VERSION "HNNBNNNYNNNNNNNNNNNNNNNNNNNNNNNNNNNNNNNNNN/4/%%%/4/'%**4NNN///"

NS_ :

BS_:

BU_: Airbag Allrad_Haldex BAP_Tester DCC_Gen3 EBKV_MQBW ESC_MQBW Gateway_Max Lenkhilfe_REPS

BO_ 2463978666 Motor_57: 32 Gateway_Max
 SG_ Motor_57_CRC : 0|8@1+ (1,0) [0|255] ""  Vector__XXX
 SG_ Motor_57_BZ : 8|4@1+ (1,0) [0|15] ""  Vector__XXX
 SG_ MO_EM1_Min_Spannung_Lim : 12|10@1+ (1,0) [0|1021] "Unit_Volt"  Vector__XXX
 SG_ MO_EM1_Max_Spannung_Lim : 22|10@1+ (1,0) [0|1021] "Unit_Volt"  Vector__XXX
 SG_ MO_EM1_Min_Leistung_Gesamt : 32|13@1+ (200,-819000) [-819000|818800] "Unit_Watt"  Vector__XXX
 SG_ MO_EM1_Max_Leistung_Gesamt : 45|13@1+ (200,-819000) [-819000|818800] "Unit_Watt"  Vector__XXX
 SG_ MO_EM2_Min_Leistung_Gesamt : 58|13@1+ (200,-819000) [-819000|818800] "Unit_Watt"  Vector__XXX
 SG_ MO_EM2_Max_Leistung_Gesamt : 71|13@1+ (200,-819000) [-819000|818800] "Unit_Watt"  Vector__XXX
 SG_ MO_EM2_Min_Spannung_Lim : 84|10@1+ (1,0) [0|1021] "Unit_Volt"  Vector__XXX
 SG_ MO_EM2_Max_Spannung_Lim : 94|10@1+ (1,0) [0|1021] "Unit_Volt"  Vector__XXX
 SG_ MO_EM1_Generator_Leistung : 104|8@1+ (100,0) [0|25300] "Unit_Watt"  Vector__XXX
 SG_ MO_EM2_Generator_Leistung : 112|8@1+ (100,0) [0|25300] "Unit_Watt"  Vector__XXX
 SG_ MO_Verbrauch_EM_Ges : 120|15@1+ (10,0) [0|327670] "Unit_WattSecond"  Vector__XXX
 SG_ MO_Verbrauch_EM_Ges_Ueberlauf : 135|1@1+ (1.0,0.0) [0.0|1] ""  Vector__XXX
 SG_ MO_Rekuperation_Ges_EM : 136|15@1+ (10,0) [0|327670] "Unit_WattSecond"  Vector__XXX
 SG_ MO_Rekuperation_EM_Ges_Ueberlauf : 151|1@1+ (1.0,0.0) [0.0|1] ""  Vector__XXX
 SG_ MO_Drehzahl_EM : 152|13@1+ (8,-32768) [-32768|32744] "Unit_RevPerMinute"  Airbag
 SG_ MO_Uebersetzung_EM : 165|10@1+ (0.03125,0) [0.03125|31.90625] ""  Vector__XXX
 SG_ MO_Drehzahl_EM_sek : 175|13@1+ (8,-32768) [-32768|32744] "Unit_RevPerMinute"  Airbag
 SG_ MO_Uebersetzung_EM_sek : 188|10@1+ (0.03125,0) [0.03125|31.90625] ""  Vector__XXX
 SG_ MO_TNW_Min_Spannung_Lim : 198|10@1+ (1,0) [0|1021] "Unit_Volt"  Vector__XXX
 SG_ MO_TNW_Max_Spannung_Lim : 208|10@1+ (1,0) [0|1021] "Unit_Volt"  Vector__XXX

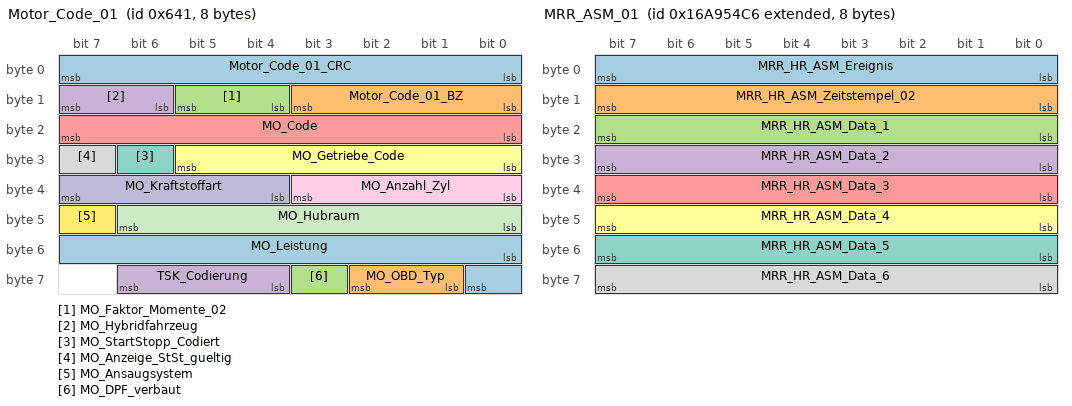
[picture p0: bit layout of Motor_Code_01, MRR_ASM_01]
BO_ 1601 Motor_Code_01: 8 Gateway_Max
 SG_ Motor_Code_01_CRC : 0|8@1+ (1,0) [0|255] ""  ESC_MQBW
 SG_ Motor_Code_01_BZ : 8|4@1+ (1,0) [0|15] ""  ESC_MQBW
 SG_ MO_Faktor_Momente_02 : 12|2@1+ (1,0) [1|3] "Unit_NewtoMeter"  Allrad_Haldex,DCC_Gen3,ESC_MQBW,Lenkhilfe_REPS
 SG_ MO_Hybridfahrzeug : 14|2@1+ (1.0,0.0) [0.0|3] ""  Vector__XXX
 SG_ MO_Code : 16|8@1+ (1,0) [0|255] ""  Vector__XXX
 SG_ MO_Getriebe_Code : 24|6@1+ (1.0,0.0) [0.0|63] ""  ESC_MQBW
 SG_ MO_StartStopp_Codiert : 30|1@1+ (1.0,0.0) [0.0|1] ""  ESC_MQBW
 SG_ MO_Anzeige_StSt_gueltig : 31|1@1+ (1.0,0.0) [0.0|1] ""  Vector__XXX
 SG_ MO_Anzahl_Zyl : 32|4@1+ (1.0,0.0) [0.0|15] ""  ESC_MQBW
 SG_ MO_Kraftstoffart : 36|4@1+ (1.0,0.0) [0.0|15] ""  Allrad_Haldex,ESC_MQBW
 SG_ MO_Hubraum : 40|7@1+ (0.1,0) [0.0|12.7] "Unit_Liter"  Vector__XXX
 SG_ MO_Ansaugsystem : 47|1@1+ (1.0,0.0) [0.0|1] ""  Vector__XXX
 SG_ MO_Leistung : 48|9@1+ (1,0) [0|511] "Unit_KiloWatt"  Allrad_Haldex
 SG_ MO_OBD_Typ : 57|2@1+ (1.0,0.0) [0.0|3] ""  EBKV_MQBW,ESC_MQBW
 SG_ MO_DPF_verbaut : 59|1@1+ (1.0,0.0) [0.0|1] ""  Vector__XXX
 SG_ TSK_Codierung : 60|3@1+ (1.0,0.0) [0.0|7] ""  Airbag

BO_ 2527679686 MRR_ASM_01: 8 Gateway_Max
 SG_ MRR_HR_ASM_Ereignis : 0|8@1+ (1,0) [1|254] ""  Airbag
 SG_ MRR_HR_ASM_Zeitstempel_02 : 8|8@1+ (0.04,0) [0.00|10.16] "Unit_Secon"  Airbag
 SG_ MRR_HR_ASM_Data_1 : 16|8@1+ (1,0) [0|255] ""  Airbag
 SG_ MRR_HR_ASM_Data_2 : 24|8@1+ (1,0) [0|255] ""  Airbag
 SG_ MRR_HR_ASM_Data_3 : 32|8@1+ (1,0) [0|255] ""  Airbag
 SG_ MRR_HR_ASM_Data_4 : 40|8@1+ (1,0) [0|255] ""  Airbag
 SG_ MRR_HR_ASM_Data_5 : 48|8@1+ (1,0) [0|255] ""  Airbag
 SG_ MRR_HR_ASM_Data_6 : 56|8@1+ (1,0) [0|255] ""  Airbag

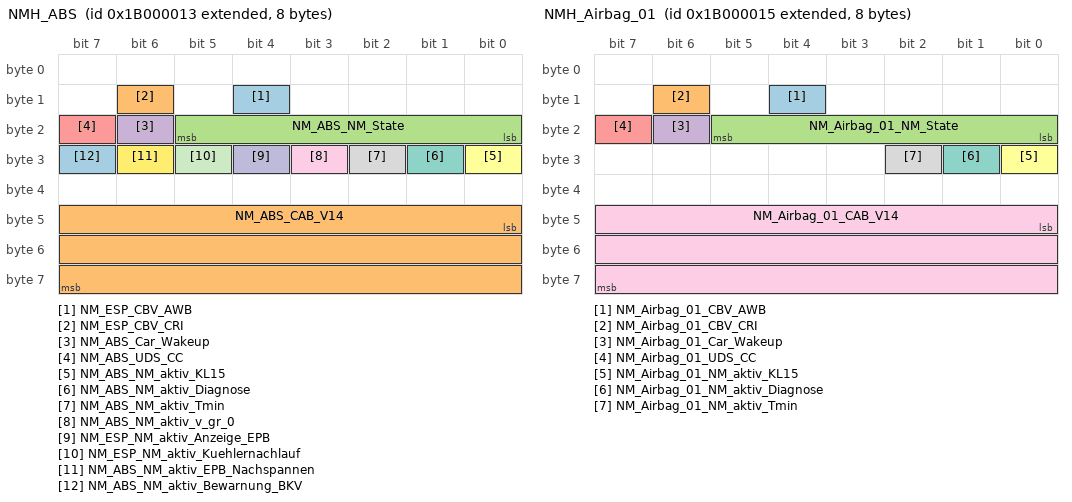
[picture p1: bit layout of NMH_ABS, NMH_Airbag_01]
BO_ 2600468499 NMH_ABS: 8 ESC_MQBW
 SG_ NM_ESP_CBV_AWB : 12|1@1+ (1.0,0.0) [0.0|1] ""  Gateway_Max
 SG_ NM_ESP_CBV_CRI : 14|1@1+ (1.0,0.0) [0.0|1] ""  Gateway_Max
 SG_ NM_ABS_NM_State : 16|6@1+ (1.0,0.0) [0.0|63] ""  Airbag,DCC_Gen3,EBKV_MQBW,Lenkhilfe_REPS
 SG_ NM_ABS_Car_Wakeup : 22|1@1+ (1.0,0.0) [0.0|1] ""  Gateway_Max
 SG_ NM_ABS_UDS_CC : 23|1@1+ (1.0,0.0) [0.0|1] ""  Vector__XXX
 SG_ NM_ABS_NM_aktiv_KL15 : 24|1@1+ (1.0,0.0) [0.0|1] ""  Vector__XXX
 SG_ NM_ABS_NM_aktiv_Diagnose : 25|1@1+ (1.0,0.0) [0.0|1] ""  Vector__XXX
 SG_ NM_ABS_NM_aktiv_Tmin : 26|1@1+ (1.0,0.0) [0.0|1] ""  Vector__XXX
 SG_ NM_ABS_NM_aktiv_v_gr_0 : 27|1@1+ (1.0,0.0) [0.0|1] ""  Vector__XXX
 SG_ NM_ESP_NM_aktiv_Anzeige_EPB : 28|1@1+ (1.0,0.0) [0.0|1] ""  Vector__XXX
 SG_ NM_ESP_NM_aktiv_Kuehlernachlauf : 29|1@1+ (1.0,0.0) [0.0|1] ""  Vector__XXX
 SG_ NM_ABS_NM_aktiv_EPB_Nachspannen : 30|1@1+ (1.0,0.0) [0.0|1] ""  Vector__XXX
 SG_ NM_ABS_NM_aktiv_Bewarnung_BKV : 31|1@1+ (1.0,0.0) [0.0|1] ""  Vector__XXX
 SG_ NM_ABS_CAB_V14 : 40|24@1+ (1.0,0.0) [0.0|16777215] ""  Gateway_Max

BO_ 2600468501 NMH_Airbag_01: 8 Airbag
 SG_ NM_Airbag_01_CBV_AWB : 12|1@1+ (1.0,0.0) [0.0|1] ""  Gateway_Max
 SG_ NM_Airbag_01_CBV_CRI : 14|1@1+ (1.0,0.0) [0.0|1] ""  Gateway_Max
 SG_ NM_Airbag_01_NM_State : 16|6@1+ (1.0,0.0) [0.0|63] ""  DCC_Gen3,EBKV_MQBW,ESC_MQBW,Lenkhilfe_REPS
 SG_ NM_Airbag_01_Car_Wakeup : 22|1@1+ (1.0,0.0) [0.0|1] ""  Gateway_Max
 SG_ NM_Airbag_01_UDS_CC : 23|1@1+ (1.0,0.0) [0.0|1] ""  Vector__XXX
 SG_ NM_Airbag_01_NM_aktiv_KL15 : 24|1@1+ (1.0,0.0) [0.0|1] ""  Vector__XXX
 SG_ NM_Airbag_01_NM_aktiv_Diagnose : 25|1@1+ (1.0,0.0) [0.0|1] ""  Vector__XXX
 SG_ NM_Airbag_01_NM_aktiv_Tmin : 26|1@1+ (1.0,0.0) [0.0|1] ""  Vector__XXX
 SG_ NM_Airbag_01_CAB_V14 : 40|24@1+ (1.0,0.0) [0.0|16777215] ""  Gateway_Max

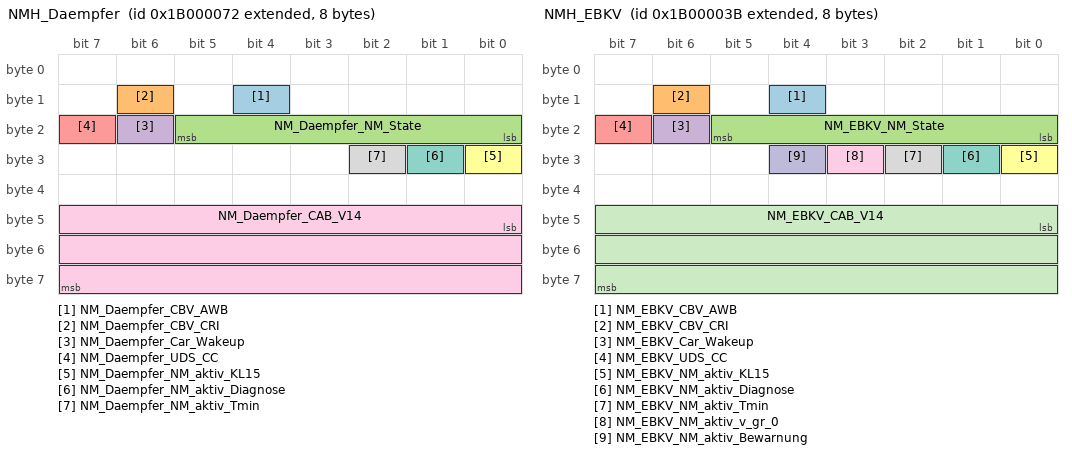
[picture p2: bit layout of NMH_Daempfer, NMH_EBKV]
BO_ 2600468594 NMH_Daempfer: 8 DCC_Gen3
 SG_ NM_Daempfer_CBV_AWB : 12|1@1+ (1.0,0.0) [0.0|1] ""  Gateway_Max
 SG_ NM_Daempfer_CBV_CRI : 14|1@1+ (1.0,0.0) [0.0|1] ""  Gateway_Max
 SG_ NM_Daempfer_NM_State : 16|6@1+ (1.0,0.0) [0.0|63] ""  Airbag,EBKV_MQBW,ESC_MQBW,Lenkhilfe_REPS
 SG_ NM_Daempfer_Car_Wakeup : 22|1@1+ (1.0,0.0) [0.0|1] ""  Gateway_Max
 SG_ NM_Daempfer_UDS_CC : 23|1@1+ (1.0,0.0) [0.0|1] ""  Vector__XXX
 SG_ NM_Daempfer_NM_aktiv_KL15 : 24|1@1+ (1.0,0.0) [0.0|1] ""  Vector__XXX
 SG_ NM_Daempfer_NM_aktiv_Diagnose : 25|1@1+ (1.0,0.0) [0.0|1] ""  Vector__XXX
 SG_ NM_Daempfer_NM_aktiv_Tmin : 26|1@1+ (1.0,0.0) [0.0|1] ""  Vector__XXX
 SG_ NM_Daempfer_CAB_V14 : 40|24@1+ (1.0,0.0) [0.0|16777215] ""  Gateway_Max

BO_ 2600468539 NMH_EBKV: 8 EBKV_MQBW
 SG_ NM_EBKV_CBV_AWB : 12|1@1+ (1.0,0.0) [0.0|1] ""  Gateway_Max
 SG_ NM_EBKV_CBV_CRI : 14|1@1+ (1.0,0.0) [0.0|1] ""  Gateway_Max
 SG_ NM_EBKV_NM_State : 16|6@1+ (1.0,0.0) [0.0|63] ""  Airbag,DCC_Gen3,ESC_MQBW,Lenkhilfe_REPS
 SG_ NM_EBKV_Car_Wakeup : 22|1@1+ (1.0,0.0) [0.0|1] ""  Gateway_Max
 SG_ NM_EBKV_UDS_CC : 23|1@1+ (1.0,0.0) [0.0|1] ""  Vector__XXX
 SG_ NM_EBKV_NM_aktiv_KL15 : 24|1@1+ (1.0,0.0) [0.0|1] ""  Vector__XXX
 SG_ NM_EBKV_NM_aktiv_Diagnose : 25|1@1+ (1.0,0.0) [0.0|1] ""  Vector__XXX
 SG_ NM_EBKV_NM_aktiv_Tmin : 26|1@1+ (1.0,0.0) [0.0|1] ""  Vector__XXX
 SG_ NM_EBKV_NM_aktiv_v_gr_0 : 27|1@1+ (1.0,0.0) [0.0|1] ""  Vector__XXX
 SG_ NM_EBKV_NM_aktiv_Bewarnung : 28|1@1+ (1.0,0.0) [0.0|1] ""  Vector__XXX
 SG_ NM_EBKV_CAB_V14 : 40|24@1+ (1.0,0.0) [0.0|16777215] ""  Gateway_Max

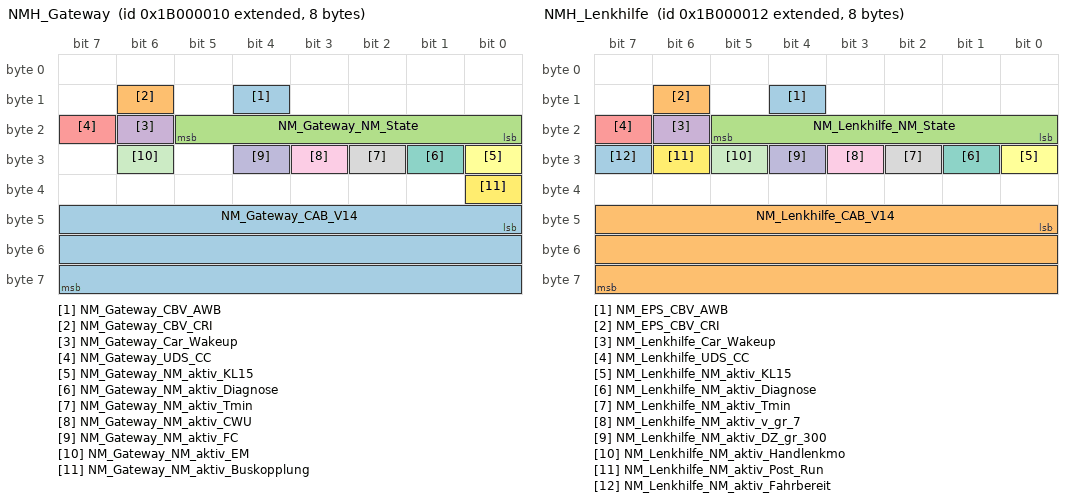
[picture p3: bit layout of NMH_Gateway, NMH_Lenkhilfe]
BO_ 2600468496 NMH_Gateway: 8 Gateway_Max
 SG_ NM_Gateway_CBV_AWB : 12|1@1+ (1.0,0.0) [0.0|1] ""  Vector__XXX
 SG_ NM_Gateway_CBV_CRI : 14|1@1+ (1.0,0.0) [0.0|1] ""  Vector__XXX
 SG_ NM_Gateway_NM_State : 16|6@1+ (1.0,0.0) [0.0|63] ""  Airbag,DCC_Gen3,EBKV_MQBW,ESC_MQBW,Lenkhilfe_REPS
 SG_ NM_Gateway_Car_Wakeup : 22|1@1+ (1.0,0.0) [0.0|1] ""  Vector__XXX
 SG_ NM_Gateway_UDS_CC : 23|1@1+ (1.0,0.0) [0.0|1] ""  Vector__XXX
 SG_ NM_Gateway_NM_aktiv_KL15 : 24|1@1+ (1.0,0.0) [0.0|1] ""  Vector__XXX
 SG_ NM_Gateway_NM_aktiv_Diagnose : 25|1@1+ (1.0,0.0) [0.0|1] ""  Vector__XXX
 SG_ NM_Gateway_NM_aktiv_Tmin : 26|1@1+ (1.0,0.0) [0.0|1] ""  Vector__XXX
 SG_ NM_Gateway_NM_aktiv_CWU : 27|1@1+ (1.0,0.0) [0.0|1] ""  Vector__XXX
 SG_ NM_Gateway_NM_aktiv_FC : 28|1@1+ (1.0,0.0) [0.0|1] ""  Vector__XXX
 SG_ NM_Gateway_NM_aktiv_EM : 30|1@1+ (1.0,0.0) [0.0|1] ""  Vector__XXX
 SG_ NM_Gateway_NM_aktiv_Buskopplung : 32|1@1+ (1.0,0.0) [0.0|1] ""  Vector__XXX
 SG_ NM_Gateway_CAB_V14 : 40|24@1+ (1.0,0.0) [0.0|16777215] ""  Vector__XXX

BO_ 2600468498 NMH_Lenkhilfe: 8 Lenkhilfe_REPS
 SG_ NM_EPS_CBV_AWB : 12|1@1+ (1.0,0.0) [0.0|1] ""  Gateway_Max
 SG_ NM_EPS_CBV_CRI : 14|1@1+ (1.0,0.0) [0.0|1] ""  Gateway_Max
 SG_ NM_Lenkhilfe_NM_State : 16|6@1+ (1.0,0.0) [0.0|63] ""  Airbag,DCC_Gen3,EBKV_MQBW,ESC_MQBW
 SG_ NM_Lenkhilfe_Car_Wakeup : 22|1@1+ (1.0,0.0) [0.0|1] ""  Gateway_Max
 SG_ NM_Lenkhilfe_UDS_CC : 23|1@1+ (1.0,0.0) [0.0|1] ""  Vector__XXX
 SG_ NM_Lenkhilfe_NM_aktiv_KL15 : 24|1@1+ (1.0,0.0) [0.0|1] ""  Vector__XXX
 SG_ NM_Lenkhilfe_NM_aktiv_Diagnose : 25|1@1+ (1.0,0.0) [0.0|1] ""  Vector__XXX
 SG_ NM_Lenkhilfe_NM_aktiv_Tmin : 26|1@1+ (1.0,0.0) [0.0|1] ""  Vector__XXX
 SG_ NM_Lenkhilfe_NM_aktiv_v_gr_7 : 27|1@1+ (1.0,0.0) [0.0|1] ""  Vector__XXX
 SG_ NM_Lenkhilfe_NM_aktiv_DZ_gr_300 : 28|1@1+ (1.0,0.0) [0.0|1] ""  Vector__XXX
 SG_ NM_Lenkhilfe_NM_aktiv_Handlenkmo : 29|1@1+ (1.0,0.0) [0.0|1] ""  Vector__XXX
 SG_ NM_Lenkhilfe_NM_aktiv_Post_Run : 30|1@1+ (1.0,0.0) [0.0|1] ""  Vector__XXX
 SG_ NM_Lenkhilfe_NM_aktiv_Fahrbereit : 31|1@1+ (1.0,0.0) [0.0|1] ""  Vector__XXX
 SG_ NM_Lenkhilfe_CAB_V14 : 40|24@1+ (1.0,0.0) [0.0|16777215] ""  Gateway_Max

BO_ 2621440531 OBDC_ABS_Req_FD: 64 Gateway_Max
 SG_ OBDC_ABS_Req_FD_Data : 0|512@1+ (1.0,0.0) [0.0|13407807929942597099574024998205846127479365820592393377723561443721764030073546976801874298166903427690031858186486050853753882811946569946433649006084095] ""  ESC_MQBW

BO_ 2621571603 OBDC_ABS_Resp_FD: 64 ESC_MQBW
 SG_ OBDC_ABS_Resp_FD_Data : 0|512@1+ (1.0,0.0) [0.0|13407807929942597099574024998205846127479365820592393377723561443721764030073546976801874298166903427690031858186486050853753882811946569946433649006084095] ""  Gateway_Max

BO_ 2621440533 OBDC_Airbag_01_Req_FD: 64 Gateway_Max
 SG_ OBDC_Airbag_01_Req_FD_Data : 0|512@1+ (1.0,0.0) [0.0|13407807929942597099574024998205846127479365820592393377723561443721764030073546976801874298166903427690031858186486050853753882811946569946433649006084095] ""  Airbag

BO_ 2621571605 OBDC_Airbag_01_Resp_FD: 64 Airbag
 SG_ OBDC_Airbag_01_Resp_FD_Data : 0|512@1+ (1.0,0.0) [0.0|13407807929942597099574024998205846127479365820592393377723561443721764030073546976801874298166903427690031858186486050853753882811946569946433649006084095] ""  Gateway_Max

BO_ 2621440527 OBDC_Allrad_Req_FD: 64 Gateway_Max
 SG_ OBDC_Allrad_Req_FD_Data : 0|512@1+ (1.0,0.0) [0.0|13407807929942597099574024998205846127479365820592393377723561443721764030073546976801874298166903427690031858186486050853753882811946569946433649006084095] ""  Allrad_Haldex

BO_ 2621571599 OBDC_Allrad_Resp_FD: 64 Allrad_Haldex
 SG_ OBDC_Allrad_Resp_FD_Data : 0|512@1+ (1.0,0.0) [0.0|13407807929942597099574024998205846127479365820592393377723561443721764030073546976801874298166903427690031858186486050853753882811946569946433649006084095] ""  Gateway_Max

BO_ 2621440626 OBDC_Daempfer_Req_FD: 64 Gateway_Max
 SG_ OBDC_Daempfer_Req_FD_Data : 0|512@1+ (1.0,0.0) [0.0|13407807929942597099574024998205846127479365820592393377723561443721764030073546976801874298166903427690031858186486050853753882811946569946433649006084095] ""  DCC_Gen3

BO_ 2621571698 OBDC_Daempfer_Resp_FD: 64 DCC_Gen3
 SG_ OBDC_Daempfer_Resp_FD_Data : 0|512@1+ (1.0,0.0) [0.0|13407807929942597099574024998205846127479365820592393377723561443721764030073546976801874298166903427690031858186486050853753882811946569946433649006084095] ""  Gateway_Max

BO_ 2621440571 OBDC_EBKV_Req_FD: 64 Gateway_Max
 SG_ OBDC_EBKV_Req_FD_Data : 0|512@1+ (1.0,0.0) [0.0|13407807929942597099574024998205846127479365820592393377723561443721764030073546976801874298166903427690031858186486050853753882811946569946433649006084095] ""  EBKV_MQBW

BO_ 2621571643 OBDC_EBKV_Resp_FD: 64 EBKV_MQBW
 SG_ OBDC_EBKV_Resp_FD_Data : 0|512@1+ (1.0,0.0) [0.0|13407807929942597099574024998205846127479365820592393377723561443721764030073546976801874298166903427690031858186486050853753882811946569946433649006084095] ""  Gateway_Max

BO_ 2621506048 OBDC_Funktionaler_Req_All_FD: 64 Gateway_Max
 SG_ OBDC_Funktion_Req_All_FD_Data : 0|512@1+ (1.0,0.0) [0.0|13407807929942597099574024998205846127479365820592393377723561443721764030073546976801874298166903427690031858186486050853753882811946569946433649006084095] ""  Airbag,Allrad_Haldex,DCC_Gen3,EBKV_MQBW,ESC_MQBW,Lenkhilfe_REPS

BO_ 2621440530 OBDC_Lenkhilfe_Req_FD: 64 Gateway_Max
 SG_ OBDC_Lenkhilfe_Req_FD_Data : 0|512@1+ (1.0,0.0) [0.0|13407807929942597099574024998205846127479365820592393377723561443721764030073546976801874298166903427690031858186486050853753882811946569946433649006084095] ""  Lenkhilfe_REPS

BO_ 2621571602 OBDC_Lenkhilfe_Resp_FD: 64 Lenkhilfe_REPS
 SG_ OBDC_Lenkhilfe_Resp_FD_Data : 0|512@1+ (1.0,0.0) [0.0|13407807929942597099574024998205846127479365820592393377723561443721764030073546976801874298166903427690031858186486050853753882811946569946433649006084095] ""  Gateway_Max

BO_ 2621440542 OBDC_Quersperre_Req_FD: 64 Gateway_Max
 SG_ OBDC_Quersperre_Req_FD_Data : 0|512@1+ (1.0,0.0) [0.0|13407807929942597099574024998205846127479365820592393377723561443721764030073546976801874298166903427690031858186486050853753882811946569946433649006084095] ""  Vector__XXX

BO_ 2621571614 OBDC_Quersperre_Resp_FD: 64 Vector__XXX
 SG_ OBDC_Quersperre_Resp_FD_Data : 0|512@1+ (1.0,0.0) [0.0|13407807929942597099574024998205846127479365820592393377723561443721764030073546976801874298166903427690031858186486050853753882811946569946433649006084095] ""  Gateway_Max

BO_ 2621469190 OBDC_SSN_eCS_Req_FD: 64 Gateway_Max
 SG_ OBDC_SSN_eCS_Req_FD_Data : 0|512@1+ (1.0,0.0) [0.0|13407807929942597099574024998205846127479365820592393377723561443721764030073546976801874298166903427690031858186486050853753882811946569946433649006084095] ""  Vector__XXX

BO_ 2621600262 OBDC_SSN_eCS_Resp_FD: 64 Vector__XXX
 SG_ OBDC_SSN_eCS_Resp_FD_Data : 0|512@1+ (1.0,0.0) [0.0|13407807929942597099574024998205846127479365820592393377723561443721764030073546976801874298166903427690031858186486050853753882811946569946433649006084095] ""  Gateway_Max

BO_ 2549903646 OBDC_SSN_RGS_HL_Req: 8 Gateway_Max
 SG_ OBDC_SSN_RGS_HL_Req_Data : 0|64@1+ (1.0,0.0) [0.0|18446744073709551615] ""  Vector__XXX

BO_ 2550034718 OBDC_SSN_RGS_HL_Resp: 8 Vector__XXX
 SG_ OBDC_SSN_RGS_HL_Resp_Data : 0|64@1+ (1.0,0.0) [0.0|18446744073709551615] ""  Gateway_Max

BO_ 2549903647 OBDC_SSN_RGS_HR_Req: 8 Gateway_Max
 SG_ OBDC_SSN_RGS_HR_Req_Data : 0|64@1+ (1.0,0.0) [0.0|18446744073709551615] ""  Vector__XXX

BO_ 2550034719 OBDC_SSN_RGS_HR_Resp: 8 Vector__XXX
 SG_ OBDC_SSN_RGS_HR_Resp_Data : 0|64@1+ (1.0,0.0) [0.0|18446744073709551615] ""  Gateway_Max

BO_ 2549903402 OBDC_SSN_RGS_VL_Req: 8 Gateway_Max
 SG_ OBDC_SSN_RGS_VL_Req_Data : 0|64@1+ (1.0,0.0) [0.0|18446744073709551615] ""  Vector__XXX

BO_ 2550034474 OBDC_SSN_RGS_VL_Resp: 8 Vector__XXX
 SG_ OBDC_SSN_RGS_VL_Resp_Data : 0|64@1+ (1.0,0.0) [0.0|18446744073709551615] ""  Gateway_Max

BO_ 2549903403 OBDC_SSN_RGS_VR_Req: 8 Gateway_Max
 SG_ OBDC_SSN_RGS_VR_Req_Data : 0|64@1+ (1.0,0.0) [0.0|18446744073709551615] ""  Vector__XXX

BO_ 2550034475 OBDC_SSN_RGS_VR_Resp: 8 Vector__XXX
 SG_ OBDC_SSN_RGS_VR_Resp_Data : 0|64@1+ (1.0,0.0) [0.0|18446744073709551615] ""  Gateway_Max

BO_ 2621440716 OBDC_TSplit_L_Req_FD: 64 Gateway_Max
 SG_ OBDC_TSplit_L_Req_FD_Data : 0|512@1+ (1.0,0.0) [0.0|13407807929942597099574024998205846127479365820592393377723561443721764030073546976801874298166903427690031858186486050853753882811946569946433649006084095] ""  Vector__XXX

BO_ 2621571788 OBDC_TSplit_L_Resp_FD: 64 Vector__XXX
 SG_ OBDC_TSplit_L_Resp_FD_Data : 0|512@1+ (1.0,0.0) [0.0|13407807929942597099574024998205846127479365820592393377723561443721764030073546976801874298166903427690031858186486050853753882811946569946433649006084095] ""  Gateway_Max

BO_ 2621440717 OBDC_TSplit_R_Req_FD: 64 Gateway_Max
 SG_ OBDC_TSplit_R_Req_FD_Data : 0|512@1+ (1.0,0.0) [0.0|13407807929942597099574024998205846127479365820592393377723561443721764030073546976801874298166903427690031858186486050853753882811946569946433649006084095] ""  Vector__XXX

BO_ 2621571789 OBDC_TSplit_R_Resp_FD: 64 Vector__XXX
 SG_ OBDC_TSplit_R_Resp_FD_Data : 0|512@1+ (1.0,0.0) [0.0|13407807929942597099574024998205846127479365820592393377723561443721764030073546976801874298166903427690031858186486050853753882811946569946433649006084095] ""  Gateway_Max

BO_ 2564424945 OBDx_ABS_Req: 8 Gateway_Max
 SG_ OBDx_ABS_Req_Data : 0|64@1+ (1.0,0.0) [0.0|18446744073709551615] ""  ESC_MQBW

BO_ 2564485380 OBDx_ABS_Resp: 8 ESC_MQBW
 SG_ OBDx_ABS_Resp_Data : 0|64@1+ (1.0,0.0) [0.0|18446744073709551615] ""  Gateway_Max

BO_ 2564502513 OBDx_allOBD_Req: 8 Gateway_Max
 SG_ OBDx_allOBD_Req_Data : 0|64@1+ (1.0,0.0) [0.0|18446744073709551615] ""  EBKV_MQBW,ESC_MQBW

BO_ 2564424689 OBDx_EBKV_Req: 8 Gateway_Max
 SG_ OBDx_EBKV_Req_Data : 0|64@1+ (1.0,0.0) [0.0|18446744073709551615] ""  EBKV_MQBW

BO_ 2564485379 OBDx_EBKV_Resp: 8 EBKV_MQBW
 SG_ OBDx_EBKV_Resp_Data : 0|64@1+ (1.0,0.0) [0.0|18446744073709551615] ""  Gateway_Max

BO_ 2589283656 ORU_01: 8 Gateway_Max
 SG_ ORU_Warnung : 58|2@1+ (1.0,0.0) [0.0|3] ""  Vector__XXX
 SG_ ORU_Status : 61|3@1+ (1.0,0.0) [0.0|7] ""  Airbag,Lenkhilfe_REPS

BO_ 525 PaCo_01: 16 Gateway_Max
 SG_ PaCo_01_Sendestatus : 12|1@1+ (1.0,0.0) [0.0|1] ""  Vector__XXX
 SG_ PaCo_APS_TargetState : 13|3@1+ (1.0,0.0) [0.0|7] ""  Vector__XXX
 SG_ PaCo_APSOPS_DetectionFront : 16|1@1+ (1.0,0.0) [0.0|1] ""  Vector__XXX
 SG_ PaCo_APSOPS_DetectionRear : 17|1@1+ (1.0,0.0) [0.0|1] ""  Vector__XXX
 SG_ PaCo_APSOPS_LED : 18|2@1+ (1.0,0.0) [0.0|3] ""  Vector__XXX
 SG_ PaCo_OPS_TargetState : 20|3@1+ (1.0,0.0) [0.0|7] ""  Vector__XXX
 SG_ PaCo_OPS_DrivingTube : 23|1@1+ (1.0,0.0) [0.0|1] ""  Vector__XXX
 SG_ PaCo_PLAIPA_InterventionStart : 24|1@1+ (1.0,0.0) [0.0|1] ""  Vector__XXX
 SG_ PaCo_PLAIPA_PLE : 25|1@1+ (1.0,0.0) [0.0|1] ""  Vector__XXX
 SG_ PaCo_PLAIPA_LED : 26|2@1+ (1.0,0.0) [0.0|3] ""  Vector__XXX
 SG_ PaCo_PLAIPA_TargetState : 28|4@1+ (1.0,0.0) [0.0|15] ""  Airbag
 SG_ PaCo_PLAIPA_SwitchParkSlot : 32|1@1+ (1.0,0.0) [0.0|1] ""  Vector__XXX
 SG_ PaCo_RBFMA_InterventionStrategy : 33|3@1+ (1.0,0.0) [0.0|7] ""  Vector__XXX
 SG_ PaCo_VPS_TargetView : 36|4@1+ (1.0,0.0) [0.0|15] ""  Vector__XXX
 SG_ PaCo_VPS_TargetMode : 40|4@1+ (1.0,0.0) [0.0|15] ""  Vector__XXX
 SG_ PaCo_VPS_LED : 44|2@1+ (1.0,0.0) [0.0|3] ""  Vector__XXX
 SG_ PaCo_VPS_TargetState : 46|2@1+ (1.0,0.0) [0.0|3] ""  Vector__XXX
 SG_ PaCo_VPS_TargetBirdview : 48|3@1+ (1.0,0.0) [0.0|7] ""  Vector__XXX
 SG_ PaCo_VPS_DarkenVideo : 51|1@1+ (1.0,0.0) [0.0|1] ""  Vector__XXX
 SG_ PaCo_VPS_PLE : 52|1@1+ (1.0,0.0) [0.0|1] ""  Vector__XXX
 SG_ PaCo_ARA_TargetState : 53|1@1+ (1.0,0.0) [0.0|1] ""  Vector__XXX
 SG_ PaCo_RCTA_InterventionStrategy : 54|2@1+ (1.0,0.0) [0.0|3] ""  Vector__XXX
 SG_ PaCo_MainState : 56|3@1+ (1.0,0.0) [0.0|7] ""  Vector__XXX
 SG_ PaCo_RCTA_Warning : 59|3@1+ (1.0,0.0) [0.0|7] ""  Vector__XXX
 SG_ PaCo_APS_AudioLowering : 62|1@1+ (1.0,0.0) [0.0|1] ""  Vector__XXX
 SG_ PaCo_VPS_TargetRVCscreen : 63|3@1+ (1.0,0.0) [0.0|7] ""  Vector__XXX
 SG_ PaCo_AAA_Intervention : 66|2@1+ (1.0,0.0) [0.0|3] ""  Vector__XXX
 SG_ PaCo_AAA_TargetState : 68|2@1+ (1.0,0.0) [0.0|3] ""  Vector__XXX
 SG_ PaCo_TPA_TargetState : 70|4@1+ (1.0,0.0) [0.0|15] ""  Vector__XXX
 SG_ PaCo_DiETa_LED : 74|2@1+ (1.0,0.0) [0.0|3] ""  Vector__XXX
 SG_ PaCo_VPS_TargetCarOverlay : 94|2@1+ (1.0,0.0) [0.0|3] ""  Vector__XXX
 SG_ PaCo_VPS_TargetBowl : 96|5@1+ (1.0,0.0) [0.0|31] ""  Vector__XXX
 SG_ PaCo_VPS_TargetGraphicOverlay : 101|4@1+ (1.0,0.0) [0.0|15] ""  Vector__XXX
 SG_ PaCo_RAB_TargetState : 115|3@1+ (1.0,0.0) [0.0|7] ""  Vector__XXX
 SG_ PaCo_AEBPR_InterventionStrategy : 118|1@1+ (1.0,0.0) [0.0|1] ""  Vector__XXX
 SG_ PaCo_AEBPR_ImplementationRBFMA : 120|1@1+ (1.0,0.0) [0.0|1] ""  Vector__XXX
 SG_ PaCo_RBFMA_ImplementationAEBPR : 121|1@1+ (1.0,0.0) [0.0|1] ""  Vector__XXX
 SG_ PaCo_ARA_InterventionStart : 124|1@1+ (1.0,0.0) [0.0|1] ""  Vector__XXX

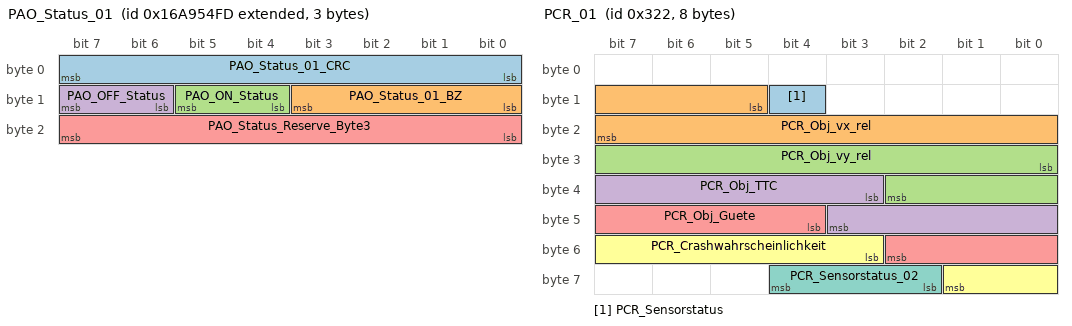
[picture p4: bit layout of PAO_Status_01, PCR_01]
BO_ 2527679741 PAO_Status_01: 3 Gateway_Max
 SG_ PAO_Status_01_CRC : 0|8@1+ (1,0) [0|255] ""  Airbag
 SG_ PAO_Status_01_BZ : 8|4@1+ (1,0) [0|15] ""  Airbag
 SG_ PAO_ON_Status : 12|2@1+ (1.0,0.0) [0.0|3] ""  Airbag
 SG_ PAO_OFF_Status : 14|2@1+ (1.0,0.0) [0.0|3] ""  Airbag
 SG_ PAO_Status_Reserve_Byte3 : 16|8@1+ (1.0,0.0) [0.0|255] ""  Vector__XXX

BO_ 518 Parken_01: 24 Gateway_Max
 SG_ Parken_01_CRC : 0|8@1+ (1,0) [0|255] ""  ESC_MQBW
 SG_ Parken_01_BZ : 8|4@1+ (1,0) [0|15] ""  ESC_MQBW
 SG_ Parken_BKD_Anf : 12|4@1+ (0.1,0) [0.0|1.3] "Unit_Secon"  Vector__XXX
 SG_ Parken_Verz_Anf : 16|7@1+ (0.1,-12.6) [-12.6|-0.1] "Unit_MeterPerSeconSquar"  ESC_MQBW
 SG_ Parken_Prefill_Anf : 23|1@1+ (1.0,0.0) [0.0|1] ""  Vector__XXX
 SG_ Parken_Warnruck_Anf : 24|2@1+ (1.0,0.0) [0.0|3] ""  ESC_MQBW
 SG_ Parken_Verz_Anf_ASIL : 26|2@1+ (1.0,0.0) [0.0|3] ""  ESC_MQBW
 SG_ Parken_Warnruckeln_Anf : 28|2@1+ (1.0,0.0) [0.0|3] ""  Vector__XXX
 SG_ Parken_beibehalten : 30|2@1+ (1.0,0.0) [0.0|3] ""  Vector__XXX
 SG_ Parken_Anforderung_HMS : 32|3@1+ (1.0,0.0) [0.0|7] ""  ESC_MQBW
 SG_ Parken_Fahrbereitschaft_Anf : 35|1@1+ (1.0,0.0) [0.0|1] ""  Vector__XXX
 SG_ Parken_Motorlauf_Anf : 36|2@1+ (1.0,0.0) [0.0|3] ""  Vector__XXX
 SG_ IPA_TPA_ausgerichtetes_Parken : 38|2@1+ (1.0,0.0) [0.0|3] ""  Vector__XXX
 SG_ Parken_Notstopp_Anf : 40|2@1+ (1.0,0.0) [0.0|3] ""  ESC_MQBW
 SG_ Parken_Anhalteweg_Anf : 42|10@1+ (0.01,0) [0.00|10.21] "Unit_Meter"  Vector__XXX
 SG_ Parken_aktives_System : 52|4@1+ (1.0,0.0) [0.0|15] ""  Vector__XXX
 SG_ Parken_max_Beschleunigung : 56|7@1+ (0.1,-6) [-5.9|6.1] "Unit_MeterPerSeconSquar"  Vector__XXX
 SG_ Parken_QFK_KruemmSoll : 64|15@1+ (0.0000067,0) [0E-7|0.2195389] "Unit_MeterInver"  Vector__XXX
 SG_ Parken_QFK_KruemmSoll_VZ : 79|1@1+ (1.0,0.0) [0.0|1] ""  Vector__XXX
 SG_ Parken_QFK_Spuerb : 80|8@1+ (0.4,0) [0.0|100.0] "Unit_PerCent"  Vector__XXX
 SG_ Parken_QFK_AnfStat : 88|4@1+ (1.0,0.0) [0.0|15] ""  Vector__XXX
 SG_ Parken_QFK_Signal1 : 92|10@1+ (1,0) [0|1023] ""  Vector__XXX
 SG_ Parken_QFK_Art1 : 102|3@1+ (1,0) [0|7] ""  Vector__XXX
 SG_ Parken_QFK_Art2 : 105|3@1+ (1,0) [0|7] ""  Vector__XXX
 SG_ Parken_QFK_Signal2 : 108|10@1+ (1,0) [0|1023] ""  Vector__XXX
 SG_ Parken_Sollbeschleunigung : 118|9@1+ (0.01,-4.11) [-4.10|1.00] "Unit_MeterPerSeconSquar"  Vector__XXX
 SG_ Parken_Status_IPA_TSK : 128|4@1+ (1.0,0.0) [0.0|15] ""  Vector__XXX
 SG_ Parken_erhoehtes_Moment : 132|4@1+ (1.0,0.0) [0.0|15] ""  Vector__XXX
 SG_ Parken_max_Geschwindigkeit : 136|8@1+ (0.1,0) [0.1|25.0] "Unit_KiloMeterPerHour"  Vector__XXX
 SG_ Parken_Soll_Anhalteweg_Anf : 144|10@1+ (0.01,0) [0.00|10.21] "Unit_Meter"  Vector__XXX
 SG_ Parken_Fahrstufenwunsch : 154|3@1+ (1.0,0.0) [0.0|7] ""  Vector__XXX
 SG_ Parken_Schleichfahrt_Anf : 157|1@1+ (1.0,0.0) [0.0|1] ""  Vector__XXX
 SG_ Parken_Bordstein_Winkel : 158|7@1+ (1,-1) [0|90] "Unit_DegreOfArc"  Vector__XXX
 SG_ IPA_TPA_Remote : 176|2@1+ (1.0,0.0) [0.0|3] ""  Vector__XXX
 SG_ IPA_TPA_Remote_Anf : 178|2@1+ (1.0,0.0) [0.0|3] ""  Vector__XXX
 SG_ IPA_TPA_Fehler : 180|4@1+ (1.0,0.0) [0.0|15] ""  Vector__XXX
 SG_ IPA_TPA_Abbruch : 184|4@1+ (1.0,0.0) [0.0|15] ""  Vector__XXX
 SG_ IPA_TPA_Status : 188|4@1+ (1.0,0.0) [0.0|15] ""  Vector__XXX

BO_ 2331595837 PCH_Object_01: 20 Gateway_Max
 SG_ PCH_Object_Class : 18|4@1+ (1.0,0.0) [0.0|15] ""  Airbag
 SG_ PCH_Object_vAbsX : 22|12@1+ (0.0625,-128) [-128.0000|127.8750] "Unit_MeterPerSecon"  Airbag
 SG_ PCH_Object_vAbsY : 34|12@1+ (0.0625,-128) [-128.0000|127.8750] "Unit_MeterPerSecon"  Airbag
 SG_ PCH_Kritikalitaetsklasse : 46|3@1+ (1.0,0.0) [0.0|7] ""  Airbag
 SG_ PCH_MessZeitpunkt : 49|13@1+ (0.001,0) [0.000|8.190] "Unit_Secon"  Airbag
 SG_ PCH_Status : 62|3@1+ (1.0,0.0) [0.0|7] ""  Airbag
 SG_ PCH_TTC : 65|13@1+ (0.001,0) [0.000|8.000] "Unit_Secon"  Airbag
 SG_ PCH_Object_aAbsX : 78|12@1+ (0.0625,-128) [-128.0000|127.8750] "Unit_MeterPerSeconSquar"  Airbag
 SG_ PCH_Object_aAbsY : 90|12@1+ (0.0625,-128) [-128.0000|127.8750] "Unit_MeterPerSeconSquar"  Airbag
 SG_ PCH_Object_Width : 102|8@1+ (0.03125,0) [0.00000|7.93750] "Unit_Meter"  Airbag
 SG_ PCH_Object_PosX : 110|14@1+ (0.03125,-200) [-200.00000|311.93750] "Unit_Meter"  Airbag
 SG_ PCH_Object_PosY : 124|13@1+ (0.03125,-128) [-128.00000|127.93750] "Unit_Meter"  Airbag

BO_ 802 PCR_01: 8 Gateway_Max
 SG_ PCR_Sensorstatus : 12|1@1+ (1.0,0.0) [0.0|1] ""  Vector__XXX
 SG_ PCR_Obj_vx_rel : 13|11@1+ (0.1,-102.3) [-102.3|102.3] "Unit_MeterPerSecon"  Airbag
 SG_ PCR_Obj_vy_rel : 24|11@1+ (0.1,-102.3) [-102.3|102.3] "Unit_MeterPerSecon"  Airbag
 SG_ PCR_Obj_TTC : 35|9@1+ (0.01,0) [0.00|5.10] "Unit_Secon"  Airbag
 SG_ PCR_Obj_Guete : 44|7@1+ (1,0) [0|100] "Unit_PerCent"  Airbag
 SG_ PCR_Crashwahrscheinlichkeit : 51|7@1+ (1,0) [0|100] "Unit_PerCent"  Airbag
 SG_ PCR_Sensorstatus_02 : 58|3@1+ (1.0,0.0) [0.0|7] ""  Airbag

BO_ 796 PCS_Li_01: 32 Gateway_Max
 SG_ PCS_Li_MessZeitpunkt : 12|13@1+ (0.001,0) [0.000|8.190] "Unit_Secon"  Airbag
 SG_ PCS_Li_CW : 28|7@1+ (1,0) [0|100] "Unit_PerCent"  Airbag
 SG_ PCS_Li_CW_Konfidenz : 35|7@1+ (1,0) [0|100] "Unit_PerCent"  Vector__XXX
 SG_ PCS_Li_CS : 42|7@1+ (1,0) [0|100] "Unit_PerCent"  Airbag
 SG_ PCS_Li_CS_Konfidenz : 49|7@1+ (1,0) [0|100] "Unit_PerCent"  Vector__XXX
 SG_ PCS_Li_TTC : 56|10@1+ (0.001,0) [0.000|1.000] "Unit_Secon"  Airbag
 SG_ PCS_Li_TTC_StdAbw : 66|7@1+ (0.001,0) [0.000|0.100] "Unit_Secon"  Vector__XXX
 SG_ PCS_Li_BlockID : 73|4@1+ (1,0) [0|15] "Unit_None"  Airbag
 SG_ PCS_Li_Status : 77|4@1+ (1.0,0.0) [0.0|15] ""  Airbag

BO_ 797 PCS_Re_01: 32 Gateway_Max
 SG_ PCS_Re_MessZeitpunkt : 12|13@1+ (0.001,0) [0.000|8.190] "Unit_Secon"  Airbag
 SG_ PCS_Re_CW : 28|7@1+ (1,0) [0|100] "Unit_PerCent"  Airbag
 SG_ PCS_Re_CW_Konfidenz : 35|7@1+ (1,0) [0|100] "Unit_PerCent"  Vector__XXX
 SG_ PCS_Re_CS : 42|7@1+ (1,0) [0|100] "Unit_PerCent"  Airbag
 SG_ PCS_Re_CS_Konfidenz : 49|7@1+ (1,0) [0|100] "Unit_PerCent"  Vector__XXX
 SG_ PCS_Re_TTC : 56|10@1+ (0.001,0) [0.000|1.000] "Unit_Secon"  Airbag
 SG_ PCS_Re_TTC_StdAbw : 66|7@1+ (0.001,0) [0.000|0.100] "Unit_Secon"  Vector__XXX
 SG_ PCS_Re_BlockID : 73|4@1+ (1,0) [0|15] "Unit_None"  Airbag
 SG_ PCS_Re_Status : 77|4@1+ (1.0,0.0) [0.0|15] ""  Airbag

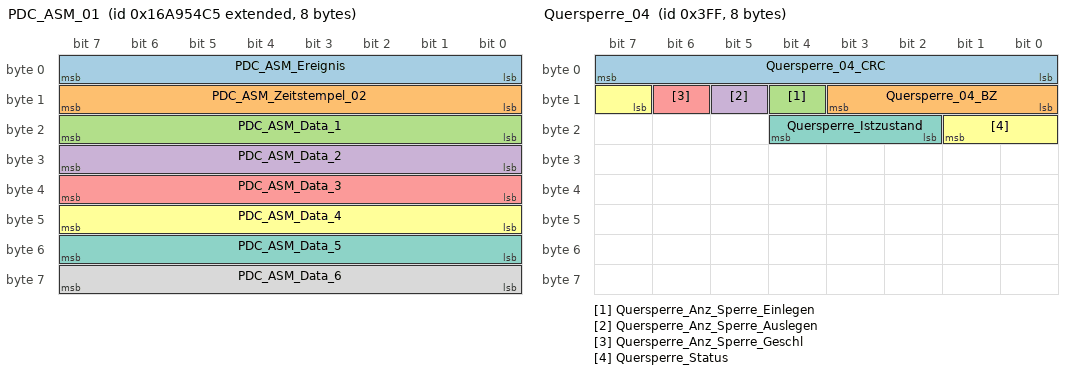
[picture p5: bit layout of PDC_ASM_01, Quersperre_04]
BO_ 2527679685 PDC_ASM_01: 8 Gateway_Max
 SG_ PDC_ASM_Ereignis : 0|8@1+ (1,0) [1|254] ""  Airbag
 SG_ PDC_ASM_Zeitstempel_02 : 8|8@1+ (0.04,0) [0.00|10.16] "Unit_Secon"  Airbag
 SG_ PDC_ASM_Data_1 : 16|8@1+ (1,0) [0|255] ""  Airbag
 SG_ PDC_ASM_Data_2 : 24|8@1+ (1,0) [0|255] ""  Airbag
 SG_ PDC_ASM_Data_3 : 32|8@1+ (1,0) [0|255] ""  Airbag
 SG_ PDC_ASM_Data_4 : 40|8@1+ (1,0) [0|255] ""  Airbag
 SG_ PDC_ASM_Data_5 : 48|8@1+ (1,0) [0|255] ""  Airbag
 SG_ PDC_ASM_Data_6 : 56|8@1+ (1,0) [0|255] ""  Airbag

BO_ 770 PLA_05: 24 Gateway_Max
 SG_ PLA_QFK_AnfStat : 12|4@1+ (1.0,0.0) [0.0|15] ""  Lenkhilfe_REPS
 SG_ PLA_QFK_Spuerb : 16|8@1+ (0.4,0) [0.0|100.0] "Unit_PerCent"  Lenkhilfe_REPS
 SG_ PLA_QFK_KruemmSoll : 24|15@1+ (0.0000067,0) [0E-7|0.2195389] "Unit_MeterInver"  Lenkhilfe_REPS
 SG_ PLA_QFK_KruemmSoll_VZ : 39|1@1+ (1.0,0.0) [0.0|1] ""  Lenkhilfe_REPS
 SG_ PLA_QFK_Signal1 : 40|10@1+ (1,0) [0|1023] ""  Lenkhilfe_REPS
 SG_ PLA_QFK_Art1 : 50|3@1+ (1,0) [0|7] ""  Lenkhilfe_REPS
 SG_ PLA_QFK_Art2 : 53|3@1+ (1,0) [0|7] ""  Lenkhilfe_REPS
 SG_ PLA_QFK_Signal2 : 56|10@1+ (1,0) [0|1023] ""  Lenkhilfe_REPS
 SG_ PLA_05_Sendestatus : 66|1@1+ (1.0,0.0) [0.0|1] ""  Lenkhilfe_REPS
 SG_ PLA_QFK_KrSoll_VZ : 67|1@1+ (1.0,0.0) [0.0|1] ""  Lenkhilfe_REPS
 SG_ PLA_QFK_KrSoll : 72|16@1+ (0.0000067,0) [0E-7|0.4390845] "Unit_MeterInver"  Lenkhilfe_REPS
 SG_ SOK_PLA_05_Signatur : 144|48@1+ (1,0) [0|281474976710655] "Unit_None"  Vector__XXX

BO_ 319 PreCrash_02: 8 Airbag
 SG_ PreCrash_Charisma_FahrPr : 12|4@1+ (1.0,0.0) [0.0|15] ""  Gateway_Max
 SG_ PreCrash_Charisma_Status : 16|2@1+ (1.0,0.0) [0.0|3] ""  Gateway_Max
 SG_ PreCrash_Schiebedach_schliessen : 18|1@1+ (1.0,0.0) [0.0|1] ""  Gateway_Max
 SG_ PreCrash_Fenster_schliessen : 19|1@1+ (1.0,0.0) [0.0|1] ""  Gateway_Max
 SG_ PreCrash_Blinken : 20|3@1+ (1.0,0.0) [0.0|7] ""  Gateway_Max
 SG_ SC_PreSense_FCWP : 23|1@1+ (1.0,0.0) [0.0|1] ""  Gateway_Max
 SG_ PreCrash_Tueren_Verriegeln : 24|1@1+ (1.0,0.0) [0.0|1] ""  Gateway_Max
 SG_ PreCrash_FS_Laengsverstellung : 25|1@1+ (1.0,0.0) [0.0|1] ""  Gateway_Max
 SG_ PreCrash_Anforderung_AFR : 26|3@1+ (1.0,0.0) [0.0|7] ""  Gateway_Max
 SG_ SC_PreCrash_LED : 29|2@1+ (1.0,0.0) [0.0|3] ""  Gateway_Max
 SG_ PreCrash_FS_Pneumatik_ansteuern : 31|1@1+ (1.0,0.0) [0.0|1] ""  Gateway_Max
 SG_ PreCrash_BFS_Pneumatik_ansteuern : 32|1@1+ (1.0,0.0) [0.0|1] ""  Gateway_Max
 SG_ PreCrash_Fo_Pneumatik_ansteuern : 33|1@1+ (1.0,0.0) [0.0|1] ""  Gateway_Max
 SG_ PreCrash_FS_Sitzlehne_verfahren : 34|3@1+ (1.0,0.0) [0.0|7] ""  Gateway_Max
 SG_ PreCrash_BFS_Sitzlehne_verfahren : 37|3@1+ (1.0,0.0) [0.0|7] ""  Gateway_Max
 SG_ PreCrash_Fo_Sitzlehne_verfahren : 40|3@1+ (1.0,0.0) [0.0|7] ""  Gateway_Max
 SG_ PreCrash_FS_KSV_verfahren : 43|4@1+ (1.0,0.0) [0.0|15] ""  Gateway_Max
 SG_ PreCrash_BFS_KSV_verfahren : 47|4@1+ (1.0,0.0) [0.0|15] ""  Gateway_Max
 SG_ PreCrash_Fo_KSV_verfahren : 51|4@1+ (1.0,0.0) [0.0|15] ""  Gateway_Max
 SG_ PreCrash_BFS_Laengsverstellung : 55|1@1+ (1.0,0.0) [0.0|1] ""  Gateway_Max
 SG_ SC_PreCrash_Warnung : 56|4@1+ (1.0,0.0) [0.0|15] ""  Gateway_Max
 SG_ SC_PreCrash_Texte : 60|4@1+ (1.0,0.0) [0.0|15] ""  Gateway_Max

BO_ 317 QFK_01_Auth: 32 Lenkhilfe_REPS
 SG_ QFK_01_CRC : 0|8@1+ (1,0) [0|255] ""  ESC_MQBW,Gateway_Max
 SG_ QFK_01_BZ : 8|4@1+ (1,0) [0|15] ""  ESC_MQBW,Gateway_Max
 SG_ QFK_01_Sendestatus : 12|1@1+ (1.0,0.0) [0.0|1] ""  ESC_MQBW,Gateway_Max
 SG_ QFK_stEingriffBr : 13|1@1+ (1.0,0.0) [0.0|1] ""  ESC_MQBW,Gateway_Max
 SG_ QFK_DynBegr_aktiv : 14|1@1+ (1.0,0.0) [0.0|1] ""  ESC_MQBW,Gateway_Max
 SG_ QFK_Anf_Giermomoffset_VZ : 15|1@1+ (1.0,0.0) [0.0|1] ""  ESC_MQBW,Gateway_Max
 SG_ QFK_Status : 16|4@1+ (1.0,0.0) [0.0|15] ""  ESC_MQBW,Gateway_Max
 SG_ QFK_stHCA : 20|4@1+ (1.0,0.0) [0.0|15] ""  Gateway_Max
 SG_ QFK_stPLA : 24|4@1+ (1.0,0.0) [0.0|15] ""  Gateway_Max
 SG_ QFK_stAWV : 28|4@1+ (1.0,0.0) [0.0|15] ""  Airbag,Gateway_Max
 SG_ QFK_stDSR : 32|4@1+ (1.0,0.0) [0.0|15] ""  ESC_MQBW,Gateway_Max
 SG_ QFK_ZPosIst_VZ : 36|1@1+ (1.0,0.0) [0.0|1] ""  Gateway_Max
 SG_ QFK_KrIst_VZ : 37|1@1+ (1.0,0.0) [0.0|1] ""  Gateway_Max
 SG_ QFK_IstKraft_VZ : 38|1@1+ (1.0,0.0) [0.0|1] ""  ESC_MQBW,Gateway_Max
 SG_ QFK_KruemmIst : 40|15@1+ (0.0000067,0) [0E-7|0.2195389] "Unit_MeterInver"  ESC_MQBW,Gateway_Max
 SG_ QFK_KruemmIst_VZ : 55|1@1+ (1.0,0.0) [0.0|1] ""  ESC_MQBW,Gateway_Max
 SG_ QFK_IstKraftNiveau : 56|7@1+ (1,0) [0|100] "Unit_PerCent"  ESC_MQBW,Gateway_Max
 SG_ QFK_IstKraftNiveau_VZ : 63|1@1+ (1.0,0.0) [0.0|1] ""  ESC_MQBW,Gateway_Max
 SG_ QFK_Anf_Giermomoffset : 64|12@1+ (0.65,0) [0.00|2661.75] "Unit_NewtoMeter"  ESC_MQBW,Gateway_Max
 SG_ QFK_ZPosIst : 76|16@1+ (0.00153,0) [0.00000|100.26702] "Unit_MilliMeter"  Gateway_Max
 SG_ QFK_stRHP : 92|4@1+ (1.0,0.0) [0.0|15] ""  Gateway_Max
 SG_ QFK_KrIst : 96|16@1+ (0.0000067,0) [0E-7|0.4390711] "Unit_MeterInver"  Gateway_Max
 SG_ QFK_IstKraft : 112|10@1+ (30,0) [0|30630] "Unit_Newto"  ESC_MQBW,Gateway_Max
 SG_ SOK_QFK_01_Signatur : 224|32@1+ (1,0) [0|4294967295] ""  Gateway_Max

BO_ 1023 Quersperre_04: 8 Gateway_Max
 SG_ Quersperre_04_CRC : 0|8@1+ (1,0) [0|255] ""  Vector__XXX
 SG_ Quersperre_04_BZ : 8|4@1+ (1,0) [0|15] ""  Vector__XXX
 SG_ Quersperre_Anz_Sperre_Einlegen : 12|1@1+ (1.0,0.0) [0.0|1] ""  Vector__XXX
 SG_ Quersperre_Anz_Sperre_Auslegen : 13|1@1+ (1.0,0.0) [0.0|1] ""  Vector__XXX
 SG_ Quersperre_Anz_Sperre_Geschl : 14|1@1+ (1.0,0.0) [0.0|1] ""  Vector__XXX
 SG_ Quersperre_Status : 15|3@1+ (1.0,0.0) [0.0|7] ""  Vector__XXX
 SG_ Quersperre_Istzustand : 18|3@1+ (1.0,0.0) [0.0|7] ""  Vector__XXX

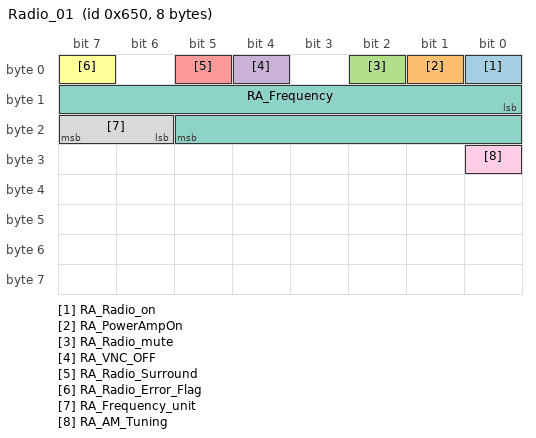
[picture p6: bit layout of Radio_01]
BO_ 1616 Radio_01: 8 Gateway_Max
 SG_ RA_Radio_on : 0|1@1+ (1,0) [0|1] ""  Vector__XXX
 SG_ RA_PowerAmpOn : 1|1@1+ (1,0) [0|1] ""  Vector__XXX
 SG_ RA_Radio_mute : 2|1@1+ (1,0) [0|1] ""  Vector__XXX
 SG_ RA_VNC_OFF : 4|1@1+ (1,0) [0|1] ""  Vector__XXX
 SG_ RA_Radio_Surround : 5|1@1+ (1,0) [0|1] ""  Vector__XXX
 SG_ RA_Radio_Error_Flag : 7|1@1+ (1.0,0.0) [0.0|1] ""  Vector__XXX
 SG_ RA_Frequency : 8|14@1+ (1,0) [0|16383] "Unit_None"  Vector__XXX
 SG_ RA_Frequency_unit : 22|2@1+ (1.0,0.0) [0.0|3] ""  Vector__XXX
 SG_ RA_AM_Tuning : 24|1@1+ (1.0,0.0) [0.0|1] ""  Vector__XXX

BO_ 695 RCTA_01: 8 Gateway_Max
 SG_ RCTA_01_CRC : 0|8@1+ (1,0) [0|255] ""  Vector__XXX
 SG_ RCTA_01_BZ : 8|4@1+ (1,0) [0|15] ""  Vector__XXX
 SG_ RCTA_PaCo_MainState : 12|3@1+ (1.0,0.0) [0.0|7] ""  Vector__XXX
 SG_ RCTA_Status_FoD : 22|2@1+ (1.0,0.0) [0.0|3] ""  Vector__XXX
 SG_ RCTA_PaCo_BrakeIntervention : 24|2@1+ (1.0,0.0) [0.0|3] ""  Vector__XXX
 SG_ RCTA_PaCo_UnavailableReason : 26|3@1+ (1.0,0.0) [0.0|7] ""  Vector__XXX
 SG_ RCTA_Anf_Warnruck : 29|2@1+ (1.0,0.0) [0.0|3] ""  Vector__XXX
 SG_ RCTA_Modus : 31|3@1+ (1.0,0.0) [0.0|7] ""  Vector__XXX
 SG_ RCTA_Kritikalitaetslevel_rechts : 34|3@1+ (1.0,0.0) [0.0|7] ""  Vector__XXX
 SG_ RCTA_Kritikalitaetslevel_links : 37|3@1+ (1.0,0.0) [0.0|7] ""  Vector__XXX
 SG_ RCTA_Info_rechts : 40|3@1+ (1.0,0.0) [0.0|7] ""  Vector__XXX
 SG_ RCTA_Anforderung_HMS : 43|3@1+ (1.0,0.0) [0.0|7] ""  ESC_MQBW
 SG_ RCTA_Bremsruck_Anforderung : 46|1@1+ (1.0,0.0) [0.0|1] ""  Vector__XXX
 SG_ RCTA_Bremsruck_Freigabe : 47|1@1+ (1.0,0.0) [0.0|1] ""  Vector__XXX
 SG_ RCTA_Info_links : 48|3@1+ (1.0,0.0) [0.0|7] ""  Vector__XXX
 SG_ RCTA_PaCo_BrakingPossible : 51|1@1+ (1.0,0.0) [0.0|1] ""  Vector__XXX
 SG_ RCTA_Status : 52|2@1+ (1.0,0.0) [0.0|3] ""  Vector__XXX
 SG_ RCTA_Warnton : 54|1@1+ (1.0,0.0) [0.0|1] ""  Vector__XXX
 SG_ RCTA_Notbremsung_Freigabe : 55|1@1+ (1.0,0.0) [0.0|1] ""  ESC_MQBW
 SG_ RCTA_Notbremsung_Anforderung : 56|8@1+ (0.078,-19.812) [-19.734|0.000] "Unit_MeterPerSeconSquar"  ESC_MQBW

CM_ BO_ 1601 "ab MQB mit CRC-8";
CM_ BO_ 2621506048 "VDC funktionaler Request auf CANFD";
CM_ BO_ 695 "Rear Cross Traffic Assist";

CM_ SG_ 2463978666 MO_Drehzahl_EM "Effektivdrehzahl, die am E-Maschinenausgang ermittelt wird, die für die Primärachse zur Verfügung steht";
CM_ SG_ 2463978666 MO_Drehzahl_EM_sek "Effektivdrehzahl, die am E-Maschinenausgang ermittelt wird, die für die Sekundärachse zur Verfügung steht";
CM_ SG_ 2463978666 MO_EM1_Generator_Leistung "elektrische Wunschleistung zur Berechnung eines momentan erforderlichen Moments im Generatorbetrieb";
CM_ SG_ 2463978666 MO_EM1_Max_Leistung_Gesamt "im Gesamtsystem verfügbare elektrische Leistung für den motorischen Betrieb; elektrische Leistung zur Berechnung eines momentan möglichen";
CM_ SG_ 2463978666 MO_EM1_Max_Spannung_Lim "maximal zulässige HV-Spannung (DC), die von der LE im generatorischen Betrieb nicht überschritten werden darf; Abregelspannung zur Begrenzung des minimalen Moments im generatorischen Betrieb";
CM_ SG_ 2463978666 MO_EM1_Min_Leistung_Gesamt "vom Gesamtsystem aufnehmbare elektrische Leistung für den generatorischen Betrieb (betragsmäßig maximal aber i.d.R. negativ, daher ‚Min‘); elektrische Leistung zur Berechnung eines momentan möglichen minimalen Moments (maximal genaratorisch)";
CM_ SG_ 2463978666 MO_EM1_Min_Spannung_Lim "minimal zulässige HV-Spannung (DC), die von der LE im motorischen Betrieb nicht unterschritten werden darf; Abregelspannung zur Begrenzung des maximalen Moments im motorischen Betrieb";
CM_ SG_ 2463978666 MO_EM2_Generator_Leistung "elektrische Wunschleistung zur Berechnung eines momentan erforderlichen Moments im Generatorbetrieb";
CM_ SG_ 2463978666 MO_EM2_Max_Leistung_Gesamt "im Gesamtsystem verfügbare elektrische Leistung für den motorischen Betrieb; elektrische Leistung zur Berechnung eines momentan möglichen";
CM_ SG_ 2463978666 MO_EM2_Max_Spannung_Lim "maximal zulässige HV-Spannung (DC), die von der LE im generatorischen Betrieb nicht überschritten werden darf; Abregelspannung zur Begrenzung des minimalen Moments im generatorischen Betrieb";
CM_ SG_ 2463978666 MO_EM2_Min_Leistung_Gesamt "vom Gesamtsystem aufnehmbare elektrische Leistung für den generatorischen Betrieb (betragsmäßig maximal aber i.d.R. negativ, daher ‚Min‘); elektrische Leistung zur Berechnung eines momentan möglichen minimalen Moments (maximal genaratorisch)";
CM_ SG_ 2463978666 MO_EM2_Min_Spannung_Lim "minimal zulässige HV-Spannung (DC), die von der LE im motorischen Betrieb nicht unterschritten werden darf; Abregelspannung zur Begrenzung des maximalen Moments im motorischen Betrieb";
CM_ SG_ 2463978666 MO_Rekuperation_EM_Ges_Ueberlauf "Rekuperationleistungssignal mindest 1x übergelaufen";
CM_ SG_ 2463978666 MO_Rekuperation_Ges_EM "Rekuperation-Energie des Antriebs";
CM_ SG_ 2463978666 MO_TNW_Max_Spannung_Lim "maximal zulässige HV-Spannung (DC), die vom TNW (Traktionsnetzwandler) im generatorischen Betrieb nicht überschritten werden darf";
CM_ SG_ 2463978666 MO_TNW_Min_Spannung_Lim "minimal zulässige HV-Spannung (DC), die von dem TNW (Traktionsnetzwandler) im motorischen Betrieb nicht unterschritten werden darf";
CM_ SG_ 2463978666 MO_Uebersetzung_EM "Übersetzung von MO_Drehzahl_EM zur Primärachse, wenn eine Verbindung sicher hergestellt ist";
CM_ SG_ 2463978666 MO_Uebersetzung_EM_sek "Übersetzung von MO_Drehzahl_EM_sek zur Sekundärachse, wenn eine Verbindung sicher hergestellt ist";
CM_ SG_ 2463978666 MO_Verbrauch_EM_Ges "Antriebs-Energie des Antriebs";
CM_ SG_ 2463978666 MO_Verbrauch_EM_Ges_Ueberlauf "Verbrauchssignal mindest 1x übergelaufen";
CM_ SG_ 2463978666 Motor_57_BZ "4bit Botschaftszähler, wird mit jeder Sendebotschaft inkrementiert";
CM_ SG_ 2463978666 Motor_57_CRC "Für MLB:
Berechnung siehe Lastenheft 'Kommunikationsabsicherung für FlexRay und CAN'
Ab MQB und MLBevo:
Berechnung siehe Lastenheft 'End-to-End Kommunikationsabsicherung'

Endwerte siehe Begleitdokument 'S-PDU Kennungsfolgen'";

CM_ SG_ 1601 MO_Ansaugsystem "Art des Ansaugsystems des Verbrennungsmotors";
CM_ SG_ 1601 MO_Anzahl_Zyl "Zylinderzahl des Verbrennungsmotors";
CM_ SG_ 1601 MO_Anzeige_StSt_gueltig "Zeigt die Gültigkeit der neuen StSt-Anzeigesignale an, MO_Anzeige_StSt_Text und  MO_Anzeige_Symbol. Mo_Text_Motorstart 1..5 sind zu ignorieren.";
CM_ SG_ 1601 MO_Code "Motorcodierinformation Version 16 (Details siehe Anhang)";
CM_ SG_ 1601 MO_DPF_verbaut "Verbauinformation Diesel-Partikel-Filter
";
CM_ SG_ 1601 MO_Faktor_Momente_02 "Dieses Signal schaltet den Wertebereich aller Momente vom Motor, Getriebe, TSK, Bremse ... um! Die Momente besitzen somit einen variablen Wertebereich, weil sich durch den Faktor die Momente sowohl in Auflösung als auch Maximalwerten ändert.

0x0 nicht ";
CM_ SG_ 1601 MO_Getriebe_Code "Getriebecodierung des Motors";
CM_ SG_ 1601 MO_Hubraum "Hubraum des Verbrennungsmotors";
CM_ SG_ 1601 MO_Hybridfahrzeug "Anhand dieses Signals plausibilisiert die Lenkhilfe das Bit Fahrbereitschaft.

Im Projekt Cayenne PHEV (und ggf. auch VW526 PHEV) ist aus Gründen der Abwärtskompatibilität der Wert '2' zu senden.";
CM_ SG_ 1601 MO_Kraftstoffart "Primärkraftstoff zum Antrieb des Fahrzeugs";
CM_ SG_ 1601 MO_Leistung "Nennleistung des Verbrennungsmotors

Im reinen E-Fahrzeug (BEV): Ausgabe der elektrischen Systemleistung";
CM_ SG_ 1601 MO_OBD_Typ "Abgastyp OBD
Hinweis: In Fahrzeugen mit dem Zielmarkt China und einer Zertifizierung ab China 6 muss auf dem Signal 'MO_OBD_Typ' der Wert 'US_OBD' gesendet werden.";
CM_ SG_ 1601 MO_StartStopp_Codiert "Funktion StartStopp im aktuellen Klemmenzyklus verbaut";
CM_ SG_ 1601 Motor_Code_01_CRC "Für MLB:
'Berechnung siehe Lastenheft 'Kommunikationsabsicherung für FlexRay und CAN''

Ab MQB und MLBevo:
'Berechnung siehe Lastenheft 'End-to-End Kommunikationsabsicherung''

Endwerte siehe Begleitdokument 'S-PDU Kennungsfolgen'";
CM_ SG_ 1601 TSK_Codierung "Information über den plausibilisierten Codierungszustand des Triebstrangskoordinators auf ACC oder GRA.";

CM_ SG_ 2527679686 MRR_HR_ASM_Data_1 "Dieses Signal wird von MRR_HR befüllt und an den Assistenzsystemmonitor ASM (Host SG: Safety Computer) gesendet.";
CM_ SG_ 2527679686 MRR_HR_ASM_Data_2 "Dieses Signal wird von MRR_HR befüllt und an den Assistenzsystemmonitor ASM (Host SG: Safety Computer) gesendet.";
CM_ SG_ 2527679686 MRR_HR_ASM_Data_3 "Dieses Signal wird von MRR_HR befüllt und an den Assistenzsystemmonitor ASM (Host SG: Safety Computer) gesendet.";
CM_ SG_ 2527679686 MRR_HR_ASM_Data_4 "Dieses Signal wird von MRR_HR befüllt und an den Assistenzsystemmonitor ASM (Host SG: Safety Computer) gesendet.";
CM_ SG_ 2527679686 MRR_HR_ASM_Data_5 "Dieses Signal wird von MRR_HR befüllt und an den Assistenzsystemmonitor ASM (Host SG: Safety Computer) gesendet.";
CM_ SG_ 2527679686 MRR_HR_ASM_Data_6 "Dieses Signal wird von MRR_HR befüllt und an den Assistenzsystemmonitor ASM (Host SG: Safety Computer) gesendet.";
CM_ SG_ 2527679686 MRR_HR_ASM_Ereignis "Dieses Signal definiert, welche Funktion und welche Art von Aktivität das Senden der Botschaft an den Assistenzsystemmonitor ASM veranlasst hat.";
CM_ SG_ 2527679686 MRR_HR_ASM_Zeitstempel_02 "Dieses Signal ermöglicht die zeitliche Zuordnung der von mehreren Funktionen auf dem MRR an den Assistenzsystemmonitor ASM gesendeten Statusbot-schaften.";

CM_ SG_ 2600468499 NM_ABS_CAB_V14 "CAB = Clusteraktivbits (V14)

Cluster CAB_01_Antrieb
- Aktive Bremsenkühlung mit Kühlerlüfter angefordert (nur nach Bergabfahrt) für 10min

Cluster CAB_06_Anzeige:
- Schalter der Elektrischen Parkbremse gedrückt: Parkbremse anziehen, Handbremslampe ";
CM_ SG_ 2600468499 NM_ABS_Car_Wakeup "Car Wakeup (Gateway wertet aus)

MQB: 
-EPB-Lampe wird bei 'Kl. 15 aus' für die Dauer von 30 Sekunden eingeschaltet (Bit bleibt solange gesetzt)

MQB2020:
-Geschwindigkeitssignal V>0 erkannt (nur nachlaufend)

E3_1_1:
-Geschwindigkeitssignal V>0 ";
CM_ SG_ 2600468499 NM_ABS_NM_aktiv_Bewarnung_BKV "Bus gefordert zur Anzeige Warnung Bremskraftverstärker bei Kl.-15";
CM_ SG_ 2600468499 NM_ABS_NM_aktiv_Diagnose "Diagnose befindet sich nach VW80124 in einer NonDefaultDiagnostic-Session, z.B. ExtendedDiagnostic-Session";
CM_ SG_ 2600468499 NM_ABS_NM_aktiv_EPB_Nachspannen "Bus gefordert, weil zum Erhalt der Spannkraft die Hinterradbremse nachgespannt werden muss";
CM_ SG_ 2600468499 NM_ABS_NM_aktiv_KL15 "Steuergerät hat KL15-EIN erkannt";
CM_ SG_ 2600468499 NM_ABS_NM_aktiv_Tmin "Mindestaktivzeit ist noch nicht abgelaufen (bei jedem Weckereignis wird die Mindestaktivzeit neu gestartet)";
CM_ SG_ 2600468499 NM_ABS_NM_aktiv_v_gr_0 "Bus gefordert, weil die Bremse nicht den Stillstand aller Räder erkannt hat";
CM_ SG_ 2600468499 NM_ABS_NM_State "1 = Zustand Repeat Message (<-- Bus-Sleep Mode)
2 = Zustand Repeat Message (<-- Prepare Bus-Sleep Mode)
4 = Zustand Normal Operation (<-- Repeat Message)
8 = Zustand Normal Operation (<-- Ready Sleep)";
CM_ SG_ 2600468499 NM_ABS_UDS_CC "Funktionseinschränkung aufgrund aktivem UDS-Communication Control, siehe VW80124";
CM_ SG_ 2600468499 NM_ESP_CBV_AWB "Das Signal ist zu setzen, wenn das SG aktiv den Bus geweckt hat";
CM_ SG_ 2600468499 NM_ESP_CBV_CRI "Das Signal ist dauerhaft gesetzt, wenn das NM-Layout dem neuen NM-Layout für Teilnetzbetrieb entspricht";
CM_ SG_ 2600468499 NM_ESP_NM_aktiv_Anzeige_EPB "Bus gefordert, weil EPB-Lampe im Kombi angezeigt werden muss";
CM_ SG_ 2600468499 NM_ESP_NM_aktiv_Kuehlernachlauf "Aktiv aufgrund Kuehlernachlauf";

CM_ SG_ 2600468501 NM_Airbag_01_CAB_V14 "CAB = Clusteraktivbits (V14)

Cluster - CAB_05_Komfort
- Anwesenheitserkennung (Trigger durch Sitzbelegungserkennung und/oder Gurtschlosserkennung Fahrer)";
CM_ SG_ 2600468501 NM_Airbag_01_Car_Wakeup "Car Wakeup (Gateway wertet aus)
MQB: Klemme 15 ist unplausibel (Kl.-15 HW ist ein, Kl.-15 SW aus) und muss dem Fahrer angezeigt werden (dauerhaft)";
CM_ SG_ 2600468501 NM_Airbag_01_CBV_AWB "Das Signal ist zu setzen, wenn das SG aktiv den Bus geweckt hat
0 = Passiver_WakeUp = SG hat das Netzwerk nicht aktiv geweckt
1 = Akitiver_WakeUp = SG hat das Netzwerk aktiv geweckt";
CM_ SG_ 2600468501 NM_Airbag_01_CBV_CRI "Das Signal ist dauerhaft gesetzt, wenn das NM-Layout Cluster- Anforderungen enthält";
CM_ SG_ 2600468501 NM_Airbag_01_NM_aktiv_Diagnose "Diagnose befindet sich nach VW80124 in einer NonDefaultDiagnostic-Session, z.B. ExtendedDiagnostic-Session";
CM_ SG_ 2600468501 NM_Airbag_01_NM_aktiv_KL15 "Steuergerät hat KL15-EIN erkannt";
CM_ SG_ 2600468501 NM_Airbag_01_NM_aktiv_Tmin "Mindestaktivzeit ist noch nicht abgelaufen (bei jedem Weckereignis wird die Mindestaktivzeit neu gestartet)";
CM_ SG_ 2600468501 NM_Airbag_01_NM_State "1 = Zustand Repeat Message (<-- Bus-Sleep Mode)
2 = Zustand Repeat Message (<-- Prepare Bus-Sleep Mode)
4 = Zustand Normal Operation (<-- Repeat Message)
8 = Zustand Normal Operation (<-- Ready Sleep)";
CM_ SG_ 2600468501 NM_Airbag_01_UDS_CC "Funktionseinschränkung aufgrund aktivem UDS-Communication Control, siehe VW80124";

CM_ SG_ 2600468594 NM_Daempfer_CAB_V14 "CAB = Clusteraktivbits (V14)";
CM_ SG_ 2600468594 NM_Daempfer_Car_Wakeup "Car Wakeup (Gateway wertet aus)";
CM_ SG_ 2600468594 NM_Daempfer_CBV_AWB "Das Signal ist zu setzen, wenn das SG aktiv den Bus geweckt hat";
CM_ SG_ 2600468594 NM_Daempfer_CBV_CRI "Das Signal ist dauerhaft gesetzt, wenn das NM-Layout dem neuen NM-Layout für Teilnetzbetrieb entspricht";
CM_ SG_ 2600468594 NM_Daempfer_NM_aktiv_Diagnose "Diagnose befindet sich nach VW80124 in einer NonDefaultDiagnostic-Session, z.B. ExtendedDiagnostic-Session";
CM_ SG_ 2600468594 NM_Daempfer_NM_aktiv_KL15 "Steuergerät hat KL15-EIN erkannt";
CM_ SG_ 2600468594 NM_Daempfer_NM_aktiv_Tmin "Mindestaktivzeit ist noch nicht abgelaufen (bei jedem Weckereignis wird die Mindestaktivzeit neu gestartet)";
CM_ SG_ 2600468594 NM_Daempfer_NM_State "1 = Zustand Repeat Message (<-- Bus-Sleep Mode)
2 = Zustand Repeat Message (<-- Prepare Bus-Sleep Mode)
4 = Zustand Normal Operation (<-- Repeat Message)
8 = Zustand Normal Operation (<-- Ready Sleep)";
CM_ SG_ 2600468594 NM_Daempfer_UDS_CC "Funktionseinschränkung aufgrund aktivem UDS-Communication Control; siehe VW80124";

CM_ SG_ 2600468539 NM_EBKV_CAB_V14 "CAB = Clusteraktivbits (V14)

Cluster CAB_06_Anzeige
- ESC und Anzeigecluster für Fahrerwarung wachhalten bzw. wecken (4sec)";
CM_ SG_ 2600468539 NM_EBKV_Car_Wakeup "Car Wakeup (Gateway wertet aus)
MQB: Nach Zündung aus Bewarnung des Fahrers über Verringerung der Bremskraftverstärkung ('Feststellbremse betätigen'; 'Einschränkung Bremswirkung'). Signal wird für <30 Sekunden gesetzt.";
CM_ SG_ 2600468539 NM_EBKV_CBV_AWB "Das Signal ist zu setzen, wenn das SG aktiv den Bus geweckt hat";
CM_ SG_ 2600468539 NM_EBKV_CBV_CRI "Das Signal ist dauerhaft gesetzt, wenn das NM-Layout dem neuen NM-Layout für Teilnetzbetrieb entspricht";
CM_ SG_ 2600468539 NM_EBKV_NM_aktiv_Bewarnung "Bus gefordert bei aktiver Bewarnung";
CM_ SG_ 2600468539 NM_EBKV_NM_aktiv_Diagnose "Diagnose befindet sich nach VW80124 in einer NonDefaultDiagnostic-Session, z.B. ExtendedDiagnostic-Session";
CM_ SG_ 2600468539 NM_EBKV_NM_aktiv_KL15 "Steuergerät hat KL15-EIN erkannt";
CM_ SG_ 2600468539 NM_EBKV_NM_aktiv_Tmin "Mindestaktivzeit ist noch nicht abgelaufen (bei jedem Weckereignis wird die Mindestaktivzeit neu gestartet)";
CM_ SG_ 2600468539 NM_EBKV_NM_aktiv_v_gr_0 "Bus gefordert bei Geschwindigkeit > 0 km/h";
CM_ SG_ 2600468539 NM_EBKV_NM_State "1 = Zustand Repeat Message (<-- Bus-Sleep Mode)
2 = Zustand Repeat Message (<-- Prepare Bus-Sleep Mode)
4 = Zustand Normal Operation (<-- Repeat Message)
8 = Zustand Normal Operation (<-- Ready Sleep)
16 = Zustand Repeat Message (<-- Ready Sleep)
32 ";
CM_ SG_ 2600468539 NM_EBKV_UDS_CC "Funktionseinschränkung aufgrund aktivem UDS-Communication Control; siehe VW80124";

CM_ SG_ 2600468496 NM_Gateway_CAB_V14 "CAB = Clusteraktivbits (V14)

Cluster CAB_01_Antrieb
-Innenraumklimatisierung starten
-Ladevorbedingung, Beginn des Ladens, Ende
-Lademodusänderung, Timer-Laden vs. Sofort Laden

Cluster CAB_02_Hybrid_Laden
-Laden an oder ausschalten
-Ladevorbedi";
CM_ SG_ 2600468496 NM_Gateway_Car_Wakeup "Car Wakeup (Subbusmaster wertet aus)

MQB: 
-Diagnose- oder Komponentenschutzmaster-Funktion weckt den schlafenden Subbus (z.B. MOST)

E3_Volumen:
- Diagnose aktiv -aktive Diagnosekommunikation am OBD-Stecker

MQBw_Baseline:
- Diagnose aktiv -akt";
CM_ SG_ 2600468496 NM_Gateway_CBV_AWB "Das Signal ist zu setzen, wenn das SG aktiv den Bus geweckt hat
0 = Passiver_WakeUp = SG hat das Netzwerk nicht aktiv geweckt
1 = Akitiver_WakeUp = SG hat das Netzwerk aktiv geweckt";
CM_ SG_ 2600468496 NM_Gateway_CBV_CRI "Das Signal ist dauerhaft gesetzt, wenn das NM-Layout Cluster- Anforderungen enthält";
CM_ SG_ 2600468496 NM_Gateway_NM_aktiv_Buskopplung "Nachlauf aufgrund Kopplung zweier Busse. z.B. K-CAN und K2-CAN";
CM_ SG_ 2600468496 NM_Gateway_NM_aktiv_CWU "Nachlauf aufgrund CWU Anforderung";
CM_ SG_ 2600468496 NM_Gateway_NM_aktiv_Diagnose "Diagnose befindet sich nach VW80124 in einer NonDefaultDiagnostic-Session, z.B. ExtendedDiagnostic-Session";
CM_ SG_ 2600468496 NM_Gateway_NM_aktiv_EM "Nachlauf aufgrund Energiemanagement";
CM_ SG_ 2600468496 NM_Gateway_NM_aktiv_FC "Nachlauf aufgrund Funktionscluster Anforderung";
CM_ SG_ 2600468496 NM_Gateway_NM_aktiv_KL15 "Steuergerät hat KL15-EIN erkannt";
CM_ SG_ 2600468496 NM_Gateway_NM_aktiv_Tmin "Mindestaktivzeit ist noch nicht abgelaufen (bei jedem Weckereignis wird die Mindestaktivzeit neu gestartet)";
CM_ SG_ 2600468496 NM_Gateway_NM_State "1 = Zustand Repeat Message (<-- Bus-Sleep Mode)
2 = Zustand Repeat Message (<-- Prepare Bus-Sleep Mode)
4 = Zustand Normal Operation (<-- Repeat Message)
8 = Zustand Normal Operation (<-- Ready Sleep)";
CM_ SG_ 2600468496 NM_Gateway_UDS_CC "Funktionseinschränkung aufgrund aktivem UDS-Communication Control, siehe VW80124";

CM_ SG_ 2600468498 NM_EPS_CBV_AWB "Das Signal ist zu setzen, wenn das SG aktiv den Bus geweckt hat";
CM_ SG_ 2600468498 NM_EPS_CBV_CRI "Das Signal ist dauerhaft gesetzt, wenn das NM-Layout dem neuen NM-Layout für Teilnetzbetrieb entspricht";
CM_ SG_ 2600468498 NM_Lenkhilfe_CAB_V14 "CAB = Clusteraktivbits (V14)";
CM_ SG_ 2600468498 NM_Lenkhilfe_Car_Wakeup "Car Wakeup (Gateway wertet aus)
";
CM_ SG_ 2600468498 NM_Lenkhilfe_NM_aktiv_Diagnose "Diagnose befindet sich nach VW80124 in einer NonDefaultDiagnostic-Session, z.B. ExtendedDiagnostic-Session";
CM_ SG_ 2600468498 NM_Lenkhilfe_NM_aktiv_DZ_gr_300 "Bus gefordert bei Drehzahl > 300 1/min";
CM_ SG_ 2600468498 NM_Lenkhilfe_NM_aktiv_Fahrbereit "Bus gefordert bei erkannter Fahrbereitschaft (Hybrid/Elektro)";
CM_ SG_ 2600468498 NM_Lenkhilfe_NM_aktiv_Handlenkmo "Bus gefordert bei anliegendem Handlenkmoment";
CM_ SG_ 2600468498 NM_Lenkhilfe_NM_aktiv_KL15 "Steuergerät hat KL15-EIN erkannt";
CM_ SG_ 2600468498 NM_Lenkhilfe_NM_aktiv_Post_Run "Bus gefordert bei Post Run";
CM_ SG_ 2600468498 NM_Lenkhilfe_NM_aktiv_Tmin "Mindestaktivzeit ist noch nicht abgelaufen (bei jedem Weckereignis wird die Mindestaktivzeit neu gestartet)";
CM_ SG_ 2600468498 NM_Lenkhilfe_NM_aktiv_v_gr_7 "Bus gefordert bei Geschwindigkeit > 7 km/h";
CM_ SG_ 2600468498 NM_Lenkhilfe_NM_State "1 = Zustand Repeat Message (<-- Bus-Sleep Mode)
2 = Zustand Repeat Message (<-- Prepare Bus-Sleep Mode)
4 = Zustand Normal Operation (<-- Repeat Message)
8 = Zustand Normal Operation (<-- Ready Sleep)";
CM_ SG_ 2600468498 NM_Lenkhilfe_UDS_CC "Funktionseinschränkung aufgrund aktivem UDS-Communication Control, siehe VW80124";

CM_ SG_ 2621440531 OBDC_ABS_Req_FD_Data "OnBoard Tester Diagnose Request ABS";

CM_ SG_ 2621571603 OBDC_ABS_Resp_FD_Data "OnBoard Tester Diagnose Response ABS";

CM_ SG_ 2621440533 OBDC_Airbag_01_Req_FD_Data "OnBoard Tester Diagnose Request Airbag_01";

CM_ SG_ 2621571605 OBDC_Airbag_01_Resp_FD_Data "OnBoard Tester Diagnose Response Airbag_01";

CM_ SG_ 2621440527 OBDC_Allrad_Req_FD_Data "OnBoard Tester Diagnose Request Allrad.";

CM_ SG_ 2621571599 OBDC_Allrad_Resp_FD_Data "OnBoard Tester Diagnose Response Allrad.";

CM_ SG_ 2621440626 OBDC_Daempfer_Req_FD_Data "TP-Kanal für den Onboard Datensammler";

CM_ SG_ 2621571698 OBDC_Daempfer_Resp_FD_Data "TP-Kanal für den Onboard Datensammler";

CM_ SG_ 2621440571 OBDC_EBKV_Req_FD_Data "OnBoard Tester Diagnose Request EBKV.";

CM_ SG_ 2621571643 OBDC_EBKV_Resp_FD_Data "OnBoard Tester Diagnose Response EBKV.";

CM_ SG_ 2621506048 OBDC_Funktion_Req_All_FD_Data "OnBoard Tester funktionaler Diagnose Request ALL";

CM_ SG_ 2621440530 OBDC_Lenkhilfe_Req_FD_Data "OnBoard Tester Diagnose Request FD Lenkhilfe.";

CM_ SG_ 2621571602 OBDC_Lenkhilfe_Resp_FD_Data "OnBoard Tester Diagnose Response FD Lenkhilfe.";

CM_ SG_ 2621440542 OBDC_Quersperre_Req_FD_Data "OnBoard Tester Diagnose Request FD Quersperre.";

CM_ SG_ 2621571614 OBDC_Quersperre_Resp_FD_Data "OnBoard Tester Diagnose Response FD Quersperre.";

CM_ SG_ 2621469190 OBDC_SSN_eCS_Req_FD_Data "Request FID- zu NA- Kommunikation zw. OnboardDiagnoseClient und DK2F Sub-System";

CM_ SG_ 2621600262 OBDC_SSN_eCS_Resp_FD_Data "Response FID- zu NA- Kommunikation zw. OnboardDiagnoseClient und DK2F Sub-System";

CM_ SG_ 2549903646 OBDC_SSN_RGS_HL_Req_Data "OnBoard Tester Diagnose Request RGS_HL";

CM_ SG_ 2550034718 OBDC_SSN_RGS_HL_Resp_Data "OnBoard Tester Diagnose Response RGS_HL";

CM_ SG_ 2549903647 OBDC_SSN_RGS_HR_Req_Data "OnBoard Tester Diagnose Request RGS_HR";

CM_ SG_ 2550034719 OBDC_SSN_RGS_HR_Resp_Data "OnBoard Tester Diagnose Response RGS_HR";

CM_ SG_ 2549903402 OBDC_SSN_RGS_VL_Req_Data "OnBoard Tester Diagnose Request RGS_VL";

CM_ SG_ 2550034474 OBDC_SSN_RGS_VL_Resp_Data "OnBoard Tester Diagnose Response RGS_VL";

CM_ SG_ 2549903403 OBDC_SSN_RGS_VR_Req_Data "OnBoard Tester Diagnose Request RGS_VR";

CM_ SG_ 2550034475 OBDC_SSN_RGS_VR_Resp_Data "OnBoard Tester Diagnose Response RGS_VR";

CM_ SG_ 2564424945 OBDx_ABS_Req_Data "29bit OBD Diagnose";

CM_ SG_ 2564485380 OBDx_ABS_Resp_Data "29bit OBD Diagnose";

CM_ SG_ 2564502513 OBDx_allOBD_Req_Data "Generic Scan Tool funktionaler Diagnose Request ALL OBD";

CM_ SG_ 2564424689 OBDx_EBKV_Req_Data "29bit OBD Diagnose";

CM_ SG_ 2564485379 OBDx_EBKV_Resp_Data "29bit OBD Diagnose";

CM_ SG_ 2589283656 ORU_Status "Verteilung des internen ORU Zustandes";
CM_ SG_ 2589283656 ORU_Warnung "Wenn durch Störungen der Funktion Online Remote Update nicht sichergestellt ist, dass vor Kunde keine Funktionseinschränkungen auftreten, muss der Benutzer des Fahrzeugs entsprechend gewarnt werden.";

CM_ SG_ 525 PaCo_01_Sendestatus "Gibt den Sendestatus der Botschaft PaCo_01 an (notwendig für IL-Unterstützung)";
CM_ SG_ 525 PaCo_AAA_Intervention "Fahrfreigabe des Kunden.";
CM_ SG_ 525 PaCo_AAA_TargetState "Sollzustand der Kundenfunktion AAA.";
CM_ SG_ 525 PaCo_AEBPR_ImplementationRBFMA "Über dieses Signal wird die Information, ob RBF im Fahrzeug verbaut ist, an die Funktion AEB-PR gesendet.";
CM_ SG_ 525 PaCo_AEBPR_InterventionStrategy "Signal controls AEB-PR function activation";
CM_ SG_ 525 PaCo_APS_AudioLowering "Steuerung der Anforderung der Audioabsenkung

0 Inactive: Die Kundenfunktion APS fordert keine Audioabsenkung bei der Tonausgabe an
1 Active: Die Kundenfunktion APS fordert eine Audioabsenkung bei der Tonausgabe an";
CM_ SG_ 525 PaCo_APS_TargetState "Sollzustand der APS-Funktion.

0 APS_Inactive: APS darf den Fahrer nicht vor Hindernissen warnen.
1 APS_Active: APS muss den Fahrer gemäß seiner Warnstrategie vor Hindernissen warnen.
2 APS_Active_ReducedRange: APS muss den Fahrer mit Hilfe von Warntö";
CM_ SG_ 525 PaCo_APSOPS_DetectionFront "control of obstacle detection in the front
0 Detection_Inactive: APSOPS shall not display obtacles in the front
1 Detection_Active: APSOPS shall display obstacles in the front";
CM_ SG_ 525 PaCo_APSOPS_DetectionRear "control of obstacle detectionin the rear
0 Detection_Inactive: APSOPS shall not display obtacles in the rear
1 Detection_Active: APSOPS shall display obstacles in the rear";
CM_ SG_ 525 PaCo_APSOPS_LED "Steuerung des Zustandes der Funktionsbeleuchtung im PDC-Hardkey.

0 LED_Inactive: Die Funktionsbeleuchtung im PDC-Hardkey muss leuchten
1 LED_Active: Die Funktionsbeleuchtung im PDC-Hardkey darf nicht leuchten
2 LED_Flashing: Die Funktionsbeleuchtung ";
CM_ SG_ 525 PaCo_ARA_InterventionStart "Initiierung der aktiven Regelung der Funktion ARA

Inactive: ARA darf die Regelung nicht übernehmen
Active: ARA muss die Regelung gemäß der ARA-Funktionsstrategie übernehmen";
CM_ SG_ 525 PaCo_ARA_TargetState "Sollzustand der Kundenfunktion ARA

0 Inactive: ARA übernimmt nicht die Querführung des Fahrzeugs und ermöglicht dem Fahrer nicht die Einstellung des Sollknickwinkels
1 Active: ARA übernimmt die Querführung des Fahrzeugs und ermöglicht dem Fahrer die E";
CM_ SG_ 525 PaCo_DiETa_LED "Ansteuerung der Funktionsbeleuchtung im Direkteinstiegstaster ('DiETa') durch den Parking Coordinator ('PaCo').

0 LED_Inactive: Die Funktionsbeleuchtung im DiETa_Parken muss leuchten
1 LED_Active: Die Funktionsbeleuchtung im DiETa_Parken darf nicht le";
CM_ SG_ 525 PaCo_MainState "Hauptzustand des ParkingCoordinator

0 Init: PaCo befindet sich in der Initialisierung
1 InOperation_NoError: PaCo befindet sich im Betrieb ohne Fehler
7 Fehler: PaCo befindet sich im Fehlerzustand";
CM_ SG_ 525 PaCo_OPS_DrivingTube "Steuerung der Übertragung von Fahrschlauchinformationen.

0 Inactive: OPS darf derzeit keine Fahrschlauchinformationen an die Headunit übertragen
1 Active: OPS muss derzeit Fahrschlauchinformationen an die Headunit übertragen";
CM_ SG_ 525 PaCo_OPS_TargetState "Target state of function OPS
0 = function is inactive
1 = function is active
2 = function is active but muted";
CM_ SG_ 525 PaCo_PLAIPA_InterventionStart "Initiierung des aktiven Parkvorgangs

0 Inactive: PLA/IPA darf die Führung des Fahrzeugs für den aktiven Parkvorgang nicht übernehmen
1 Active: PLA/IPA muss die Führung des Fahrzeugs für den aktiven Parkvorgang gemäß der PLA/IPA-Funktionsstrategie über";
CM_ SG_ 525 PaCo_PLAIPA_LED "Steuerung des Zustandes der Funktionsbeleuchtung im PLA/IPA-Hardkey.

0 LED_Inactive: Die Funktionsbeleuchtung im PLA/IPA-Hardkey muss leuchten
1 LED_Active: Die Funktionsbeleuchtung im PLA/IPA-Hardkey darf nicht leuchten
2 LED_Flashing: Die Funktions";
CM_ SG_ 525 PaCo_PLAIPA_PLE "Steuerung des Zustandes der Parklückeneinblendung (PLE)

0 Inactive: PLA/IPA überträgt keine Koordinaten für PLE an die Kamera
1 Active: PLA/IPA überträgt Koordinaten für PLE an die Kamera";
CM_ SG_ 525 PaCo_PLAIPA_SwitchParkSlot "Steuerung zur Übermittlung der Aufforderung an PLA/IPA dem Fahrer die nächste Parklücke anzubieten

0 NotToggle_ToNextParkingSlot: PLA/IPA darf dem Fahrer nicht die nächste Parklücke anbieten
1 Toggle_ToNextParkingSlot: PLA/IPA muss dem Fahrer die näch";
CM_ SG_ 525 PaCo_PLAIPA_TargetState "Sollzustand der Kundenfunktion PLA/IPA

0 Inactive: PLA/IPA ist inakiv vor Kunde
1 Active_Visible: PLA/IPA ist gemäß der PLA/IPA-Funktionsstrategie aktiv vor Kunde
2 DeactBy_NoReason: PLA/IPA muss sich deaktivieren und anschließend inaktiv vor Kunde s";
CM_ SG_ 525 PaCo_RAB_TargetState "Sollzustand der Kundenfunktion RA";
CM_ SG_ 525 PaCo_RBFMA_ImplementationAEBPR "Dieses Signal übermittelt der Rangierbremsfunktion, ob AEB-PR im Fahrzeug verbaut ist.";
CM_ SG_ 525 PaCo_RBFMA_InterventionStrategy "Steuerung der Eingriffstrategie von RBF/MA.

0 No_Intervention: RBF/MA muss inaktiv vor Kunde sein und darf keine Eingriffe durchführen
1 Only_Braking: RBF/MA muss den Fahrer durch Bremseingriff gemäß der RBF/MA-Warnstrategie unterstützen und darf den ";
CM_ SG_ 525 PaCo_RCTA_InterventionStrategy "Steuerung der Eingriffstrategie der RCTA-Funktion

0 No_Intervention: RCTA muss inaktiv vor Kunde sein und darf keine Eingriffe durchführen
1 Braking: RCTA muss dem Fahrer eine Unterstützung durch Bremseingriff gemäß der RCTA-Warnstrategie anbieten";
CM_ SG_ 525 PaCo_RCTA_Warning "control of RCTA warning output
0=RCTA_Inactive
1=RCTA_Active
2=RCTA_Active_Muted
3=RCTA_Off";
CM_ SG_ 525 PaCo_TPA_TargetState "Sollzustand der Kundenfunktion TPA


0 Inactive: TPA ist inakiv vor Kunde
1 Active_Visible: TPA ist gemäß der TPA-Funktionsstrategie aktiv vor Kunde
2 DeactBy_NoReason: PLA/IPA muss sich deaktivieren und anschließend inaktiv vor Kunde sein
8 DeactBy";
CM_ SG_ 525 PaCo_VPS_DarkenVideo "Steuerung der Schwarzschaltung von VPS

0 Inactive: VPS schaltet das Videobild nicht schwarz
1 Active: VPS schaltet das Videobild schwarz";
CM_ SG_ 525 PaCo_VPS_LED "Steuerung des Zustandes der Funktionsbeleuchtung im VPS-Hardkey.

0 LED_Inactive: Die Funktionsbeleuchtung im VPS-Hardkey muss leuchten
1 LED_Active: Die Funktionsbeleuchtung im VPS-Hardkey darf nicht leuchten
2 LED_Flashing: Die Funktionsbeleuchtung ";
CM_ SG_ 525 PaCo_VPS_PLE "Steuerung des Zustandes der Parklückeneinblendung (PLE)

0 Inactive: VPS blendet keine Parklücken für PLE im Videobild ein
1 Active: VPS blendet Parklücken für PLE im Videobild ein";
CM_ SG_ 525 PaCo_VPS_TargetBirdview "Target-Birdview of the  VPS-Function";
CM_ SG_ 525 PaCo_VPS_TargetBowl "Control of the 3D view direction";
CM_ SG_ 525 PaCo_VPS_TargetCarOverlay "Control of the overlay on the vehicle pictogram 0=noCarOverlay 1=normalCarOverlay 2=transparentCarOverlay";
CM_ SG_ 525 PaCo_VPS_TargetGraphicOverlay "Control of the graphical overlay on the video image";
CM_ SG_ 525 PaCo_VPS_TargetMode "Target-Mode of the VPS-Function";
CM_ SG_ 525 PaCo_VPS_TargetRVCscreen "Signal zum Umschalten der Rearview Ansicht

Werte:
0x0=NoScreen
0x1=Fullscreen
0x2=Side-by-Side / Splitscreen";
CM_ SG_ 525 PaCo_VPS_TargetState "Target-State of the VPS-Function";
CM_ SG_ 525 PaCo_VPS_TargetView "Target-View of the  VPS-Function";

CM_ SG_ 2527679741 PAO_OFF_Status "Istwert für LED 'OFF' in Anzeige Passenger Airbag On/Off";
CM_ SG_ 2527679741 PAO_ON_Status "Istwert für LED 'ON' in Anzeige Passenger Airbag On/Off";
CM_ SG_ 2527679741 PAO_Status_01_BZ "4bit Botschaftszähler, wird mit jeder Sendebotschaft inkrementiert";
CM_ SG_ 2527679741 PAO_Status_01_CRC "Für MLB:
Berechnung siehe Lastenheft 'Kommunikationsabsicherung für FlexRay und CAN'
Ab MQB und MLBevo:
Berechnung siehe Lastenheft 'End-to-End Kommunikationsabsicherung'

Endwerte siehe Begleitdokument 'S-PDU Kennungsfolgen'";
CM_ SG_ 2527679741 PAO_Status_Reserve_Byte3 "Zweck: Befüllen der reservierten Bitpositionen mit 0 (wg. LIN-Teilnehmer)";

CM_ SG_ 518 IPA_TPA_Abbruch "Signalisierung eines durch IPA erkannten Abbruchs mit Angabe des Grundes";
CM_ SG_ 518 IPA_TPA_ausgerichtetes_Parken "signalisiert TPA, ob ausgerichtetes Einparken aktiv ist";
CM_ SG_ 518 IPA_TPA_Fehler "Signalisierung eines durch IPA erkannten Fehlers mit Angabe der Fehlerart";
CM_ SG_ 518 IPA_TPA_Remote "Status hinsichtlich Umschaltung auf fernbedienten Parkvorgang";
CM_ SG_ 518 IPA_TPA_Remote_Anf "Anforderung für bzw. bei fernbedienten Parkvorgang";
CM_ SG_ 518 IPA_TPA_Status "Status der Funktion IPA gegenüber der Funktion TPA";
CM_ SG_ 518 Parken_01_BZ "4bit Botschaftszähler, wird mit jeder Sendebotschaft inkrementiert";
CM_ SG_ 518 Parken_01_CRC "Für MLB:
Berechnung siehe Lastenheft 'Kommunikationsabsicherung für FlexRay und CAN'
Ab MQB und MLBevo:
Berechnung siehe Lastenheft 'End-to-End Kommunikationsabsicherung'

Endwerte siehe Begleitdokument 'S-PDU Kennungsfolgen'";
CM_ SG_ 518 Parken_aktives_System "Das Signal zeigt an, welches der Parksysteme auf dem zFAS gerade aktiv ist.";
CM_ SG_ 518 Parken_Anforderung_HMS "Anforderung der Dienste des HMS durch die Parkplattform";
CM_ SG_ 518 Parken_Anhalteweg_Anf "Zeigt eine Anhalteweg Anforderung an";
CM_ SG_ 518 Parken_beibehalten "Fordert das Parken beim HMS an";
CM_ SG_ 518 Parken_BKD_Anf "Anforderung der Systemtotzeitoptimierung ans VZM";
CM_ SG_ 518 Parken_Bordstein_Winkel "Winkel zwischen Bordstein und Fahrzeug.";
CM_ SG_ 518 Parken_erhoehtes_Moment "Anforderung einer spezifizierten Motormomenten-Rampe seitens IPA/PiloPa für das Überfahren einer Schwelle oder eines Bordsteins.";
CM_ SG_ 518 Parken_Fahrbereitschaft_Anf "Anforderung seitens iPA/pilotiertes Parken, die Fahrbereitschaft aufrecht zu erhalten und das Verlassenskonzept im MSG beim „automatischen Parkvorgang“ zu deaktivieren.";
CM_ SG_ 518 Parken_Fahrstufenwunsch "Fahrstufenwunsch von IPAe/RPAe an das Getriebe";
CM_ SG_ 518 Parken_max_Beschleunigung "Maximale zulässige Beschleunigung der Parkfunktion";
CM_ SG_ 518 Parken_max_Geschwindigkeit "Maximale zulässige Geschwindigkeit der Parkfunktion";
CM_ SG_ 518 Parken_Motorlauf_Anf "Anforderung Motorlauf seitens PiloPa";
CM_ SG_ 518 Parken_Notstopp_Anf "Anforderung Notstopp der Parkplattform";
CM_ SG_ 518 Parken_Prefill_Anf "Anforderung Prefill am VZM";
CM_ SG_ 518 Parken_QFK_AnfStat "Statusinformationen des Anforderers";
CM_ SG_ 518 Parken_QFK_Art1 "Auswahlsignal für Parken_QFK_Signal1";
CM_ SG_ 518 Parken_QFK_Art2 "Auswahlsignal für Parken_QFK_Signal2";
CM_ SG_ 518 Parken_QFK_KruemmSoll "Krümmungsanforderung";
CM_ SG_ 518 Parken_QFK_KruemmSoll_VZ "Vorzeichen für die Krümmungsanforderung";
CM_ SG_ 518 Parken_QFK_Signal1 "Inhalt PLA_QFK_Signal1 wird durch das Signal PLA_QFK_Art1 gesteuert.
Nähere Informationen im LAH Querführungskoordinator.";
CM_ SG_ 518 Parken_QFK_Signal2 "Inhalt Parken_QFK_Signal2 wird durch das Signal Parken_QFK_Art2 gesteuert.
Nähere Informationen im LAH Querführungskoordinator.";
CM_ SG_ 518 Parken_QFK_Spuerb "Spürbarkeitsanforderung. Legt fest, mit welchem Handmoment die angeforderte Krümmung überlenkt werden muss.";
CM_ SG_ 518 Parken_Schleichfahrt_Anf "Anforderungen des Schleichfahrtmodus.";
CM_ SG_ 518 Parken_Soll_Anhalteweg_Anf "Anforderung des Soll Anhalteweges der PPF beim VZM";
CM_ SG_ 518 Parken_Sollbeschleunigung "Anforderung einer Parkenfunktion an den TSK, das Fahrzeug zu beschleunigen.";
CM_ SG_ 518 Parken_Status_IPA_TSK "Statusinformation vom IPA für Handshakemechanismus mit TSK";
CM_ SG_ 518 Parken_Verz_Anf "Zeigt die die angeforderte Verzögerung an";
CM_ SG_ 518 Parken_Verz_Anf_ASIL "Angabe des ASIL Levels der aktuell aktiven Funtkion auf der Parkplattform";
CM_ SG_ 518 Parken_Warnruck_Anf "Signal zur Anforderung Warnruck beim VZM";
CM_ SG_ 518 Parken_Warnruckeln_Anf "Anforderung Warnruckeln beim VZM";

CM_ SG_ 2331595837 PCH_Kritikalitaetsklasse "Kritikalitätsklasse des kritschen Objektes.";
CM_ SG_ 2331595837 PCH_MessZeitpunkt "Wann wurden die Objekte gemessen? (analog Masterzeit)";
CM_ SG_ 2331595837 PCH_Object_aAbsX "The signal indicates the absolute acceleration in X direction";
CM_ SG_ 2331595837 PCH_Object_aAbsY "The signal indicates the absolute acceleration in Y direction";
CM_ SG_ 2331595837 PCH_Object_Class "The signal indicates the object class.";
CM_ SG_ 2331595837 PCH_Object_PosX "Object X position in UKS";
CM_ SG_ 2331595837 PCH_Object_PosY "Object Y position in UKS";
CM_ SG_ 2331595837 PCH_Object_vAbsX "The signal indicates the velocity in X direction";
CM_ SG_ 2331595837 PCH_Object_vAbsY "The signal indicates the velocity in Y direction.";
CM_ SG_ 2331595837 PCH_Object_Width "The signal indicates the width of the object.";
CM_ SG_ 2331595837 PCH_Status "Status der PCH-Komponente auf dem Nanoradar.";
CM_ SG_ 2331595837 PCH_TTC "Prädizierte Zeit bis zur Kollision.";

CM_ SG_ 802 PCR_Obj_Guete "Detektionsgüte des wahrscheinlichsten Objektes";
CM_ SG_ 802 PCR_Obj_TTC "TimeToCollision des wahrscheinlichsten Objektes";
CM_ SG_ 802 PCR_Obj_vx_rel "Relative Geschwindigkeit in x-Richtung des wahrscheinlichsten Objektes ";
CM_ SG_ 802 PCR_Obj_vy_rel "Relative Geschwindigkeit in y-Richtung des wahrscheinlichsten Objektes ";
CM_ SG_ 802 PCR_Sensorstatus "Status des Heckumfeldsensors";
CM_ SG_ 802 PCR_Sensorstatus_02 "Status des Heckumfeldsensors";

CM_ SG_ 796 PCS_Li_BlockID "BlockID is a counter to associate objects to the measurement cylce (one block contains header plus objects).";
CM_ SG_ 796 PCS_Li_CS "Prädizierte Schwere für eine Kollision.";
CM_ SG_ 796 PCS_Li_CS_Konfidenz "Konfidenz der Crashschwere.";
CM_ SG_ 796 PCS_Li_CW "Kollisionswahrscheinlichkeit";
CM_ SG_ 796 PCS_Li_CW_Konfidenz "Konfidenz der Crashwahrscheinlichkeit.";
CM_ SG_ 796 PCS_Li_MessZeitpunkt "Wann wurden die Objekte gemessen? (analog Masterzeit)";
CM_ SG_ 796 PCS_Li_Status "Status der PCS-Komponente auf dem linkem Nanoradar.";
CM_ SG_ 796 PCS_Li_TTC "Prädizierte Zeit bis zur Kollision.";
CM_ SG_ 796 PCS_Li_TTC_StdAbw "Standardabweichung des TTC Signals.";

CM_ SG_ 797 PCS_Re_BlockID "BlockID is a counter to associate objects to the measurement cylce (one block contains header plus objects).";
CM_ SG_ 797 PCS_Re_CS "Prädizierte Schwere für eine Kollision.";
CM_ SG_ 797 PCS_Re_CS_Konfidenz "Konfidenz der Crashschwere.";
CM_ SG_ 797 PCS_Re_CW "Kollisionswahrscheinlichkeit";
CM_ SG_ 797 PCS_Re_CW_Konfidenz "Konfidenz der Crashwahrscheinlichkeit.";
CM_ SG_ 797 PCS_Re_MessZeitpunkt "Wann wurden die Objekte gemessen? (analog Masterzeit)";
CM_ SG_ 797 PCS_Re_Status "Status der PCS-Komponente auf dem rechten Nanoradar.";
CM_ SG_ 797 PCS_Re_TTC "Prädizierte Zeit bis zur Kollision.";
CM_ SG_ 797 PCS_Re_TTC_StdAbw "Standardabweichung des TTC Signals.";

CM_ SG_ 2527679685 PDC_ASM_Data_1 "Dieses Signal wird vom PDC SG befüllt und an den Assistenzsystemmonitor ASM gesendet.";
CM_ SG_ 2527679685 PDC_ASM_Data_2 "Dieses Signal wird vom PDC SG befüllt und an den Assistenzsystemmonitor ASM gesendet.";
CM_ SG_ 2527679685 PDC_ASM_Data_3 "Dieses Signal wird vom PDC SG befüllt und an den Assistenzsystemmonitor ASM gesendet.";
CM_ SG_ 2527679685 PDC_ASM_Data_4 "Dieses Signal wird vom PDC SG befüllt und an den Assistenzsystemmonitor ASM gesendet.";
CM_ SG_ 2527679685 PDC_ASM_Data_5 "Dieses Signal wird vom PDC SG befüllt und an den Assistenzsystemmonitor ASM gesendet.";
CM_ SG_ 2527679685 PDC_ASM_Data_6 "Dieses Signal wird vom PDC SG befüllt und an den Assistenzsystemmonitor ASM gesendet.";
CM_ SG_ 2527679685 PDC_ASM_Ereignis "Dieses Signal definiert, welche Funktion und welche Art von Aktivität das Senden der Botschaft an den Assistenzsystemmonitor ASM veranlasst hat.";
CM_ SG_ 2527679685 PDC_ASM_Zeitstempel_02 "Dieses Signal ermöglicht die zeitliche Zuordnung der von PDC an den Assistenzsystemmonitor ASM gesendeten Statusbotschaften.";

CM_ SG_ 770 PLA_05_Sendestatus "Umschalten zwischen langsamem und schnellem Zyklus der PLA_05-Botschaft";
CM_ SG_ 770 PLA_QFK_AnfStat "Statusinformationen des Anforderers";
CM_ SG_ 770 PLA_QFK_Art1 "Auswahlsignal für PLA_QFK_Signal1";
CM_ SG_ 770 PLA_QFK_Art2 "Auswahlsignal für PLA_QFK_Signal2";
CM_ SG_ 770 PLA_QFK_KrSoll "Krümmungsanforderung Parkfunktion beim QFK";
CM_ SG_ 770 PLA_QFK_KrSoll_VZ "Vorzeichen für Krümmungsanforderung Parkfunktion beim QFK";
CM_ SG_ 770 PLA_QFK_KruemmSoll "Krümmungsanforderung";
CM_ SG_ 770 PLA_QFK_KruemmSoll_VZ "Vorzeichen für die Krümmungsanforderung";
CM_ SG_ 770 PLA_QFK_Signal1 "Inhalt PLA_QFK_Signal1 wird durch das Signal PLA_QFK_Art1 gesteuert.
Nähere Informationen im LAH Querführungskoordinator.";
CM_ SG_ 770 PLA_QFK_Signal2 "Inhalt PLA_QFK_Signal2 wird durch das Signal PLA_QFK_Art2 gesteuert.
Nähere Informationen im LAH Querführungskoordinator.";
CM_ SG_ 770 PLA_QFK_Spuerb "Spürbarkeitsanforderung. Legt fest, mit welchem Handmoment die angeforderte Krümmung überlenkt werden muss.";
CM_ SG_ 770 SOK_PLA_05_Signatur "Signatur im Rahmen der durch SOK geschützen Broadcast-Kommunikation

Geschützte Funktionen: ParkingFunktionen
Geschützte Botschaft: PLA_05";

CM_ SG_ 319 PreCrash_Anforderung_AFR "Anforderungen der Funktion PrecrashSeite an Fahrwerksregelung";
CM_ SG_ 319 PreCrash_BFS_KSV_verfahren "Ansteuerung der Kopfstuetze Beifahrerseite durch die Funktion PreCrash

Signalwert 0x09 für vereinfachte Ansteuerung mit Logik im Sitz-SG (MQB37W)";
CM_ SG_ 319 PreCrash_BFS_Laengsverstellung "Ansteuerung der Laengsverstellung des Beifahrersitzes durch die PreCrash-Funktionen";
CM_ SG_ 319 PreCrash_BFS_Pneumatik_ansteuern "Ansteuerung des Beifahrersitzes durch die PreCrash-Funktionen";
CM_ SG_ 319 PreCrash_BFS_Sitzlehne_verfahren "Ansteuerung des Beifahrersitzes durch die PreCrash-Funktionen

Wert 0x06 und 0x07 für vereinfachte Ansteuerung Sitzlehne";
CM_ SG_ 319 PreCrash_Blinken "Safety Computer übermittelt Blinkverhalten bei einer PreCrash-Auslösung an den BCM2";
CM_ SG_ 319 PreCrash_Charisma_FahrPr "Aktuell eingestelltes Fahrprogramm der Funktion PreCrash";
CM_ SG_ 319 PreCrash_Charisma_Status "Verfügbarkeit der Funktion PreCrash für die Ansteuerung durch den Charisma_Koordinator";
CM_ SG_ 319 PreCrash_Fenster_schliessen "Anforderung Seitenscheiben schließen durch die Funktion PreCrash";
CM_ SG_ 319 PreCrash_Fo_KSV_verfahren "Ansteuerung der Kopfstuetzen im Fond durch die PreCrash-Funktionen";
CM_ SG_ 319 PreCrash_Fo_Pneumatik_ansteuern "Ansteuerung der Fondsitze durch die PreCrash-Funktionen";
CM_ SG_ 319 PreCrash_Fo_Sitzlehne_verfahren "Ansteuerung des Fondsitzes durch die PreCrash-Funktionen";
CM_ SG_ 319 PreCrash_FS_KSV_verfahren "Ansteuerung der Kopfstuetze Fahrerseite durch die PreCrash-Funktionen

Signalwert 0x09 für vereinfachte Ansteuerung mit Logik im Sitz-SG (MQB37W)";
CM_ SG_ 319 PreCrash_FS_Laengsverstellung "Ansteuerung der Laengsverstellung des Fahrersitzes durch die PreCrash-Funktionen";
CM_ SG_ 319 PreCrash_FS_Pneumatik_ansteuern "Ansteuerung des Fahrersitzes durch die PreCrash-Funktionen";
CM_ SG_ 319 PreCrash_FS_Sitzlehne_verfahren "Ansteuerung des Fahrersitzes durch die PreCrash-Funktionen

Wert 0x06 und 0x07 für vereinfachte Ansteuerung Sitzlehne";
CM_ SG_ 319 PreCrash_Schiebedach_schliessen "Anforderung Schiebedach schließen durch die Funktion PreCrash";
CM_ SG_ 319 PreCrash_Tueren_Verriegeln "Anforderung Türen Verriegeln durch die Funktion PreCrash";
CM_ SG_ 319 SC_PreCrash_LED "Ansteuerung LED-Leiste im Kombi durch SC";
CM_ SG_ 319 SC_PreCrash_Texte "Safety Computer übermittelt Systemstatus der PreCrash Funktionen an Kombi";
CM_ SG_ 319 SC_PreCrash_Warnung "Safety Computer übermittelt Warnung der PreCrash Funktionen an Kombi";
CM_ SG_ 319 SC_PreSense_FCWP "Mitteilung an das NightVision, auf welche Art von Objekt eine Warnung angefordert wird";

CM_ SG_ 317 QFK_01_BZ "4bit Botschaftszähler, wird mit jeder Sendebotschaft inkrementiert";
CM_ SG_ 317 QFK_01_CRC "Für MLB:
Berechnung siehe Lastenheft 'Kommunikationsabsicherung für FlexRay und CAN'
Ab MQB und MLBevo:
Berechnung siehe Lastenheft 'End-to-End Kommunikationsabsicherung'

Endwerte siehe Begleitdokument 'S-PDU Kennungsfolgen'";
CM_ SG_ 317 QFK_01_Sendestatus "Umschalten zwischen langsamem und schnellem Zyklus der QFK_01-Botschaft";
CM_ SG_ 317 QFK_Anf_Giermomoffset "Giermomentenanforderung an das ESC";
CM_ SG_ 317 QFK_Anf_Giermomoffset_VZ "Giermomentenanforderung an das ESC Vorzeichen";
CM_ SG_ 317 QFK_DynBegr_aktiv "Aktueller Eingriff wird durch Sicherheits-
Ebene beschränkt";
CM_ SG_ 317 QFK_IstKraft "QFK IstKraft Bedienung mit gem. QFK Masterlastenheft";
CM_ SG_ 317 QFK_IstKraft_VZ "Vorzeicheninformation des Signals QFK_IstKraft";
CM_ SG_ 317 QFK_IstKraftNiveau "QFK Ist-Kraftniveau";
CM_ SG_ 317 QFK_IstKraftNiveau_VZ "Vorzeichen QFK Ist-Kraftniveau";
CM_ SG_ 317 QFK_KrIst "QFK Ist-Krümmung erweiterter Wertebereich";
CM_ SG_ 317 QFK_KrIst_VZ "Vorzeicheninformation des Signals QFK_KrIst (Ist-Kruemmung erweiterter Wertebereich)";
CM_ SG_ 317 QFK_KruemmIst "QFK Ist-Krümmung";
CM_ SG_ 317 QFK_KruemmIst_VZ "Vorzeicheninformation der QFK Ist-Kruemmung";
CM_ SG_ 317 QFK_Status "Statussignal für VMM und Teilnehmer";
CM_ SG_ 317 QFK_stAWV "QFK-Statussignal für AWV";
CM_ SG_ 317 QFK_stDSR "QFK-Statussignal für DSR";
CM_ SG_ 317 QFK_stEingriffBr "QFK Status des Bremseneingriffs";
CM_ SG_ 317 QFK_stHCA "QFK-Statussignal für HCA";
CM_ SG_ 317 QFK_stPLA "QFK-Statussignal für PLA";
CM_ SG_ 317 QFK_stRHP "Lenkhilfe QFK Statussignal für RHP";
CM_ SG_ 317 QFK_ZPosIst "Ist Zahnstangenposition";
CM_ SG_ 317 QFK_ZPosIst_VZ "Zahnstangenposition Vorzeichen";
CM_ SG_ 317 SOK_QFK_01_Signatur "Signatur im Rahmen der durch SOK geschützten Broadcast-Kommunikation

Geschützte Funktion: FAS-Systeme
Geschützte Botschaft: QFK_01";

CM_ SG_ 1023 Quersperre_04_BZ "4bit Botschaftszähler, wird mit jeder Sendebotschaft inkrementiert";
CM_ SG_ 1023 Quersperre_04_CRC "Für MLB:
Berechnung siehe Lastenheft 'Kommunikationsabsicherung für FlexRay und CAN'
Ab MQB und MLBevo:
Berechnung siehe Lastenheft 'End-to-End Kommunikationsabsicherung'

Endwerte siehe Begleitdokument 'S-PDU Kennungsfolgen'";
CM_ SG_ 1023 Quersperre_Anz_Sperre_Auslegen "Kombianzeige: Sperre wird ausgelegt";
CM_ SG_ 1023 Quersperre_Anz_Sperre_Einlegen "Kombianzeige: Sperre wird eingelegt";
CM_ SG_ 1023 Quersperre_Anz_Sperre_Geschl "Kombianzeige: Sperre geschlossen";
CM_ SG_ 1023 Quersperre_Istzustand "Zustand der Quersperre
Ein- und Auslegen wird als 'geschlossen' interpretiert.";
CM_ SG_ 1023 Quersperre_Status "Gibt den Status der hinteren Querssperre für andere Systeme an.";

CM_ SG_ 1616 RA_AM_Tuning "Das Signal kennzeichnet einen aktiven AM Suchlauf. Während des Suchlaufes wird die Frequenz = 0 übertragen.
0 = frequency locked => Störquelle vermeidet die aktuelle Frequenz
1 = AM tuning in progress => Störquelle abschalten bzw.PWM Signal auf DC umsch";
CM_ SG_ 1616 RA_Frequency "Übermittlung der eingestellten Sendefrequenz AM oder FM, diese wird mit RA_Frequency_unit multipliziert.
Im DAB oder Hybrid/Online Mode wird die aktuelle FM-Alternativfrequenz oder, falls nicht vorhanden, die zuletzt gehörte Senderfrequenz übertragen (AM";
CM_ SG_ 1616 RA_Frequency_unit "Faktor für RA_Frequency
bei AM: Faktor 0 = 1kHz
sonst   Faktor 1 = 100kHz";
CM_ SG_ 1616 RA_PowerAmpOn "1 = Request for Amplifier; 0 = Amplifier mute/off";
CM_ SG_ 1616 RA_Radio_Error_Flag "1 = mindestens ein Kundendienstfehlerspeicher Eintrag vorhanden";
CM_ SG_ 1616 RA_Radio_mute "1=Radio is muted for telephone";
CM_ SG_ 1616 RA_Radio_on "1 = user perceived On";
CM_ SG_ 1616 RA_Radio_Surround "1 = Surround ON; 0 = Surround OFF
requests the Amp to switch Surroundmode";
CM_ SG_ 1616 RA_VNC_OFF "VNC = Vehicle Noice Cancellation;
1 = VNC OFF; 0 = VNC ON
requests the Amp to switch VNC off";

CM_ SG_ 695 RCTA_01_BZ "4bit-Botschaftszaehler, wird in jeder Sendebotschaft inkrementiert";
CM_ SG_ 695 RCTA_01_CRC "Für MLB:
'Berechnung siehe Lastenheft 'Kommunikationsabsicherung für FlexRay und CAN''

Ab MQB und MLBevo:
'Berechnung siehe Lastenheft 'End-to-End Kommunikationsabsicherung''

Endwerte siehe Begleitdokument 'S-PDU Kennungsfolgen'";
CM_ SG_ 695 RCTA_Anf_Warnruck "Mit diesem Signal wird beim ESC ein Warnruck angefordert. Über die Belegung wird die Stärke des Rucks ausgewählt.";
CM_ SG_ 695 RCTA_Anforderung_HMS "Nach einer Notbremsung durch RCTA muss das Fahrzeug halten. Deshalb ist eine HMS-Anforderung mit der Notbremsung erforderlich.";
CM_ SG_ 695 RCTA_Bremsruck_Anforderung "Hinweis: In Zukunft das Signal RCTA_Anf_Warnruck anstatt RCTA_Bremsruck_Anforderung verwenden!

RCTA_Bremsruck_Anforderung  ist die Anforderung an das Bremssystem einen kurzen Bremsruck auszuführen. Mit dem Signal 'RCTA_Bremsruck_Freigabe' zusammen wird";
CM_ SG_ 695 RCTA_Bremsruck_Freigabe "Hinweis: In Zukunft das Signal RCTA_Anf_Warnruck anstatt RCTA_Bremsruck_Freigabe verwenden!

RCTA_Bremsruck_Freigabe ist die eigentliche Auforderung (mit dem Signal 'RCTA_Bremsruck_Anforderung') an das Bremssystem einen kurzen Bremsruck auszuführen. Dad";
CM_ SG_ 695 RCTA_Info_links "Hinweis: In Zukunft das Signal RCTA_Kritikalitätslevel_links anstatt RCTA_Info_links verwenden!

Das alte RCTA_Info wird aufgeteilt in RCTA_Info_links und RCTA_Info_rechts. Damit sollen Richtungsblinken oder ähnliches aufgrund der RCTA-Funtkion möglich ";
CM_ SG_ 695 RCTA_Info_rechts "Hinweis: In Zukunft das Signal RCTA_Kritikalitätslevel_rechts anstatt RCTA_Info_rechts verwenden!

Das alte RCTA_Info wird aufgeteilt in RCTA_Info_links und RCTA_Info_rechts. Damit sollen Richtungsblinken oder ähnliches aufgrund der RCTA-Funtkion möglic";
CM_ SG_ 695 RCTA_Kritikalitaetslevel_links "Mit dem Signal wird das Kritikalitätslevel der Funktion RCTA dargestellt.
Je höher das Kritikalitätslevel ist, je höher die Crashwahrscheinlichkeit.
Die Kritikalität ist nicht bewertbar, wenn
-	die Funktion im Anhängerbetrieb ist
-	die Sensorsicht blo";
CM_ SG_ 695 RCTA_Kritikalitaetslevel_rechts "Mit dem Signal wird das Kritikalitätslevel der Funktion RCTA dargestellt.
Je höher das Kritikalitätslevel ist, je höher die Crashwahrscheinlichkeit.
Die Kritikalität ist nicht bewertbar, wenn
-	die Funktion im Anhängerbetrieb ist
-	die Sensorsicht blo";
CM_ SG_ 695 RCTA_Modus "gibt die Verfügbarkeit der RCTA Modus an";
CM_ SG_ 695 RCTA_Notbremsung_Anforderung "RCTA_Notbremsung_Anforderung  ist die Anforderung der Funktion RCTA an das Bremssystem. Mit dem Signal 'Notbremsung_Freigabe' zusammen wird die Bremsung eingeleitet. Dadurch sollen größere Schäden am Fahrzeug verhindert werden.";
CM_ SG_ 695 RCTA_Notbremsung_Freigabe "RCTA_Notbremsung_Freigabe ist die eigentliche Auforderung (mit dem Signal 'Notbremsung_Anforderung_Wert') an das Bremssystem eine Notfallbremsung einzuleiten. Dadurch sollen größere Schäden am Fahrzeug vermieden werden.";
CM_ SG_ 695 RCTA_PaCo_BrakeIntervention "Signalisierung, ob die Kundenfunktion RCTA einen Bremseingriff ansteuert.

0 Inactive: RCTA steuert derzeit keinen Bremseingriff an
1 Active: RCTA steuert derzeit einen Bremseingriff an";
CM_ SG_ 695 RCTA_PaCo_BrakingPossible "Signalisierung, ob ein Bremseingriff seitens der Kundenfunktion RCTA möglich ist

0 Not_Possible: Aus Sicht von RCTA ist derzeit keine Unterstützung des Fahrers durch Bremseingriff möglich
1 Possible: Aus Sicht von RCTA ist derzeit eine Unterstützung d";
CM_ SG_ 695 RCTA_PaCo_MainState "Hauptzustand der Kundenfunktion RCTA

0 Init: RCTA befindet sich in der Initialisierung
1 InOperation_NoError: RCTA befindet sich im Betrieb ohne Fehler
7 Fehler: RCTA befindet sich im Fehlerzustand";
CM_ SG_ 695 RCTA_PaCo_UnavailableReason "Signalisierung der Ursachen für die Nicht-Verfügbarkeit von RCTA

0 No_Reason: Die RCTA-Funktion steht zur Verfügung oder es gibt keinen spezifischen Grund für die Nicht-Verfügbarkeit
1 Trailer_Hitched: Die RCTA-Funktion steht derzeit nicht zur Verfügu";
CM_ SG_ 695 RCTA_Status "RCTA_Status ist die Rückmeldung, ob das System überhaupt aktiv ist. Mögliche Zustände sind: Das System ist aus; Das System ist nur passiv (läuft, ist aber ohne Funktionalität); Das System ist aktiv; Das System ist fehlerhaft";
CM_ SG_ 695 RCTA_Status_FoD "RCTA Funktionsstatus für FoD";
CM_ SG_ 695 RCTA_Warnton "Ansteuerung APS Tongeber für  Warnton von RCTA. (Dauerton)";
BA_DEF_REL_ BU_SG_REL_  "GenSigTimeoutTime" INT 0 65535;
BA_DEF_ BO_  "DiagRequest" ENUM "No", "Yes";
BA_DEF_ BO_  "DiagResponse" ENUM "No", "Yes";
BA_DEF_ BO_  "DiagState" ENUM "No", "Yes";
BA_DEF_ BO_  "GenMsgChkConstant" HEX 0 4095;
BA_DEF_ BO_  "GenMsgCycleTime" INT 0 65535;
BA_DEF_ BO_  "GenMsgCycleTimeFast" INT 0 65535;
BA_DEF_ BO_  "GenMsgDelayTime" INT 0 100000;
BA_DEF_ BO_  "GenMsgILSupport" ENUM "No", "Yes";
BA_DEF_ BO_  "GenMsgNrOfRepetition" INT 0 100;
BA_DEF_ BO_  "GenMsgPDUConstants" STRING;
BA_DEF_ BO_  "GenMsgSendType" ENUM "Cyclic", "not_used", "not_used", "not_used", "not_used", "not_used", "not_used", "IfActive", "NoMsgSendType";
BA_DEF_ BO_  "GenMsgStartDelayTime" INT 0 100000;
BA_DEF_ BO_  "NmMessage" ENUM "No", "Yes";
BA_DEF_ BO_  "NmhMessage" ENUM "No", "Yes";
BA_DEF_ BO_  "MsgType" ENUM "Application", "NM ", "NMH", "TP2.0", "ISO-TP ", "BAP", "EID", "KS", "XCP_PRE_CONFIGURED", "XCP_RUNTIME_CONFIGURED";
BA_DEF_ BO_  "VAGTP20_API" HEX 0 255;
BA_DEF_ BO_  "VAGTP20_DynConnection" ENUM "No", "Yes";
BA_DEF_ BO_  "VAGTP20_DynSetup" ENUM "No", "Yes";
BA_DEF_ BO_  "VAGTP20_StatConnection" ENUM "No", "Yes";
BA_DEF_ BO_  "CANFD_BRS" ENUM "0", "1";
BA_DEF_ BO_  "VFrameFormat" ENUM "StandardCAN", "ExtendedCAN", "reserved", "reserved", "reserved", "reserved", "reserved", "reserved", "reserved", "reserved", "reserved", "reserved", "reserved", "reserved", "StandardCAN_FD", "ExtendedCAN_FD";
BA_DEF_ SG_  "GenSigActiveRepetitions" INT -2147483648 2147483647;
BA_DEF_ SG_  "GenSigInactiveValue" INT -2147483648 2147483647;
BA_DEF_ SG_  "GenSigSendType" ENUM "Cyclic", "OnWrite", "OnWriteWithRepetition", "OnChange", "OnChangeWithRepetition", "IfActive", "IfActiveWithRepetition", "NoSigSendType", "OnChangeAndIfActive", "OnChangeAndIfActiveWithRepetition";
BA_DEF_ SG_  "GenSigStartValue" INT -2147483648 2147483647;
BA_DEF_ SG_  "NWM-WakeupAllowed" ENUM "No", "Yes";
BA_DEF_ SG_  "GenSigFuncType" ENUM "NoFunction", "MsgCounter", "CRC-8", "XOR", "XOR-2", "DatedBit", "SW-Kl15", "CHK", "Constant", "Protocol", "CRC-8-SAE_J1850", "CRC-32", "DataLength", "DataID", "MsgCounter16", "SOK-Signatur", "Cluster";
BA_DEF_ SG_  "GenSigSwitchedByIgnition" ENUM "No", "Yes";
BA_DEF_ SG_  "Fehlerwert" HEX 0 2147483647;
BA_DEF_ SG_  "GenSigMissingSourceValue" HEX 0 2147483647;
BA_DEF_DEF_REL_  "GenSigTimeoutTime" 0;
BA_DEF_DEF_  "DiagRequest" "No";
BA_DEF_DEF_  "DiagResponse" "No";
BA_DEF_DEF_  "DiagState" "No";
BA_DEF_DEF_  "GenMsgChkConstant" 0;
BA_DEF_DEF_  "GenMsgCycleTime" 0;
BA_DEF_DEF_  "GenMsgCycleTimeFast" 0;
BA_DEF_DEF_  "GenMsgDelayTime" 0;
BA_DEF_DEF_  "GenMsgILSupport" "No";
BA_DEF_DEF_  "GenMsgNrOfRepetition" 0;
BA_DEF_DEF_  "GenMsgPDUConstants" "";
BA_DEF_DEF_  "GenMsgSendType" "NoMsgSendType";
BA_DEF_DEF_  "GenMsgStartDelayTime" 0;
BA_DEF_DEF_  "NmMessage" "No";
BA_DEF_DEF_  "NmhMessage" "No";
BA_DEF_DEF_  "MsgType" "Application";
BA_DEF_DEF_  "VAGTP20_API" 0;
BA_DEF_DEF_  "VAGTP20_DynConnection" "No";
BA_DEF_DEF_  "VAGTP20_DynSetup" "No";
BA_DEF_DEF_  "VAGTP20_StatConnection" "No";
BA_DEF_DEF_  "CANFD_BRS" "1";
BA_DEF_DEF_  "VFrameFormat" "StandardCAN";
BA_DEF_DEF_  "GenSigActiveRepetitions" 0;
BA_DEF_DEF_  "GenSigInactiveValue" 0;
BA_DEF_DEF_  "GenSigSendType" "NoSigSendType";
BA_DEF_DEF_  "GenSigStartValue" 0;
BA_DEF_DEF_  "NWM-WakeupAllowed" "No";
BA_DEF_DEF_  "GenSigFuncType" "NoFunction";
BA_DEF_DEF_  "GenSigSwitchedByIgnition" "Yes";
BA_DEF_DEF_  "Fehlerwert" 0;
BA_DEF_DEF_  "GenSigMissingSourceValue" 0;
BA_ "GenMsgCycleTime" BO_ 2463978666 100;
BA_ "GenMsgILSupport" BO_ 2463978666 1;
BA_ "GenMsgPDUConstants" BO_ 2463978666 "0x4a,0x1b,0x16,0x0a,0x24,0x35,0xf8,0x1f,0x59,0x60,0x3b,0x15,0xaa,0xe5,0x9a,0x2e";
BA_ "GenMsgSendType" BO_ 2463978666 0;
BA_ "VFrameFormat" BO_ 2463978666 15;
BA_ "GenMsgChkConstant" BO_ 1601 71;
BA_ "GenMsgCycleTime" BO_ 1601 1000;
BA_ "GenMsgILSupport" BO_ 1601 1;
BA_ "GenMsgPDUConstants" BO_ 1601 "0x47,0x47,0x47,0x47,0x47,0x47,0x47,0x47,0x47,0x47,0x47,0x47,0x47,0x47,0x47,0x47";
BA_ "GenMsgSendType" BO_ 1601 0;
BA_ "VFrameFormat" BO_ 1601 14;
BA_ "GenMsgCycleTime" BO_ 2527679686 2000;
BA_ "GenMsgDelayTime" BO_ 2527679686 100;
BA_ "GenMsgILSupport" BO_ 2527679686 1;
BA_ "GenMsgSendType" BO_ 2527679686 0;
BA_ "VFrameFormat" BO_ 2527679686 15;
BA_ "GenMsgCycleTime" BO_ 2600468499 200;
BA_ "GenMsgCycleTimeFast" BO_ 2600468499 10;
BA_ "NmhMessage" BO_ 2600468499 1;
BA_ "MsgType" BO_ 2600468499 2;
BA_ "CANFD_BRS" BO_ 2600468499 0;
BA_ "VFrameFormat" BO_ 2600468499 1;
BA_ "GenMsgCycleTime" BO_ 2600468501 200;
BA_ "GenMsgCycleTimeFast" BO_ 2600468501 10;
BA_ "NmhMessage" BO_ 2600468501 1;
BA_ "MsgType" BO_ 2600468501 2;
BA_ "CANFD_BRS" BO_ 2600468501 0;
BA_ "VFrameFormat" BO_ 2600468501 1;
BA_ "GenMsgCycleTime" BO_ 2600468594 200;
BA_ "GenMsgCycleTimeFast" BO_ 2600468594 10;
BA_ "NmhMessage" BO_ 2600468594 1;
BA_ "MsgType" BO_ 2600468594 2;
BA_ "CANFD_BRS" BO_ 2600468594 0;
BA_ "VFrameFormat" BO_ 2600468594 1;
BA_ "GenMsgCycleTime" BO_ 2600468539 200;
BA_ "GenMsgCycleTimeFast" BO_ 2600468539 10;
BA_ "NmhMessage" BO_ 2600468539 1;
BA_ "MsgType" BO_ 2600468539 2;
BA_ "CANFD_BRS" BO_ 2600468539 0;
BA_ "VFrameFormat" BO_ 2600468539 1;
BA_ "GenMsgCycleTime" BO_ 2600468496 200;
BA_ "GenMsgCycleTimeFast" BO_ 2600468496 10;
BA_ "NmhMessage" BO_ 2600468496 1;
BA_ "MsgType" BO_ 2600468496 2;
BA_ "CANFD_BRS" BO_ 2600468496 0;
BA_ "VFrameFormat" BO_ 2600468496 1;
BA_ "GenMsgCycleTime" BO_ 2600468498 200;
BA_ "GenMsgCycleTimeFast" BO_ 2600468498 10;
BA_ "NmhMessage" BO_ 2600468498 1;
BA_ "MsgType" BO_ 2600468498 2;
BA_ "CANFD_BRS" BO_ 2600468498 0;
BA_ "VFrameFormat" BO_ 2600468498 1;
BA_ "DiagRequest" BO_ 2621440531 1;
BA_ "MsgType" BO_ 2621440531 4;
BA_ "VFrameFormat" BO_ 2621440531 15;
BA_ "DiagResponse" BO_ 2621571603 1;
BA_ "MsgType" BO_ 2621571603 4;
BA_ "VFrameFormat" BO_ 2621571603 15;
BA_ "DiagRequest" BO_ 2621440533 1;
BA_ "MsgType" BO_ 2621440533 4;
BA_ "VFrameFormat" BO_ 2621440533 15;
BA_ "DiagResponse" BO_ 2621571605 1;
BA_ "MsgType" BO_ 2621571605 4;
BA_ "VFrameFormat" BO_ 2621571605 15;
BA_ "DiagRequest" BO_ 2621440527 1;
BA_ "MsgType" BO_ 2621440527 4;
BA_ "VFrameFormat" BO_ 2621440527 15;
BA_ "DiagResponse" BO_ 2621571599 1;
BA_ "MsgType" BO_ 2621571599 4;
BA_ "VFrameFormat" BO_ 2621571599 15;
BA_ "DiagRequest" BO_ 2621440626 1;
BA_ "MsgType" BO_ 2621440626 4;
BA_ "VFrameFormat" BO_ 2621440626 15;
BA_ "DiagResponse" BO_ 2621571698 1;
BA_ "MsgType" BO_ 2621571698 4;
BA_ "VFrameFormat" BO_ 2621571698 15;
BA_ "DiagRequest" BO_ 2621440571 1;
BA_ "MsgType" BO_ 2621440571 4;
BA_ "VFrameFormat" BO_ 2621440571 15;
BA_ "DiagResponse" BO_ 2621571643 1;
BA_ "MsgType" BO_ 2621571643 4;
BA_ "VFrameFormat" BO_ 2621571643 15;
BA_ "DiagState" BO_ 2621506048 1;
BA_ "MsgType" BO_ 2621506048 4;
BA_ "VFrameFormat" BO_ 2621506048 15;
BA_ "DiagRequest" BO_ 2621440530 1;
BA_ "MsgType" BO_ 2621440530 4;
BA_ "VFrameFormat" BO_ 2621440530 15;
BA_ "DiagResponse" BO_ 2621571602 1;
BA_ "MsgType" BO_ 2621571602 4;
BA_ "VFrameFormat" BO_ 2621571602 15;
BA_ "DiagRequest" BO_ 2621440542 1;
BA_ "MsgType" BO_ 2621440542 4;
BA_ "VFrameFormat" BO_ 2621440542 15;
BA_ "DiagResponse" BO_ 2621571614 1;
BA_ "MsgType" BO_ 2621571614 4;
BA_ "VFrameFormat" BO_ 2621571614 15;
BA_ "DiagRequest" BO_ 2621469190 1;
BA_ "MsgType" BO_ 2621469190 4;
BA_ "VFrameFormat" BO_ 2621469190 15;
BA_ "DiagResponse" BO_ 2621600262 1;
BA_ "MsgType" BO_ 2621600262 4;
BA_ "VFrameFormat" BO_ 2621600262 15;
BA_ "DiagRequest" BO_ 2549903646 1;
BA_ "MsgType" BO_ 2549903646 4;
BA_ "VFrameFormat" BO_ 2549903646 15;
BA_ "DiagResponse" BO_ 2550034718 1;
BA_ "MsgType" BO_ 2550034718 4;
BA_ "VFrameFormat" BO_ 2550034718 15;
BA_ "DiagRequest" BO_ 2549903647 1;
BA_ "MsgType" BO_ 2549903647 4;
BA_ "VFrameFormat" BO_ 2549903647 15;
BA_ "DiagResponse" BO_ 2550034719 1;
BA_ "MsgType" BO_ 2550034719 4;
BA_ "VFrameFormat" BO_ 2550034719 15;
BA_ "DiagRequest" BO_ 2549903402 1;
BA_ "MsgType" BO_ 2549903402 4;
BA_ "VFrameFormat" BO_ 2549903402 15;
BA_ "DiagResponse" BO_ 2550034474 1;
BA_ "MsgType" BO_ 2550034474 4;
BA_ "VFrameFormat" BO_ 2550034474 15;
BA_ "DiagRequest" BO_ 2549903403 1;
BA_ "MsgType" BO_ 2549903403 4;
BA_ "VFrameFormat" BO_ 2549903403 15;
BA_ "DiagResponse" BO_ 2550034475 1;
BA_ "MsgType" BO_ 2550034475 4;
BA_ "VFrameFormat" BO_ 2550034475 15;
BA_ "DiagRequest" BO_ 2621440716 1;
BA_ "MsgType" BO_ 2621440716 4;
BA_ "VFrameFormat" BO_ 2621440716 15;
BA_ "DiagResponse" BO_ 2621571788 1;
BA_ "MsgType" BO_ 2621571788 4;
BA_ "VFrameFormat" BO_ 2621571788 15;
BA_ "DiagRequest" BO_ 2621440717 1;
BA_ "MsgType" BO_ 2621440717 4;
BA_ "VFrameFormat" BO_ 2621440717 15;
BA_ "DiagResponse" BO_ 2621571789 1;
BA_ "MsgType" BO_ 2621571789 4;
BA_ "VFrameFormat" BO_ 2621571789 15;
BA_ "DiagRequest" BO_ 2564424945 1;
BA_ "MsgType" BO_ 2564424945 4;
BA_ "VFrameFormat" BO_ 2564424945 15;
BA_ "DiagResponse" BO_ 2564485380 1;
BA_ "MsgType" BO_ 2564485380 4;
BA_ "VFrameFormat" BO_ 2564485380 15;
BA_ "DiagState" BO_ 2564502513 1;
BA_ "MsgType" BO_ 2564502513 4;
BA_ "VFrameFormat" BO_ 2564502513 15;
BA_ "DiagRequest" BO_ 2564424689 1;
BA_ "MsgType" BO_ 2564424689 4;
BA_ "VFrameFormat" BO_ 2564424689 15;
BA_ "DiagResponse" BO_ 2564485379 1;
BA_ "MsgType" BO_ 2564485379 4;
BA_ "VFrameFormat" BO_ 2564485379 15;
BA_ "GenMsgCycleTime" BO_ 2589283656 500;
BA_ "GenMsgDelayTime" BO_ 2589283656 100;
BA_ "GenMsgILSupport" BO_ 2589283656 1;
BA_ "GenMsgSendType" BO_ 2589283656 0;
BA_ "VFrameFormat" BO_ 2589283656 15;
BA_ "GenMsgCycleTime" BO_ 525 1000;
BA_ "GenMsgCycleTimeFast" BO_ 525 50;
BA_ "GenMsgDelayTime" BO_ 525 50;
BA_ "GenMsgILSupport" BO_ 525 1;
BA_ "GenMsgNrOfRepetition" BO_ 525 5;
BA_ "GenMsgSendType" BO_ 525 0;
BA_ "VFrameFormat" BO_ 525 14;
BA_ "GenMsgCycleTime" BO_ 2527679741 240;
BA_ "GenMsgILSupport" BO_ 2527679741 1;
BA_ "GenMsgPDUConstants" BO_ 2527679741 "0x9d,0xe8,0x36,0xa1,0xca,0x3b,0x1d,0x33,0xe0,0xd5,0xbb,0x5f,0xae,0x3c,0x31,0x9f";
BA_ "GenMsgSendType" BO_ 2527679741 0;
BA_ "VFrameFormat" BO_ 2527679741 15;
BA_ "GenMsgCycleTime" BO_ 518 20;
BA_ "GenMsgILSupport" BO_ 518 1;
BA_ "GenMsgPDUConstants" BO_ 518 "0x09,0xfa,0xca,0x8e,0x62,0xd5,0xd1,0xf0,0x31,0xa0,0xaf,0xda,0x4d,0x1a,0x0a,0x97";
BA_ "GenMsgSendType" BO_ 518 0;
BA_ "VFrameFormat" BO_ 518 14;
BA_ "GenMsgCycleTime" BO_ 2331595837 50;
BA_ "GenMsgILSupport" BO_ 2331595837 1;
BA_ "GenMsgSendType" BO_ 2331595837 0;
BA_ "VFrameFormat" BO_ 2331595837 15;
BA_ "GenMsgCycleTime" BO_ 802 40;
BA_ "GenMsgILSupport" BO_ 802 1;
BA_ "GenMsgSendType" BO_ 802 0;
BA_ "VFrameFormat" BO_ 802 14;
BA_ "GenMsgCycleTime" BO_ 796 50;
BA_ "GenMsgILSupport" BO_ 796 1;
BA_ "GenMsgPDUConstants" BO_ 796 "0x82,0xd7,0xb7,0x12,0xad,0x85,0x09,0x7e,0x13,0x0b,0x9c,0x34,0x5a,0xfa,0x87,0x16";
BA_ "GenMsgSendType" BO_ 796 0;
BA_ "VFrameFormat" BO_ 796 14;
BA_ "GenMsgCycleTime" BO_ 797 50;
BA_ "GenMsgILSupport" BO_ 797 1;
BA_ "GenMsgPDUConstants" BO_ 797 "0x0e,0xa2,0xbc,0xc6,0x54,0x6d,0x12,0x40,0x57,0xa3,0x86,0x32,0xc2,0x7e,0x93,0xbe";
BA_ "GenMsgSendType" BO_ 797 0;
BA_ "VFrameFormat" BO_ 797 14;
BA_ "GenMsgCycleTime" BO_ 2527679685 2000;
BA_ "GenMsgDelayTime" BO_ 2527679685 100;
BA_ "GenMsgILSupport" BO_ 2527679685 1;
BA_ "GenMsgSendType" BO_ 2527679685 0;
BA_ "VFrameFormat" BO_ 2527679685 15;
BA_ "GenMsgCycleTime" BO_ 770 1000;
BA_ "GenMsgCycleTimeFast" BO_ 770 20;
BA_ "GenMsgILSupport" BO_ 770 1;
BA_ "GenMsgNrOfRepetition" BO_ 770 5;
BA_ "GenMsgSendType" BO_ 770 0;
BA_ "VFrameFormat" BO_ 770 14;
BA_ "GenMsgCycleTime" BO_ 319 200;
BA_ "GenMsgDelayTime" BO_ 319 20;
BA_ "GenMsgILSupport" BO_ 319 1;
BA_ "GenMsgPDUConstants" BO_ 319 "0x28,0x6e,0x5a,0xc6,0x52,0x65,0x85,0xa1,0xb8,0xe6,0x38,0x88,0xf8,0xb9,0x2b,0xb0";
BA_ "GenMsgSendType" BO_ 319 0;
BA_ "VFrameFormat" BO_ 319 14;
BA_ "GenMsgCycleTime" BO_ 317 20;
BA_ "GenMsgCycleTimeFast" BO_ 317 10;
BA_ "GenMsgILSupport" BO_ 317 1;
BA_ "GenMsgNrOfRepetition" BO_ 317 5;
BA_ "GenMsgPDUConstants" BO_ 317 "0x18,0x71,0x10,0x8d,0xd7,0xaa,0xb0,0x78,0xac,0x12,0xae,0x0c,0xdd,0xf1,0x85,0x68";
BA_ "GenMsgSendType" BO_ 317 0;
BA_ "VFrameFormat" BO_ 317 14;
BA_ "GenMsgCycleTime" BO_ 1023 500;
BA_ "GenMsgDelayTime" BO_ 1023 50;
BA_ "GenMsgILSupport" BO_ 1023 1;
BA_ "GenMsgPDUConstants" BO_ 1023 "0x06,0xdf,0xf9,0x15,0xb0,0xd5,0x92,0x25,0x13,0x27,0xd8,0x61,0x83,0x9d,0x24,0x73";
BA_ "GenMsgSendType" BO_ 1023 0;
BA_ "VFrameFormat" BO_ 1023 14;
BA_ "GenMsgCycleTime" BO_ 1616 1000;
BA_ "GenMsgDelayTime" BO_ 1616 50;
BA_ "GenMsgILSupport" BO_ 1616 1;
BA_ "GenMsgSendType" BO_ 1616 0;
BA_ "VFrameFormat" BO_ 1616 14;
BA_ "GenMsgCycleTime" BO_ 695 50;
BA_ "GenMsgILSupport" BO_ 695 1;
BA_ "GenMsgPDUConstants" BO_ 695 "0x5e,0xc7,0x04,0x11,0x4d,0x27,0x0d,0x31,0x91,0xb8,0x62,0x76,0x64,0x09,0xeb,0xec";
BA_ "GenMsgSendType" BO_ 695 0;
BA_ "VFrameFormat" BO_ 695 14;
BA_ "GenSigSendType" SG_ 2463978666 MO_Drehzahl_EM 0;
BA_ "GenSigStartValue" SG_ 2463978666 MO_Drehzahl_EM 8190;
BA_ "GenSigSwitchedByIgnition" SG_ 2463978666 MO_Drehzahl_EM 0;
BA_ "Fehlerwert" SG_ 2463978666 MO_Drehzahl_EM 8191;
BA_ "GenSigSendType" SG_ 2463978666 MO_Drehzahl_EM_sek 0;
BA_ "GenSigStartValue" SG_ 2463978666 MO_Drehzahl_EM_sek 8190;
BA_ "GenSigSwitchedByIgnition" SG_ 2463978666 MO_Drehzahl_EM_sek 0;
BA_ "Fehlerwert" SG_ 2463978666 MO_Drehzahl_EM_sek 8191;
BA_ "GenSigSendType" SG_ 2463978666 MO_EM1_Generator_Leistung 0;
BA_ "GenSigStartValue" SG_ 2463978666 MO_EM1_Generator_Leistung 254;
BA_ "GenSigSwitchedByIgnition" SG_ 2463978666 MO_EM1_Generator_Leistung 0;
BA_ "Fehlerwert" SG_ 2463978666 MO_EM1_Generator_Leistung 255;
BA_ "GenSigSendType" SG_ 2463978666 MO_EM1_Max_Leistung_Gesamt 0;
BA_ "GenSigStartValue" SG_ 2463978666 MO_EM1_Max_Leistung_Gesamt 8190;
BA_ "GenSigSwitchedByIgnition" SG_ 2463978666 MO_EM1_Max_Leistung_Gesamt 0;
BA_ "GenSigSendType" SG_ 2463978666 MO_EM1_Max_Spannung_Lim 0;
BA_ "GenSigStartValue" SG_ 2463978666 MO_EM1_Max_Spannung_Lim 1022;
BA_ "GenSigSwitchedByIgnition" SG_ 2463978666 MO_EM1_Max_Spannung_Lim 0;
BA_ "GenSigSendType" SG_ 2463978666 MO_EM1_Min_Leistung_Gesamt 0;
BA_ "GenSigStartValue" SG_ 2463978666 MO_EM1_Min_Leistung_Gesamt 8190;
BA_ "GenSigSwitchedByIgnition" SG_ 2463978666 MO_EM1_Min_Leistung_Gesamt 0;
BA_ "GenSigSendType" SG_ 2463978666 MO_EM1_Min_Spannung_Lim 0;
BA_ "GenSigStartValue" SG_ 2463978666 MO_EM1_Min_Spannung_Lim 1022;
BA_ "GenSigSwitchedByIgnition" SG_ 2463978666 MO_EM1_Min_Spannung_Lim 0;
BA_ "GenSigSendType" SG_ 2463978666 MO_EM2_Generator_Leistung 0;
BA_ "GenSigStartValue" SG_ 2463978666 MO_EM2_Generator_Leistung 254;
BA_ "GenSigSwitchedByIgnition" SG_ 2463978666 MO_EM2_Generator_Leistung 0;
BA_ "Fehlerwert" SG_ 2463978666 MO_EM2_Generator_Leistung 255;
BA_ "GenSigSendType" SG_ 2463978666 MO_EM2_Max_Leistung_Gesamt 0;
BA_ "GenSigStartValue" SG_ 2463978666 MO_EM2_Max_Leistung_Gesamt 8190;
BA_ "GenSigSwitchedByIgnition" SG_ 2463978666 MO_EM2_Max_Leistung_Gesamt 0;
BA_ "GenSigSendType" SG_ 2463978666 MO_EM2_Max_Spannung_Lim 0;
BA_ "GenSigStartValue" SG_ 2463978666 MO_EM2_Max_Spannung_Lim 1022;
BA_ "GenSigSwitchedByIgnition" SG_ 2463978666 MO_EM2_Max_Spannung_Lim 0;
BA_ "GenSigSendType" SG_ 2463978666 MO_EM2_Min_Leistung_Gesamt 0;
BA_ "GenSigStartValue" SG_ 2463978666 MO_EM2_Min_Leistung_Gesamt 8190;
BA_ "GenSigSwitchedByIgnition" SG_ 2463978666 MO_EM2_Min_Leistung_Gesamt 0;
BA_ "GenSigSendType" SG_ 2463978666 MO_EM2_Min_Spannung_Lim 0;
BA_ "GenSigStartValue" SG_ 2463978666 MO_EM2_Min_Spannung_Lim 1022;
BA_ "GenSigSwitchedByIgnition" SG_ 2463978666 MO_EM2_Min_Spannung_Lim 0;
BA_ "GenSigSendType" SG_ 2463978666 MO_Rekuperation_EM_Ges_Ueberlauf 0;
BA_ "GenSigSwitchedByIgnition" SG_ 2463978666 MO_Rekuperation_EM_Ges_Ueberlauf 0;
BA_ "GenSigSendType" SG_ 2463978666 MO_Rekuperation_Ges_EM 0;
BA_ "GenSigSwitchedByIgnition" SG_ 2463978666 MO_Rekuperation_Ges_EM 0;
BA_ "GenSigSendType" SG_ 2463978666 MO_TNW_Max_Spannung_Lim 0;
BA_ "GenSigStartValue" SG_ 2463978666 MO_TNW_Max_Spannung_Lim 1022;
BA_ "GenSigSwitchedByIgnition" SG_ 2463978666 MO_TNW_Max_Spannung_Lim 0;
BA_ "GenSigSendType" SG_ 2463978666 MO_TNW_Min_Spannung_Lim 0;
BA_ "GenSigStartValue" SG_ 2463978666 MO_TNW_Min_Spannung_Lim 1022;
BA_ "GenSigSwitchedByIgnition" SG_ 2463978666 MO_TNW_Min_Spannung_Lim 0;
BA_ "GenSigSendType" SG_ 2463978666 MO_Uebersetzung_EM 0;
BA_ "GenSigStartValue" SG_ 2463978666 MO_Uebersetzung_EM 1022;
BA_ "GenSigSwitchedByIgnition" SG_ 2463978666 MO_Uebersetzung_EM 0;
BA_ "Fehlerwert" SG_ 2463978666 MO_Uebersetzung_EM 1023;
BA_ "GenSigSendType" SG_ 2463978666 MO_Uebersetzung_EM_sek 0;
BA_ "GenSigStartValue" SG_ 2463978666 MO_Uebersetzung_EM_sek 1022;
BA_ "GenSigSwitchedByIgnition" SG_ 2463978666 MO_Uebersetzung_EM_sek 0;
BA_ "Fehlerwert" SG_ 2463978666 MO_Uebersetzung_EM_sek 1023;
BA_ "GenSigSendType" SG_ 2463978666 MO_Verbrauch_EM_Ges 0;
BA_ "GenSigSwitchedByIgnition" SG_ 2463978666 MO_Verbrauch_EM_Ges 0;
BA_ "GenSigSendType" SG_ 2463978666 MO_Verbrauch_EM_Ges_Ueberlauf 0;
BA_ "GenSigSwitchedByIgnition" SG_ 2463978666 MO_Verbrauch_EM_Ges_Ueberlauf 0;
BA_ "GenSigSendType" SG_ 2463978666 Motor_57_BZ 0;
BA_ "GenSigFuncType" SG_ 2463978666 Motor_57_BZ 1;
BA_ "GenSigSwitchedByIgnition" SG_ 2463978666 Motor_57_BZ 0;
BA_ "GenSigSendType" SG_ 2463978666 Motor_57_CRC 0;
BA_ "GenSigFuncType" SG_ 2463978666 Motor_57_CRC 2;
BA_ "GenSigSwitchedByIgnition" SG_ 2463978666 Motor_57_CRC 0;
BA_ "GenSigSendType" SG_ 1601 MO_Ansaugsystem 0;
BA_ "GenSigFuncType" SG_ 1601 MO_Ansaugsystem 8;
BA_ "GenSigSwitchedByIgnition" SG_ 1601 MO_Ansaugsystem 0;
BA_ "GenSigSendType" SG_ 1601 MO_Anzahl_Zyl 0;
BA_ "GenSigFuncType" SG_ 1601 MO_Anzahl_Zyl 8;
BA_ "GenSigSwitchedByIgnition" SG_ 1601 MO_Anzahl_Zyl 0;
BA_ "GenSigSendType" SG_ 1601 MO_Anzeige_StSt_gueltig 0;
BA_ "GenSigSwitchedByIgnition" SG_ 1601 MO_Anzeige_StSt_gueltig 0;
BA_ "GenSigSendType" SG_ 1601 MO_Code 0;
BA_ "GenSigSwitchedByIgnition" SG_ 1601 MO_Code 0;
BA_ "GenSigSendType" SG_ 1601 MO_DPF_verbaut 0;
BA_ "GenSigFuncType" SG_ 1601 MO_DPF_verbaut 8;
BA_ "GenSigSwitchedByIgnition" SG_ 1601 MO_DPF_verbaut 0;
BA_ "GenSigSendType" SG_ 1601 MO_Faktor_Momente_02 0;
BA_ "GenSigFuncType" SG_ 1601 MO_Faktor_Momente_02 8;
BA_ "GenSigSwitchedByIgnition" SG_ 1601 MO_Faktor_Momente_02 0;
BA_ "GenSigSendType" SG_ 1601 MO_Getriebe_Code 0;
BA_ "GenSigSwitchedByIgnition" SG_ 1601 MO_Getriebe_Code 0;
BA_ "GenSigSendType" SG_ 1601 MO_Hubraum 0;
BA_ "GenSigFuncType" SG_ 1601 MO_Hubraum 8;
BA_ "GenSigSwitchedByIgnition" SG_ 1601 MO_Hubraum 0;
BA_ "GenSigSendType" SG_ 1601 MO_Hybridfahrzeug 0;
BA_ "GenSigFuncType" SG_ 1601 MO_Hybridfahrzeug 8;
BA_ "GenSigSwitchedByIgnition" SG_ 1601 MO_Hybridfahrzeug 0;
BA_ "GenSigSendType" SG_ 1601 MO_Kraftstoffart 0;
BA_ "GenSigFuncType" SG_ 1601 MO_Kraftstoffart 8;
BA_ "GenSigSwitchedByIgnition" SG_ 1601 MO_Kraftstoffart 0;
BA_ "GenSigSendType" SG_ 1601 MO_Leistung 0;
BA_ "GenSigSwitchedByIgnition" SG_ 1601 MO_Leistung 0;
BA_ "GenSigSendType" SG_ 1601 MO_OBD_Typ 0;
BA_ "GenSigSwitchedByIgnition" SG_ 1601 MO_OBD_Typ 0;
BA_ "GenSigSendType" SG_ 1601 MO_StartStopp_Codiert 0;
BA_ "GenSigFuncType" SG_ 1601 MO_StartStopp_Codiert 8;
BA_ "GenSigSwitchedByIgnition" SG_ 1601 MO_StartStopp_Codiert 0;
BA_ "GenSigSendType" SG_ 1601 Motor_Code_01_BZ 0;
BA_ "GenSigFuncType" SG_ 1601 Motor_Code_01_BZ 1;
BA_ "GenSigSwitchedByIgnition" SG_ 1601 Motor_Code_01_BZ 0;
BA_ "GenSigSendType" SG_ 1601 Motor_Code_01_CRC 0;
BA_ "GenSigFuncType" SG_ 1601 Motor_Code_01_CRC 2;
BA_ "GenSigSwitchedByIgnition" SG_ 1601 Motor_Code_01_CRC 0;
BA_ "GenSigSendType" SG_ 1601 TSK_Codierung 0;
BA_ "GenSigStartValue" SG_ 1601 TSK_Codierung 7;
BA_ "GenSigSwitchedByIgnition" SG_ 1601 TSK_Codierung 0;
BA_ "GenSigSendType" SG_ 2527679686 MRR_HR_ASM_Data_1 0;
BA_ "GenSigSendType" SG_ 2527679686 MRR_HR_ASM_Data_2 0;
BA_ "GenSigSendType" SG_ 2527679686 MRR_HR_ASM_Data_3 0;
BA_ "GenSigSendType" SG_ 2527679686 MRR_HR_ASM_Data_4 0;
BA_ "GenSigSendType" SG_ 2527679686 MRR_HR_ASM_Data_5 0;
BA_ "GenSigSendType" SG_ 2527679686 MRR_HR_ASM_Data_6 0;
BA_ "GenSigSendType" SG_ 2527679686 MRR_HR_ASM_Ereignis 3;
BA_ "GenSigSendType" SG_ 2527679686 MRR_HR_ASM_Zeitstempel_02 3;
BA_ "GenSigStartValue" SG_ 2527679686 MRR_HR_ASM_Zeitstempel_02 255;
BA_ "GenSigFuncType" SG_ 2600468499 NM_ABS_CAB_V14 16;
BA_ "GenSigSwitchedByIgnition" SG_ 2600468499 NM_ABS_CAB_V14 0;
BA_ "GenSigSwitchedByIgnition" SG_ 2600468499 NM_ABS_Car_Wakeup 0;
BA_ "GenSigSwitchedByIgnition" SG_ 2600468499 NM_ABS_NM_aktiv_Bewarnung_BKV 0;
BA_ "GenSigSwitchedByIgnition" SG_ 2600468499 NM_ABS_NM_aktiv_Diagnose 0;
BA_ "GenSigSwitchedByIgnition" SG_ 2600468499 NM_ABS_NM_aktiv_EPB_Nachspannen 0;
BA_ "GenSigSwitchedByIgnition" SG_ 2600468499 NM_ABS_NM_aktiv_KL15 0;
BA_ "GenSigSwitchedByIgnition" SG_ 2600468499 NM_ABS_NM_aktiv_Tmin 0;
BA_ "GenSigSwitchedByIgnition" SG_ 2600468499 NM_ABS_NM_aktiv_v_gr_0 0;
BA_ "GenSigSwitchedByIgnition" SG_ 2600468499 NM_ABS_NM_State 0;
BA_ "GenSigSwitchedByIgnition" SG_ 2600468499 NM_ABS_UDS_CC 0;
BA_ "GenSigSwitchedByIgnition" SG_ 2600468499 NM_ESP_CBV_AWB 0;
BA_ "GenSigFuncType" SG_ 2600468499 NM_ESP_CBV_CRI 8;
BA_ "GenSigSwitchedByIgnition" SG_ 2600468499 NM_ESP_CBV_CRI 0;
BA_ "GenSigSwitchedByIgnition" SG_ 2600468499 NM_ESP_NM_aktiv_Anzeige_EPB 0;
BA_ "GenSigSwitchedByIgnition" SG_ 2600468499 NM_ESP_NM_aktiv_Kuehlernachlauf 0;
BA_ "GenSigFuncType" SG_ 2600468501 NM_Airbag_01_CAB_V14 16;
BA_ "GenSigSwitchedByIgnition" SG_ 2600468501 NM_Airbag_01_CAB_V14 0;
BA_ "GenSigSwitchedByIgnition" SG_ 2600468501 NM_Airbag_01_Car_Wakeup 0;
BA_ "GenSigSwitchedByIgnition" SG_ 2600468501 NM_Airbag_01_CBV_AWB 0;
BA_ "GenSigSwitchedByIgnition" SG_ 2600468501 NM_Airbag_01_CBV_CRI 0;
BA_ "GenSigSwitchedByIgnition" SG_ 2600468501 NM_Airbag_01_NM_aktiv_Diagnose 0;
BA_ "GenSigSwitchedByIgnition" SG_ 2600468501 NM_Airbag_01_NM_aktiv_KL15 0;
BA_ "GenSigSwitchedByIgnition" SG_ 2600468501 NM_Airbag_01_NM_aktiv_Tmin 0;
BA_ "GenSigSwitchedByIgnition" SG_ 2600468501 NM_Airbag_01_NM_State 0;
BA_ "GenSigSwitchedByIgnition" SG_ 2600468501 NM_Airbag_01_UDS_CC 0;
BA_ "GenSigFuncType" SG_ 2600468594 NM_Daempfer_CAB_V14 16;
BA_ "GenSigSwitchedByIgnition" SG_ 2600468594 NM_Daempfer_CAB_V14 0;
BA_ "GenSigSwitchedByIgnition" SG_ 2600468594 NM_Daempfer_Car_Wakeup 0;
BA_ "GenSigSwitchedByIgnition" SG_ 2600468594 NM_Daempfer_CBV_AWB 0;
BA_ "GenSigSwitchedByIgnition" SG_ 2600468594 NM_Daempfer_CBV_CRI 0;
BA_ "GenSigSwitchedByIgnition" SG_ 2600468594 NM_Daempfer_NM_aktiv_Diagnose 0;
BA_ "GenSigSwitchedByIgnition" SG_ 2600468594 NM_Daempfer_NM_aktiv_KL15 0;
BA_ "GenSigSwitchedByIgnition" SG_ 2600468594 NM_Daempfer_NM_aktiv_Tmin 0;
BA_ "GenSigSwitchedByIgnition" SG_ 2600468594 NM_Daempfer_NM_State 0;
BA_ "GenSigSwitchedByIgnition" SG_ 2600468594 NM_Daempfer_UDS_CC 0;
BA_ "GenSigFuncType" SG_ 2600468539 NM_EBKV_CAB_V14 16;
BA_ "GenSigSwitchedByIgnition" SG_ 2600468539 NM_EBKV_CAB_V14 0;
BA_ "GenSigSwitchedByIgnition" SG_ 2600468539 NM_EBKV_Car_Wakeup 0;
BA_ "GenSigSwitchedByIgnition" SG_ 2600468539 NM_EBKV_CBV_AWB 0;
BA_ "GenSigFuncType" SG_ 2600468539 NM_EBKV_CBV_CRI 8;
BA_ "GenSigSwitchedByIgnition" SG_ 2600468539 NM_EBKV_CBV_CRI 0;
BA_ "GenSigSwitchedByIgnition" SG_ 2600468539 NM_EBKV_NM_aktiv_Bewarnung 0;
BA_ "GenSigSwitchedByIgnition" SG_ 2600468539 NM_EBKV_NM_aktiv_Diagnose 0;
BA_ "GenSigSwitchedByIgnition" SG_ 2600468539 NM_EBKV_NM_aktiv_KL15 0;
BA_ "GenSigSwitchedByIgnition" SG_ 2600468539 NM_EBKV_NM_aktiv_Tmin 0;
BA_ "GenSigSwitchedByIgnition" SG_ 2600468539 NM_EBKV_NM_aktiv_v_gr_0 0;
BA_ "GenSigSwitchedByIgnition" SG_ 2600468539 NM_EBKV_NM_State 0;
BA_ "GenSigSwitchedByIgnition" SG_ 2600468539 NM_EBKV_UDS_CC 0;
BA_ "GenSigFuncType" SG_ 2600468496 NM_Gateway_CAB_V14 16;
BA_ "GenSigSwitchedByIgnition" SG_ 2600468496 NM_Gateway_CAB_V14 0;
BA_ "GenSigSwitchedByIgnition" SG_ 2600468496 NM_Gateway_Car_Wakeup 0;
BA_ "GenSigSwitchedByIgnition" SG_ 2600468496 NM_Gateway_CBV_AWB 0;
BA_ "GenSigSwitchedByIgnition" SG_ 2600468496 NM_Gateway_CBV_CRI 0;
BA_ "GenSigSwitchedByIgnition" SG_ 2600468496 NM_Gateway_NM_aktiv_Buskopplung 0;
BA_ "GenSigSwitchedByIgnition" SG_ 2600468496 NM_Gateway_NM_aktiv_CWU 0;
BA_ "GenSigSwitchedByIgnition" SG_ 2600468496 NM_Gateway_NM_aktiv_Diagnose 0;
BA_ "GenSigSwitchedByIgnition" SG_ 2600468496 NM_Gateway_NM_aktiv_EM 0;
BA_ "GenSigSwitchedByIgnition" SG_ 2600468496 NM_Gateway_NM_aktiv_FC 0;
BA_ "GenSigSwitchedByIgnition" SG_ 2600468496 NM_Gateway_NM_aktiv_KL15 0;
BA_ "GenSigSwitchedByIgnition" SG_ 2600468496 NM_Gateway_NM_aktiv_Tmin 0;
BA_ "GenSigSwitchedByIgnition" SG_ 2600468496 NM_Gateway_NM_State 0;
BA_ "GenSigSwitchedByIgnition" SG_ 2600468496 NM_Gateway_UDS_CC 0;
BA_ "GenSigSwitchedByIgnition" SG_ 2600468498 NM_EPS_CBV_AWB 0;
BA_ "GenSigFuncType" SG_ 2600468498 NM_EPS_CBV_CRI 8;
BA_ "GenSigSwitchedByIgnition" SG_ 2600468498 NM_EPS_CBV_CRI 0;
BA_ "GenSigFuncType" SG_ 2600468498 NM_Lenkhilfe_CAB_V14 16;
BA_ "GenSigSwitchedByIgnition" SG_ 2600468498 NM_Lenkhilfe_CAB_V14 0;
BA_ "GenSigSwitchedByIgnition" SG_ 2600468498 NM_Lenkhilfe_Car_Wakeup 0;
BA_ "GenSigSwitchedByIgnition" SG_ 2600468498 NM_Lenkhilfe_NM_aktiv_Diagnose 0;
BA_ "GenSigSwitchedByIgnition" SG_ 2600468498 NM_Lenkhilfe_NM_aktiv_DZ_gr_300 0;
BA_ "GenSigSwitchedByIgnition" SG_ 2600468498 NM_Lenkhilfe_NM_aktiv_Fahrbereit 0;
BA_ "GenSigSwitchedByIgnition" SG_ 2600468498 NM_Lenkhilfe_NM_aktiv_Handlenkmo 0;
BA_ "GenSigSwitchedByIgnition" SG_ 2600468498 NM_Lenkhilfe_NM_aktiv_KL15 0;
BA_ "GenSigSwitchedByIgnition" SG_ 2600468498 NM_Lenkhilfe_NM_aktiv_Post_Run 0;
BA_ "GenSigSwitchedByIgnition" SG_ 2600468498 NM_Lenkhilfe_NM_aktiv_Tmin 0;
BA_ "GenSigSwitchedByIgnition" SG_ 2600468498 NM_Lenkhilfe_NM_aktiv_v_gr_7 0;
BA_ "GenSigSwitchedByIgnition" SG_ 2600468498 NM_Lenkhilfe_NM_State 0;
BA_ "GenSigSwitchedByIgnition" SG_ 2600468498 NM_Lenkhilfe_UDS_CC 0;
BA_ "GenSigSendType" SG_ 2621440531 OBDC_ABS_Req_FD_Data 3;
BA_ "GenSigFuncType" SG_ 2621440531 OBDC_ABS_Req_FD_Data 9;
BA_ "GenSigSwitchedByIgnition" SG_ 2621440531 OBDC_ABS_Req_FD_Data 0;
BA_ "GenSigSendType" SG_ 2621571603 OBDC_ABS_Resp_FD_Data 3;
BA_ "GenSigFuncType" SG_ 2621571603 OBDC_ABS_Resp_FD_Data 9;
BA_ "GenSigSwitchedByIgnition" SG_ 2621571603 OBDC_ABS_Resp_FD_Data 0;
BA_ "GenSigSendType" SG_ 2621440533 OBDC_Airbag_01_Req_FD_Data 3;
BA_ "GenSigFuncType" SG_ 2621440533 OBDC_Airbag_01_Req_FD_Data 9;
BA_ "GenSigSwitchedByIgnition" SG_ 2621440533 OBDC_Airbag_01_Req_FD_Data 0;
BA_ "GenSigSendType" SG_ 2621571605 OBDC_Airbag_01_Resp_FD_Data 3;
BA_ "GenSigFuncType" SG_ 2621571605 OBDC_Airbag_01_Resp_FD_Data 9;
BA_ "GenSigSwitchedByIgnition" SG_ 2621571605 OBDC_Airbag_01_Resp_FD_Data 0;
BA_ "GenSigSendType" SG_ 2621440527 OBDC_Allrad_Req_FD_Data 3;
BA_ "GenSigFuncType" SG_ 2621440527 OBDC_Allrad_Req_FD_Data 9;
BA_ "GenSigSwitchedByIgnition" SG_ 2621440527 OBDC_Allrad_Req_FD_Data 0;
BA_ "GenSigSendType" SG_ 2621571599 OBDC_Allrad_Resp_FD_Data 3;
BA_ "GenSigFuncType" SG_ 2621571599 OBDC_Allrad_Resp_FD_Data 9;
BA_ "GenSigSwitchedByIgnition" SG_ 2621571599 OBDC_Allrad_Resp_FD_Data 0;
BA_ "GenSigSendType" SG_ 2621440626 OBDC_Daempfer_Req_FD_Data 3;
BA_ "GenSigFuncType" SG_ 2621440626 OBDC_Daempfer_Req_FD_Data 9;
BA_ "GenSigSwitchedByIgnition" SG_ 2621440626 OBDC_Daempfer_Req_FD_Data 0;
BA_ "GenSigSendType" SG_ 2621571698 OBDC_Daempfer_Resp_FD_Data 3;
BA_ "GenSigFuncType" SG_ 2621571698 OBDC_Daempfer_Resp_FD_Data 9;
BA_ "GenSigSwitchedByIgnition" SG_ 2621571698 OBDC_Daempfer_Resp_FD_Data 0;
BA_ "GenSigSendType" SG_ 2621440571 OBDC_EBKV_Req_FD_Data 3;
BA_ "GenSigFuncType" SG_ 2621440571 OBDC_EBKV_Req_FD_Data 9;
BA_ "GenSigSwitchedByIgnition" SG_ 2621440571 OBDC_EBKV_Req_FD_Data 0;
BA_ "GenSigSendType" SG_ 2621571643 OBDC_EBKV_Resp_FD_Data 3;
BA_ "GenSigFuncType" SG_ 2621571643 OBDC_EBKV_Resp_FD_Data 9;
BA_ "GenSigSwitchedByIgnition" SG_ 2621571643 OBDC_EBKV_Resp_FD_Data 0;
BA_ "GenSigSendType" SG_ 2621506048 OBDC_Funktion_Req_All_FD_Data 3;
BA_ "GenSigFuncType" SG_ 2621506048 OBDC_Funktion_Req_All_FD_Data 9;
BA_ "GenSigSwitchedByIgnition" SG_ 2621506048 OBDC_Funktion_Req_All_FD_Data 0;
BA_ "GenSigSendType" SG_ 2621440530 OBDC_Lenkhilfe_Req_FD_Data 3;
BA_ "GenSigFuncType" SG_ 2621440530 OBDC_Lenkhilfe_Req_FD_Data 9;
BA_ "GenSigSwitchedByIgnition" SG_ 2621440530 OBDC_Lenkhilfe_Req_FD_Data 0;
BA_ "GenSigSendType" SG_ 2621571602 OBDC_Lenkhilfe_Resp_FD_Data 3;
BA_ "GenSigFuncType" SG_ 2621571602 OBDC_Lenkhilfe_Resp_FD_Data 9;
BA_ "GenSigSwitchedByIgnition" SG_ 2621571602 OBDC_Lenkhilfe_Resp_FD_Data 0;
BA_ "GenSigSendType" SG_ 2621440542 OBDC_Quersperre_Req_FD_Data 3;
BA_ "GenSigFuncType" SG_ 2621440542 OBDC_Quersperre_Req_FD_Data 9;
BA_ "GenSigSwitchedByIgnition" SG_ 2621440542 OBDC_Quersperre_Req_FD_Data 0;
BA_ "GenSigSendType" SG_ 2621571614 OBDC_Quersperre_Resp_FD_Data 3;
BA_ "GenSigFuncType" SG_ 2621571614 OBDC_Quersperre_Resp_FD_Data 9;
BA_ "GenSigSwitchedByIgnition" SG_ 2621571614 OBDC_Quersperre_Resp_FD_Data 0;
BA_ "GenSigSendType" SG_ 2621469190 OBDC_SSN_eCS_Req_FD_Data 3;
BA_ "GenSigFuncType" SG_ 2621469190 OBDC_SSN_eCS_Req_FD_Data 9;
BA_ "GenSigSwitchedByIgnition" SG_ 2621469190 OBDC_SSN_eCS_Req_FD_Data 0;
BA_ "GenSigSendType" SG_ 2621600262 OBDC_SSN_eCS_Resp_FD_Data 3;
BA_ "GenSigFuncType" SG_ 2621600262 OBDC_SSN_eCS_Resp_FD_Data 9;
BA_ "GenSigSwitchedByIgnition" SG_ 2621600262 OBDC_SSN_eCS_Resp_FD_Data 0;
BA_ "GenSigSendType" SG_ 2549903646 OBDC_SSN_RGS_HL_Req_Data 3;
BA_ "GenSigFuncType" SG_ 2549903646 OBDC_SSN_RGS_HL_Req_Data 9;
BA_ "GenSigSwitchedByIgnition" SG_ 2549903646 OBDC_SSN_RGS_HL_Req_Data 0;
BA_ "GenSigSendType" SG_ 2550034718 OBDC_SSN_RGS_HL_Resp_Data 3;
BA_ "GenSigFuncType" SG_ 2550034718 OBDC_SSN_RGS_HL_Resp_Data 9;
BA_ "GenSigSwitchedByIgnition" SG_ 2550034718 OBDC_SSN_RGS_HL_Resp_Data 0;
BA_ "GenSigSendType" SG_ 2549903647 OBDC_SSN_RGS_HR_Req_Data 3;
BA_ "GenSigFuncType" SG_ 2549903647 OBDC_SSN_RGS_HR_Req_Data 9;
BA_ "GenSigSwitchedByIgnition" SG_ 2549903647 OBDC_SSN_RGS_HR_Req_Data 0;
BA_ "GenSigSendType" SG_ 2550034719 OBDC_SSN_RGS_HR_Resp_Data 3;
BA_ "GenSigFuncType" SG_ 2550034719 OBDC_SSN_RGS_HR_Resp_Data 9;
BA_ "GenSigSwitchedByIgnition" SG_ 2550034719 OBDC_SSN_RGS_HR_Resp_Data 0;
BA_ "GenSigSendType" SG_ 2549903402 OBDC_SSN_RGS_VL_Req_Data 3;
BA_ "GenSigFuncType" SG_ 2549903402 OBDC_SSN_RGS_VL_Req_Data 9;
BA_ "GenSigSwitchedByIgnition" SG_ 2549903402 OBDC_SSN_RGS_VL_Req_Data 0;
BA_ "GenSigSendType" SG_ 2550034474 OBDC_SSN_RGS_VL_Resp_Data 3;
BA_ "GenSigFuncType" SG_ 2550034474 OBDC_SSN_RGS_VL_Resp_Data 9;
BA_ "GenSigSwitchedByIgnition" SG_ 2550034474 OBDC_SSN_RGS_VL_Resp_Data 0;
BA_ "GenSigSendType" SG_ 2549903403 OBDC_SSN_RGS_VR_Req_Data 3;
BA_ "GenSigFuncType" SG_ 2549903403 OBDC_SSN_RGS_VR_Req_Data 9;
BA_ "GenSigSwitchedByIgnition" SG_ 2549903403 OBDC_SSN_RGS_VR_Req_Data 0;
BA_ "GenSigSendType" SG_ 2550034475 OBDC_SSN_RGS_VR_Resp_Data 3;
BA_ "GenSigFuncType" SG_ 2550034475 OBDC_SSN_RGS_VR_Resp_Data 9;
BA_ "GenSigSwitchedByIgnition" SG_ 2550034475 OBDC_SSN_RGS_VR_Resp_Data 0;
BA_ "GenSigSendType" SG_ 2621440716 OBDC_TSplit_L_Req_FD_Data 3;
BA_ "GenSigFuncType" SG_ 2621440716 OBDC_TSplit_L_Req_FD_Data 9;
BA_ "GenSigSwitchedByIgnition" SG_ 2621440716 OBDC_TSplit_L_Req_FD_Data 0;
BA_ "GenSigSendType" SG_ 2621571788 OBDC_TSplit_L_Resp_FD_Data 3;
BA_ "GenSigFuncType" SG_ 2621571788 OBDC_TSplit_L_Resp_FD_Data 9;
BA_ "GenSigSwitchedByIgnition" SG_ 2621571788 OBDC_TSplit_L_Resp_FD_Data 0;
BA_ "GenSigSendType" SG_ 2621440717 OBDC_TSplit_R_Req_FD_Data 3;
BA_ "GenSigFuncType" SG_ 2621440717 OBDC_TSplit_R_Req_FD_Data 9;
BA_ "GenSigSwitchedByIgnition" SG_ 2621440717 OBDC_TSplit_R_Req_FD_Data 0;
BA_ "GenSigSendType" SG_ 2621571789 OBDC_TSplit_R_Resp_FD_Data 3;
BA_ "GenSigFuncType" SG_ 2621571789 OBDC_TSplit_R_Resp_FD_Data 9;
BA_ "GenSigSwitchedByIgnition" SG_ 2621571789 OBDC_TSplit_R_Resp_FD_Data 0;
BA_ "GenSigSendType" SG_ 2564424945 OBDx_ABS_Req_Data 3;
BA_ "GenSigFuncType" SG_ 2564424945 OBDx_ABS_Req_Data 9;
BA_ "GenSigSwitchedByIgnition" SG_ 2564424945 OBDx_ABS_Req_Data 0;
BA_ "GenSigSendType" SG_ 2564485380 OBDx_ABS_Resp_Data 3;
BA_ "GenSigFuncType" SG_ 2564485380 OBDx_ABS_Resp_Data 9;
BA_ "GenSigSwitchedByIgnition" SG_ 2564485380 OBDx_ABS_Resp_Data 0;
BA_ "GenSigSendType" SG_ 2564502513 OBDx_allOBD_Req_Data 3;
BA_ "GenSigFuncType" SG_ 2564502513 OBDx_allOBD_Req_Data 9;
BA_ "GenSigSwitchedByIgnition" SG_ 2564502513 OBDx_allOBD_Req_Data 0;
BA_ "GenSigSendType" SG_ 2564424689 OBDx_EBKV_Req_Data 3;
BA_ "GenSigFuncType" SG_ 2564424689 OBDx_EBKV_Req_Data 9;
BA_ "GenSigSwitchedByIgnition" SG_ 2564424689 OBDx_EBKV_Req_Data 0;
BA_ "GenSigSendType" SG_ 2564485379 OBDx_EBKV_Resp_Data 3;
BA_ "GenSigFuncType" SG_ 2564485379 OBDx_EBKV_Resp_Data 9;
BA_ "GenSigSwitchedByIgnition" SG_ 2564485379 OBDx_EBKV_Resp_Data 0;
BA_ "GenSigSendType" SG_ 2589283656 ORU_Status 3;
BA_ "GenSigSwitchedByIgnition" SG_ 2589283656 ORU_Status 0;
BA_ "GenSigSendType" SG_ 2589283656 ORU_Warnung 3;
BA_ "GenSigSwitchedByIgnition" SG_ 2589283656 ORU_Warnung 0;
BA_ "GenSigSendType" SG_ 525 PaCo_01_Sendestatus 6;
BA_ "GenSigSwitchedByIgnition" SG_ 525 PaCo_01_Sendestatus 0;
BA_ "GenSigSendType" SG_ 525 PaCo_AAA_Intervention 3;
BA_ "GenSigSwitchedByIgnition" SG_ 525 PaCo_AAA_Intervention 0;
BA_ "GenSigSendType" SG_ 525 PaCo_AAA_TargetState 3;
BA_ "GenSigSwitchedByIgnition" SG_ 525 PaCo_AAA_TargetState 0;
BA_ "GenSigSendType" SG_ 525 PaCo_AEBPR_ImplementationRBFMA 3;
BA_ "GenSigSwitchedByIgnition" SG_ 525 PaCo_AEBPR_ImplementationRBFMA 0;
BA_ "GenSigSendType" SG_ 525 PaCo_AEBPR_InterventionStrategy 3;
BA_ "GenSigSwitchedByIgnition" SG_ 525 PaCo_AEBPR_InterventionStrategy 0;
BA_ "GenSigSendType" SG_ 525 PaCo_APS_AudioLowering 3;
BA_ "GenSigSwitchedByIgnition" SG_ 525 PaCo_APS_AudioLowering 0;
BA_ "GenSigSendType" SG_ 525 PaCo_APS_TargetState 3;
BA_ "GenSigSwitchedByIgnition" SG_ 525 PaCo_APS_TargetState 0;
BA_ "GenSigSendType" SG_ 525 PaCo_APSOPS_DetectionFront 3;
BA_ "GenSigSwitchedByIgnition" SG_ 525 PaCo_APSOPS_DetectionFront 0;
BA_ "GenSigSendType" SG_ 525 PaCo_APSOPS_DetectionRear 3;
BA_ "GenSigSwitchedByIgnition" SG_ 525 PaCo_APSOPS_DetectionRear 0;
BA_ "GenSigSendType" SG_ 525 PaCo_APSOPS_LED 3;
BA_ "GenSigSwitchedByIgnition" SG_ 525 PaCo_APSOPS_LED 0;
BA_ "GenSigSendType" SG_ 525 PaCo_ARA_InterventionStart 3;
BA_ "GenSigSwitchedByIgnition" SG_ 525 PaCo_ARA_InterventionStart 0;
BA_ "GenSigSendType" SG_ 525 PaCo_ARA_TargetState 3;
BA_ "GenSigSwitchedByIgnition" SG_ 525 PaCo_ARA_TargetState 0;
BA_ "GenSigSendType" SG_ 525 PaCo_DiETa_LED 3;
BA_ "GenSigSwitchedByIgnition" SG_ 525 PaCo_DiETa_LED 0;
BA_ "GenSigSendType" SG_ 525 PaCo_MainState 3;
BA_ "GenSigSwitchedByIgnition" SG_ 525 PaCo_MainState 0;
BA_ "Fehlerwert" SG_ 525 PaCo_MainState 7;
BA_ "GenSigSendType" SG_ 525 PaCo_OPS_DrivingTube 3;
BA_ "GenSigSwitchedByIgnition" SG_ 525 PaCo_OPS_DrivingTube 0;
BA_ "GenSigSendType" SG_ 525 PaCo_OPS_TargetState 3;
BA_ "GenSigSwitchedByIgnition" SG_ 525 PaCo_OPS_TargetState 0;
BA_ "GenSigSendType" SG_ 525 PaCo_PLAIPA_InterventionStart 3;
BA_ "GenSigSwitchedByIgnition" SG_ 525 PaCo_PLAIPA_InterventionStart 0;
BA_ "GenSigSendType" SG_ 525 PaCo_PLAIPA_LED 3;
BA_ "GenSigSwitchedByIgnition" SG_ 525 PaCo_PLAIPA_LED 0;
BA_ "GenSigSendType" SG_ 525 PaCo_PLAIPA_PLE 3;
BA_ "GenSigSwitchedByIgnition" SG_ 525 PaCo_PLAIPA_PLE 0;
BA_ "GenSigSendType" SG_ 525 PaCo_PLAIPA_SwitchParkSlot 3;
BA_ "GenSigSwitchedByIgnition" SG_ 525 PaCo_PLAIPA_SwitchParkSlot 0;
BA_ "GenSigSendType" SG_ 525 PaCo_PLAIPA_TargetState 3;
BA_ "GenSigSwitchedByIgnition" SG_ 525 PaCo_PLAIPA_TargetState 0;
BA_ "GenSigSendType" SG_ 525 PaCo_RAB_TargetState 3;
BA_ "GenSigSwitchedByIgnition" SG_ 525 PaCo_RAB_TargetState 0;
BA_ "GenSigSendType" SG_ 525 PaCo_RBFMA_ImplementationAEBPR 3;
BA_ "GenSigSwitchedByIgnition" SG_ 525 PaCo_RBFMA_ImplementationAEBPR 0;
BA_ "GenSigSendType" SG_ 525 PaCo_RBFMA_InterventionStrategy 3;
BA_ "GenSigSwitchedByIgnition" SG_ 525 PaCo_RBFMA_InterventionStrategy 0;
BA_ "GenSigSendType" SG_ 525 PaCo_RCTA_InterventionStrategy 3;
BA_ "GenSigSwitchedByIgnition" SG_ 525 PaCo_RCTA_InterventionStrategy 0;
BA_ "GenSigSendType" SG_ 525 PaCo_RCTA_Warning 3;
BA_ "GenSigSwitchedByIgnition" SG_ 525 PaCo_RCTA_Warning 0;
BA_ "GenSigSendType" SG_ 525 PaCo_TPA_TargetState 3;
BA_ "GenSigSwitchedByIgnition" SG_ 525 PaCo_TPA_TargetState 0;
BA_ "GenSigSendType" SG_ 525 PaCo_VPS_DarkenVideo 3;
BA_ "GenSigSwitchedByIgnition" SG_ 525 PaCo_VPS_DarkenVideo 0;
BA_ "GenSigSendType" SG_ 525 PaCo_VPS_LED 3;
BA_ "GenSigSwitchedByIgnition" SG_ 525 PaCo_VPS_LED 0;
BA_ "GenSigSendType" SG_ 525 PaCo_VPS_PLE 3;
BA_ "GenSigSwitchedByIgnition" SG_ 525 PaCo_VPS_PLE 0;
BA_ "GenSigSendType" SG_ 525 PaCo_VPS_TargetBirdview 3;
BA_ "GenSigSwitchedByIgnition" SG_ 525 PaCo_VPS_TargetBirdview 0;
BA_ "GenSigSendType" SG_ 525 PaCo_VPS_TargetBowl 3;
BA_ "GenSigSwitchedByIgnition" SG_ 525 PaCo_VPS_TargetBowl 0;
BA_ "GenSigSendType" SG_ 525 PaCo_VPS_TargetCarOverlay 3;
BA_ "GenSigSwitchedByIgnition" SG_ 525 PaCo_VPS_TargetCarOverlay 0;
BA_ "GenSigSendType" SG_ 525 PaCo_VPS_TargetGraphicOverlay 3;
BA_ "GenSigSwitchedByIgnition" SG_ 525 PaCo_VPS_TargetGraphicOverlay 0;
BA_ "GenSigSendType" SG_ 525 PaCo_VPS_TargetMode 3;
BA_ "GenSigSwitchedByIgnition" SG_ 525 PaCo_VPS_TargetMode 0;
BA_ "GenSigSendType" SG_ 525 PaCo_VPS_TargetRVCscreen 3;
BA_ "GenSigSwitchedByIgnition" SG_ 525 PaCo_VPS_TargetRVCscreen 0;
BA_ "GenSigSendType" SG_ 525 PaCo_VPS_TargetState 3;
BA_ "GenSigSwitchedByIgnition" SG_ 525 PaCo_VPS_TargetState 0;
BA_ "GenSigSendType" SG_ 525 PaCo_VPS_TargetView 3;
BA_ "GenSigSwitchedByIgnition" SG_ 525 PaCo_VPS_TargetView 0;
BA_ "GenSigSendType" SG_ 2527679741 PAO_OFF_Status 0;
BA_ "GenSigSwitchedByIgnition" SG_ 2527679741 PAO_OFF_Status 0;
BA_ "GenSigSendType" SG_ 2527679741 PAO_ON_Status 0;
BA_ "GenSigSwitchedByIgnition" SG_ 2527679741 PAO_ON_Status 0;
BA_ "GenSigSendType" SG_ 2527679741 PAO_Status_01_BZ 0;
BA_ "GenSigFuncType" SG_ 2527679741 PAO_Status_01_BZ 1;
BA_ "GenSigSwitchedByIgnition" SG_ 2527679741 PAO_Status_01_BZ 0;
BA_ "GenSigSendType" SG_ 2527679741 PAO_Status_01_CRC 0;
BA_ "GenSigFuncType" SG_ 2527679741 PAO_Status_01_CRC 2;
BA_ "GenSigSwitchedByIgnition" SG_ 2527679741 PAO_Status_01_CRC 0;
BA_ "GenSigSendType" SG_ 2527679741 PAO_Status_Reserve_Byte3 0;
BA_ "GenSigSwitchedByIgnition" SG_ 2527679741 PAO_Status_Reserve_Byte3 0;
BA_ "GenSigSendType" SG_ 518 IPA_TPA_Abbruch 0;
BA_ "GenSigSwitchedByIgnition" SG_ 518 IPA_TPA_Abbruch 0;
BA_ "GenSigSendType" SG_ 518 IPA_TPA_ausgerichtetes_Parken 0;
BA_ "GenSigSwitchedByIgnition" SG_ 518 IPA_TPA_ausgerichtetes_Parken 0;
BA_ "GenSigSendType" SG_ 518 IPA_TPA_Fehler 0;
BA_ "GenSigSwitchedByIgnition" SG_ 518 IPA_TPA_Fehler 0;
BA_ "GenSigSendType" SG_ 518 IPA_TPA_Remote 0;
BA_ "GenSigSwitchedByIgnition" SG_ 518 IPA_TPA_Remote 0;
BA_ "GenSigSendType" SG_ 518 IPA_TPA_Remote_Anf 0;
BA_ "GenSigSwitchedByIgnition" SG_ 518 IPA_TPA_Remote_Anf 0;
BA_ "GenSigSendType" SG_ 518 IPA_TPA_Status 0;
BA_ "GenSigStartValue" SG_ 518 IPA_TPA_Status 1;
BA_ "GenSigSwitchedByIgnition" SG_ 518 IPA_TPA_Status 0;
BA_ "GenSigSendType" SG_ 518 Parken_01_BZ 0;
BA_ "GenSigFuncType" SG_ 518 Parken_01_BZ 1;
BA_ "GenSigSwitchedByIgnition" SG_ 518 Parken_01_BZ 0;
BA_ "GenSigSendType" SG_ 518 Parken_01_CRC 0;
BA_ "GenSigFuncType" SG_ 518 Parken_01_CRC 2;
BA_ "GenSigSwitchedByIgnition" SG_ 518 Parken_01_CRC 0;
BA_ "GenSigSendType" SG_ 518 Parken_aktives_System 0;
BA_ "GenSigSendType" SG_ 518 Parken_Anforderung_HMS 0;
BA_ "GenSigSwitchedByIgnition" SG_ 518 Parken_Anforderung_HMS 0;
BA_ "GenSigSendType" SG_ 518 Parken_Anhalteweg_Anf 0;
BA_ "GenSigStartValue" SG_ 518 Parken_Anhalteweg_Anf 1022;
BA_ "GenSigSwitchedByIgnition" SG_ 518 Parken_Anhalteweg_Anf 0;
BA_ "Fehlerwert" SG_ 518 Parken_Anhalteweg_Anf 1023;
BA_ "GenSigSendType" SG_ 518 Parken_beibehalten 0;
BA_ "GenSigStartValue" SG_ 518 Parken_beibehalten 2;
BA_ "GenSigSwitchedByIgnition" SG_ 518 Parken_beibehalten 0;
BA_ "Fehlerwert" SG_ 518 Parken_beibehalten 3;
BA_ "GenSigSendType" SG_ 518 Parken_BKD_Anf 0;
BA_ "GenSigStartValue" SG_ 518 Parken_BKD_Anf 14;
BA_ "GenSigSwitchedByIgnition" SG_ 518 Parken_BKD_Anf 0;
BA_ "Fehlerwert" SG_ 518 Parken_BKD_Anf 15;
BA_ "GenSigSendType" SG_ 518 Parken_Bordstein_Winkel 0;
BA_ "GenSigSwitchedByIgnition" SG_ 518 Parken_Bordstein_Winkel 0;
BA_ "GenSigSendType" SG_ 518 Parken_erhoehtes_Moment 0;
BA_ "GenSigSwitchedByIgnition" SG_ 518 Parken_erhoehtes_Moment 0;
BA_ "GenSigSendType" SG_ 518 Parken_Fahrbereitschaft_Anf 0;
BA_ "GenSigSendType" SG_ 518 Parken_Fahrstufenwunsch 0;
BA_ "GenSigSendType" SG_ 518 Parken_max_Beschleunigung 0;
BA_ "GenSigStartValue" SG_ 518 Parken_max_Beschleunigung 122;
BA_ "GenSigSwitchedByIgnition" SG_ 518 Parken_max_Beschleunigung 0;
BA_ "Fehlerwert" SG_ 518 Parken_max_Beschleunigung 127;
BA_ "GenSigSendType" SG_ 518 Parken_max_Geschwindigkeit 0;
BA_ "GenSigStartValue" SG_ 518 Parken_max_Geschwindigkeit 251;
BA_ "GenSigSwitchedByIgnition" SG_ 518 Parken_max_Geschwindigkeit 0;
BA_ "Fehlerwert" SG_ 518 Parken_max_Geschwindigkeit 255;
BA_ "GenSigSendType" SG_ 518 Parken_Motorlauf_Anf 0;
BA_ "GenSigSendType" SG_ 518 Parken_Notstopp_Anf 0;
BA_ "GenSigSwitchedByIgnition" SG_ 518 Parken_Notstopp_Anf 0;
BA_ "GenSigSendType" SG_ 518 Parken_Prefill_Anf 0;
BA_ "GenSigSwitchedByIgnition" SG_ 518 Parken_Prefill_Anf 0;
BA_ "GenSigSendType" SG_ 518 Parken_QFK_AnfStat 0;
BA_ "GenSigStartValue" SG_ 518 Parken_QFK_AnfStat 1;
BA_ "GenSigSendType" SG_ 518 Parken_QFK_Art1 0;
BA_ "GenSigSendType" SG_ 518 Parken_QFK_Art2 0;
BA_ "GenSigSendType" SG_ 518 Parken_QFK_KruemmSoll 0;
BA_ "GenSigSendType" SG_ 518 Parken_QFK_KruemmSoll_VZ 0;
BA_ "GenSigSendType" SG_ 518 Parken_QFK_Signal1 0;
BA_ "GenSigSendType" SG_ 518 Parken_QFK_Signal2 0;
BA_ "GenSigSendType" SG_ 518 Parken_QFK_Spuerb 0;
BA_ "GenSigSendType" SG_ 518 Parken_Schleichfahrt_Anf 0;
BA_ "GenSigSendType" SG_ 518 Parken_Soll_Anhalteweg_Anf 0;
BA_ "GenSigStartValue" SG_ 518 Parken_Soll_Anhalteweg_Anf 1022;
BA_ "GenSigSwitchedByIgnition" SG_ 518 Parken_Soll_Anhalteweg_Anf 0;
BA_ "Fehlerwert" SG_ 518 Parken_Soll_Anhalteweg_Anf 1023;
BA_ "GenSigSendType" SG_ 518 Parken_Sollbeschleunigung 0;
BA_ "GenSigSendType" SG_ 518 Parken_Status_IPA_TSK 0;
BA_ "GenSigStartValue" SG_ 518 Parken_Status_IPA_TSK 1;
BA_ "GenSigSwitchedByIgnition" SG_ 518 Parken_Status_IPA_TSK 0;
BA_ "GenSigSendType" SG_ 518 Parken_Verz_Anf 0;
BA_ "GenSigStartValue" SG_ 518 Parken_Verz_Anf 126;
BA_ "GenSigSwitchedByIgnition" SG_ 518 Parken_Verz_Anf 0;
BA_ "GenSigSendType" SG_ 518 Parken_Verz_Anf_ASIL 0;
BA_ "GenSigSwitchedByIgnition" SG_ 518 Parken_Verz_Anf_ASIL 0;
BA_ "GenSigSendType" SG_ 518 Parken_Warnruck_Anf 0;
BA_ "GenSigSwitchedByIgnition" SG_ 518 Parken_Warnruck_Anf 0;
BA_ "GenSigSendType" SG_ 518 Parken_Warnruckeln_Anf 0;
BA_ "GenSigSwitchedByIgnition" SG_ 518 Parken_Warnruckeln_Anf 0;
BA_ "GenSigSendType" SG_ 2331595837 PCH_Kritikalitaetsklasse 0;
BA_ "GenSigSendType" SG_ 2331595837 PCH_MessZeitpunkt 0;
BA_ "GenSigStartValue" SG_ 2331595837 PCH_MessZeitpunkt 8191;
BA_ "GenSigSendType" SG_ 2331595837 PCH_Object_aAbsX 0;
BA_ "GenSigStartValue" SG_ 2331595837 PCH_Object_aAbsX 4095;
BA_ "GenSigSendType" SG_ 2331595837 PCH_Object_aAbsY 0;
BA_ "GenSigStartValue" SG_ 2331595837 PCH_Object_aAbsY 4095;
BA_ "GenSigSendType" SG_ 2331595837 PCH_Object_Class 0;
BA_ "GenSigStartValue" SG_ 2331595837 PCH_Object_Class 15;
BA_ "GenSigSendType" SG_ 2331595837 PCH_Object_PosX 0;
BA_ "GenSigStartValue" SG_ 2331595837 PCH_Object_PosX 16383;
BA_ "GenSigSendType" SG_ 2331595837 PCH_Object_PosY 0;
BA_ "GenSigStartValue" SG_ 2331595837 PCH_Object_PosY 8191;
BA_ "GenSigSendType" SG_ 2331595837 PCH_Object_vAbsX 0;
BA_ "GenSigStartValue" SG_ 2331595837 PCH_Object_vAbsX 4095;
BA_ "GenSigSendType" SG_ 2331595837 PCH_Object_vAbsY 0;
BA_ "GenSigStartValue" SG_ 2331595837 PCH_Object_vAbsY 4095;
BA_ "GenSigSendType" SG_ 2331595837 PCH_Object_Width 0;
BA_ "GenSigStartValue" SG_ 2331595837 PCH_Object_Width 255;
BA_ "GenSigSendType" SG_ 2331595837 PCH_Status 0;
BA_ "Fehlerwert" SG_ 2331595837 PCH_Status 7;
BA_ "GenSigSendType" SG_ 2331595837 PCH_TTC 0;
BA_ "GenSigStartValue" SG_ 2331595837 PCH_TTC 8190;
BA_ "Fehlerwert" SG_ 2331595837 PCH_TTC 8191;
BA_ "GenSigSendType" SG_ 802 PCR_Crashwahrscheinlichkeit 0;
BA_ "Fehlerwert" SG_ 802 PCR_Crashwahrscheinlichkeit 127;
BA_ "GenSigSendType" SG_ 802 PCR_Obj_Guete 0;
BA_ "Fehlerwert" SG_ 802 PCR_Obj_Guete 127;
BA_ "GenSigSendType" SG_ 802 PCR_Obj_TTC 0;
BA_ "GenSigStartValue" SG_ 802 PCR_Obj_TTC 510;
BA_ "Fehlerwert" SG_ 802 PCR_Obj_TTC 511;
BA_ "GenSigSendType" SG_ 802 PCR_Obj_vx_rel 0;
BA_ "Fehlerwert" SG_ 802 PCR_Obj_vx_rel 2047;
BA_ "GenSigSendType" SG_ 802 PCR_Obj_vy_rel 0;
BA_ "Fehlerwert" SG_ 802 PCR_Obj_vy_rel 2047;
BA_ "GenSigSendType" SG_ 802 PCR_Sensorstatus 0;
BA_ "GenSigSendType" SG_ 802 PCR_Sensorstatus_02 0;
BA_ "GenSigSwitchedByIgnition" SG_ 802 PCR_Sensorstatus_02 0;
BA_ "GenSigSendType" SG_ 796 PCS_Li_BlockID 0;
BA_ "GenSigSendType" SG_ 796 PCS_Li_CS 0;
BA_ "GenSigStartValue" SG_ 796 PCS_Li_CS 126;
BA_ "Fehlerwert" SG_ 796 PCS_Li_CS 127;
BA_ "GenSigSendType" SG_ 796 PCS_Li_CS_Konfidenz 0;
BA_ "Fehlerwert" SG_ 796 PCS_Li_CS_Konfidenz 127;
BA_ "GenSigSendType" SG_ 796 PCS_Li_CW 0;
BA_ "GenSigStartValue" SG_ 796 PCS_Li_CW 126;
BA_ "Fehlerwert" SG_ 796 PCS_Li_CW 127;
BA_ "GenSigSendType" SG_ 796 PCS_Li_CW_Konfidenz 0;
BA_ "Fehlerwert" SG_ 796 PCS_Li_CW_Konfidenz 127;
BA_ "GenSigSendType" SG_ 796 PCS_Li_MessZeitpunkt 0;
BA_ "GenSigStartValue" SG_ 796 PCS_Li_MessZeitpunkt 8191;
BA_ "GenSigSendType" SG_ 796 PCS_Li_Status 0;
BA_ "Fehlerwert" SG_ 796 PCS_Li_Status 15;
BA_ "GenSigSendType" SG_ 796 PCS_Li_TTC 0;
BA_ "GenSigStartValue" SG_ 796 PCS_Li_TTC 1022;
BA_ "Fehlerwert" SG_ 796 PCS_Li_TTC 1023;
BA_ "GenSigSendType" SG_ 796 PCS_Li_TTC_StdAbw 0;
BA_ "Fehlerwert" SG_ 796 PCS_Li_TTC_StdAbw 127;
BA_ "GenSigSendType" SG_ 797 PCS_Re_BlockID 0;
BA_ "GenSigSendType" SG_ 797 PCS_Re_CS 0;
BA_ "GenSigStartValue" SG_ 797 PCS_Re_CS 126;
BA_ "Fehlerwert" SG_ 797 PCS_Re_CS 127;
BA_ "GenSigSendType" SG_ 797 PCS_Re_CS_Konfidenz 0;
BA_ "GenSigStartValue" SG_ 797 PCS_Re_CS_Konfidenz 126;
BA_ "Fehlerwert" SG_ 797 PCS_Re_CS_Konfidenz 127;
BA_ "GenSigSendType" SG_ 797 PCS_Re_CW 0;
BA_ "GenSigStartValue" SG_ 797 PCS_Re_CW 126;
BA_ "Fehlerwert" SG_ 797 PCS_Re_CW 127;
BA_ "GenSigSendType" SG_ 797 PCS_Re_CW_Konfidenz 0;
BA_ "GenSigStartValue" SG_ 797 PCS_Re_CW_Konfidenz 126;
BA_ "Fehlerwert" SG_ 797 PCS_Re_CW_Konfidenz 127;
BA_ "GenSigSendType" SG_ 797 PCS_Re_MessZeitpunkt 0;
BA_ "GenSigStartValue" SG_ 797 PCS_Re_MessZeitpunkt 8191;
BA_ "GenSigSendType" SG_ 797 PCS_Re_Status 0;
BA_ "Fehlerwert" SG_ 797 PCS_Re_Status 15;
BA_ "GenSigSendType" SG_ 797 PCS_Re_TTC 0;
BA_ "GenSigStartValue" SG_ 797 PCS_Re_TTC 1022;
BA_ "Fehlerwert" SG_ 797 PCS_Re_TTC 1023;
BA_ "GenSigSendType" SG_ 797 PCS_Re_TTC_StdAbw 0;
BA_ "GenSigStartValue" SG_ 797 PCS_Re_TTC_StdAbw 126;
BA_ "Fehlerwert" SG_ 797 PCS_Re_TTC_StdAbw 127;
BA_ "GenSigSendType" SG_ 2527679685 PDC_ASM_Data_1 0;
BA_ "GenSigSendType" SG_ 2527679685 PDC_ASM_Data_2 0;
BA_ "GenSigSendType" SG_ 2527679685 PDC_ASM_Data_3 0;
BA_ "GenSigSendType" SG_ 2527679685 PDC_ASM_Data_4 0;
BA_ "GenSigSendType" SG_ 2527679685 PDC_ASM_Data_5 0;
BA_ "GenSigSendType" SG_ 2527679685 PDC_ASM_Data_6 0;
BA_ "GenSigSendType" SG_ 2527679685 PDC_ASM_Ereignis 3;
BA_ "GenSigSendType" SG_ 2527679685 PDC_ASM_Zeitstempel_02 3;
BA_ "GenSigStartValue" SG_ 2527679685 PDC_ASM_Zeitstempel_02 255;
BA_ "GenSigSendType" SG_ 770 PLA_05_Sendestatus 6;
BA_ "GenSigSendType" SG_ 770 PLA_QFK_AnfStat 0;
BA_ "GenSigStartValue" SG_ 770 PLA_QFK_AnfStat 1;
BA_ "GenSigSendType" SG_ 770 PLA_QFK_Art1 0;
BA_ "GenSigSendType" SG_ 770 PLA_QFK_Art2 0;
BA_ "GenSigSendType" SG_ 770 PLA_QFK_KrSoll 0;
BA_ "GenSigStartValue" SG_ 770 PLA_QFK_KrSoll 65535;
BA_ "GenSigSendType" SG_ 770 PLA_QFK_KrSoll_VZ 0;
BA_ "GenSigSendType" SG_ 770 PLA_QFK_KruemmSoll 0;
BA_ "GenSigSendType" SG_ 770 PLA_QFK_KruemmSoll_VZ 0;
BA_ "GenSigSendType" SG_ 770 PLA_QFK_Signal1 0;
BA_ "GenSigSendType" SG_ 770 PLA_QFK_Signal2 0;
BA_ "GenSigSendType" SG_ 770 PLA_QFK_Spuerb 0;
BA_ "GenSigSendType" SG_ 770 SOK_PLA_05_Signatur 0;
BA_ "GenSigFuncType" SG_ 770 SOK_PLA_05_Signatur 15;
BA_ "GenSigSwitchedByIgnition" SG_ 770 SOK_PLA_05_Signatur 0;
BA_ "GenSigSendType" SG_ 319 PreCrash_Anforderung_AFR 3;
BA_ "GenSigStartValue" SG_ 319 PreCrash_Anforderung_AFR 7;
BA_ "GenSigSwitchedByIgnition" SG_ 319 PreCrash_Anforderung_AFR 0;
BA_ "GenSigSendType" SG_ 319 PreCrash_BFS_KSV_verfahren 3;
BA_ "GenSigSwitchedByIgnition" SG_ 319 PreCrash_BFS_KSV_verfahren 0;
BA_ "GenSigSendType" SG_ 319 PreCrash_BFS_Laengsverstellung 3;
BA_ "GenSigSwitchedByIgnition" SG_ 319 PreCrash_BFS_Laengsverstellung 0;
BA_ "GenSigSendType" SG_ 319 PreCrash_BFS_Pneumatik_ansteuern 3;
BA_ "GenSigSwitchedByIgnition" SG_ 319 PreCrash_BFS_Pneumatik_ansteuern 0;
BA_ "GenSigSendType" SG_ 319 PreCrash_BFS_Sitzlehne_verfahren 3;
BA_ "GenSigSwitchedByIgnition" SG_ 319 PreCrash_BFS_Sitzlehne_verfahren 0;
BA_ "GenSigSendType" SG_ 319 PreCrash_Blinken 3;
BA_ "GenSigSendType" SG_ 319 PreCrash_Charisma_FahrPr 0;
BA_ "GenSigSendType" SG_ 319 PreCrash_Charisma_Status 0;
BA_ "GenSigSendType" SG_ 319 PreCrash_Fenster_schliessen 3;
BA_ "GenSigSendType" SG_ 319 PreCrash_Fo_KSV_verfahren 3;
BA_ "GenSigSendType" SG_ 319 PreCrash_Fo_Pneumatik_ansteuern 3;
BA_ "GenSigSendType" SG_ 319 PreCrash_Fo_Sitzlehne_verfahren 3;
BA_ "GenSigSwitchedByIgnition" SG_ 319 PreCrash_Fo_Sitzlehne_verfahren 0;
BA_ "GenSigSendType" SG_ 319 PreCrash_FS_KSV_verfahren 3;
BA_ "GenSigSwitchedByIgnition" SG_ 319 PreCrash_FS_KSV_verfahren 0;
BA_ "GenSigSendType" SG_ 319 PreCrash_FS_Laengsverstellung 3;
BA_ "GenSigSwitchedByIgnition" SG_ 319 PreCrash_FS_Laengsverstellung 0;
BA_ "GenSigSendType" SG_ 319 PreCrash_FS_Pneumatik_ansteuern 3;
BA_ "GenSigSwitchedByIgnition" SG_ 319 PreCrash_FS_Pneumatik_ansteuern 0;
BA_ "GenSigSendType" SG_ 319 PreCrash_FS_Sitzlehne_verfahren 3;
BA_ "GenSigSwitchedByIgnition" SG_ 319 PreCrash_FS_Sitzlehne_verfahren 0;
BA_ "GenSigSendType" SG_ 319 PreCrash_Schiebedach_schliessen 3;
BA_ "GenSigSendType" SG_ 319 PreCrash_Tueren_Verriegeln 3;
BA_ "GenSigSwitchedByIgnition" SG_ 319 PreCrash_Tueren_Verriegeln 0;
BA_ "GenSigSendType" SG_ 319 SC_PreCrash_LED 3;
BA_ "GenSigSwitchedByIgnition" SG_ 319 SC_PreCrash_LED 0;
BA_ "GenSigSendType" SG_ 319 SC_PreCrash_Texte 3;
BA_ "GenSigSwitchedByIgnition" SG_ 319 SC_PreCrash_Texte 0;
BA_ "GenSigSendType" SG_ 319 SC_PreCrash_Warnung 3;
BA_ "GenSigSwitchedByIgnition" SG_ 319 SC_PreCrash_Warnung 0;
BA_ "GenSigSendType" SG_ 319 SC_PreSense_FCWP 3;
BA_ "GenSigSwitchedByIgnition" SG_ 319 SC_PreSense_FCWP 0;
BA_ "GenSigSendType" SG_ 317 QFK_01_BZ 0;
BA_ "GenSigFuncType" SG_ 317 QFK_01_BZ 1;
BA_ "GenSigSwitchedByIgnition" SG_ 317 QFK_01_BZ 0;
BA_ "GenSigSendType" SG_ 317 QFK_01_CRC 0;
BA_ "GenSigFuncType" SG_ 317 QFK_01_CRC 2;
BA_ "GenSigSwitchedByIgnition" SG_ 317 QFK_01_CRC 0;
BA_ "GenSigSendType" SG_ 317 QFK_01_Sendestatus 6;
BA_ "GenSigSwitchedByIgnition" SG_ 317 QFK_01_Sendestatus 0;
BA_ "GenSigSendType" SG_ 317 QFK_Anf_Giermomoffset 0;
BA_ "GenSigSwitchedByIgnition" SG_ 317 QFK_Anf_Giermomoffset 0;
BA_ "GenSigSendType" SG_ 317 QFK_Anf_Giermomoffset_VZ 0;
BA_ "GenSigSwitchedByIgnition" SG_ 317 QFK_Anf_Giermomoffset_VZ 0;
BA_ "GenSigSendType" SG_ 317 QFK_DynBegr_aktiv 0;
BA_ "GenSigSwitchedByIgnition" SG_ 317 QFK_DynBegr_aktiv 0;
BA_ "GenSigSendType" SG_ 317 QFK_IstKraft 0;
BA_ "GenSigSwitchedByIgnition" SG_ 317 QFK_IstKraft 0;
BA_ "Fehlerwert" SG_ 317 QFK_IstKraft 1023;
BA_ "GenSigSendType" SG_ 317 QFK_IstKraft_VZ 0;
BA_ "GenSigSwitchedByIgnition" SG_ 317 QFK_IstKraft_VZ 0;
BA_ "GenSigSendType" SG_ 317 QFK_IstKraftNiveau 0;
BA_ "GenSigSwitchedByIgnition" SG_ 317 QFK_IstKraftNiveau 0;
BA_ "GenSigSendType" SG_ 317 QFK_IstKraftNiveau_VZ 0;
BA_ "GenSigSwitchedByIgnition" SG_ 317 QFK_IstKraftNiveau_VZ 0;
BA_ "GenSigSendType" SG_ 317 QFK_KrIst 0;
BA_ "GenSigStartValue" SG_ 317 QFK_KrIst 65534;
BA_ "GenSigSwitchedByIgnition" SG_ 317 QFK_KrIst 0;
BA_ "Fehlerwert" SG_ 317 QFK_KrIst 65535;
BA_ "GenSigSendType" SG_ 317 QFK_KrIst_VZ 0;
BA_ "GenSigSwitchedByIgnition" SG_ 317 QFK_KrIst_VZ 0;
BA_ "GenSigSendType" SG_ 317 QFK_KruemmIst 0;
BA_ "GenSigSwitchedByIgnition" SG_ 317 QFK_KruemmIst 0;
BA_ "GenSigSendType" SG_ 317 QFK_KruemmIst_VZ 0;
BA_ "GenSigSwitchedByIgnition" SG_ 317 QFK_KruemmIst_VZ 0;
BA_ "GenSigSendType" SG_ 317 QFK_Status 0;
BA_ "GenSigStartValue" SG_ 317 QFK_Status 1;
BA_ "GenSigSwitchedByIgnition" SG_ 317 QFK_Status 0;
BA_ "GenSigSendType" SG_ 317 QFK_stAWV 0;
BA_ "GenSigStartValue" SG_ 317 QFK_stAWV 1;
BA_ "GenSigSwitchedByIgnition" SG_ 317 QFK_stAWV 0;
BA_ "GenSigSendType" SG_ 317 QFK_stDSR 0;
BA_ "GenSigStartValue" SG_ 317 QFK_stDSR 1;
BA_ "GenSigSwitchedByIgnition" SG_ 317 QFK_stDSR 0;
BA_ "GenSigSendType" SG_ 317 QFK_stEingriffBr 0;
BA_ "GenSigSwitchedByIgnition" SG_ 317 QFK_stEingriffBr 0;
BA_ "GenSigSendType" SG_ 317 QFK_stHCA 0;
BA_ "GenSigStartValue" SG_ 317 QFK_stHCA 1;
BA_ "GenSigSendType" SG_ 317 QFK_stPLA 0;
BA_ "GenSigStartValue" SG_ 317 QFK_stPLA 1;
BA_ "GenSigSwitchedByIgnition" SG_ 317 QFK_stPLA 0;
BA_ "GenSigSendType" SG_ 317 QFK_stRHP 0;
BA_ "GenSigStartValue" SG_ 317 QFK_stRHP 1;
BA_ "GenSigSendType" SG_ 317 QFK_ZPosIst 0;
BA_ "GenSigStartValue" SG_ 317 QFK_ZPosIst 65535;
BA_ "GenSigSwitchedByIgnition" SG_ 317 QFK_ZPosIst 0;
BA_ "GenSigSendType" SG_ 317 QFK_ZPosIst_VZ 0;
BA_ "GenSigSendType" SG_ 317 SOK_QFK_01_Signatur 0;
BA_ "GenSigFuncType" SG_ 317 SOK_QFK_01_Signatur 15;
BA_ "GenSigSendType" SG_ 1023 Quersperre_04_BZ 0;
BA_ "GenSigFuncType" SG_ 1023 Quersperre_04_BZ 1;
BA_ "GenSigSwitchedByIgnition" SG_ 1023 Quersperre_04_BZ 0;
BA_ "GenSigSendType" SG_ 1023 Quersperre_04_CRC 0;
BA_ "GenSigFuncType" SG_ 1023 Quersperre_04_CRC 2;
BA_ "GenSigSwitchedByIgnition" SG_ 1023 Quersperre_04_CRC 0;
BA_ "GenSigSendType" SG_ 1023 Quersperre_Anz_Sperre_Auslegen 3;
BA_ "GenSigSendType" SG_ 1023 Quersperre_Anz_Sperre_Einlegen 3;
BA_ "GenSigSendType" SG_ 1023 Quersperre_Anz_Sperre_Geschl 3;
BA_ "GenSigSendType" SG_ 1023 Quersperre_Istzustand 3;
BA_ "GenSigSwitchedByIgnition" SG_ 1023 Quersperre_Istzustand 0;
BA_ "Fehlerwert" SG_ 1023 Quersperre_Istzustand 7;
BA_ "GenSigSendType" SG_ 1023 Quersperre_Status 3;
BA_ "GenSigSwitchedByIgnition" SG_ 1023 Quersperre_Status 0;
BA_ "GenSigSendType" SG_ 1616 RA_AM_Tuning 3;
BA_ "GenSigSwitchedByIgnition" SG_ 1616 RA_AM_Tuning 0;
BA_ "GenSigSendType" SG_ 1616 RA_Frequency 3;
BA_ "GenSigSwitchedByIgnition" SG_ 1616 RA_Frequency 0;
BA_ "GenSigSendType" SG_ 1616 RA_Frequency_unit 3;
BA_ "GenSigSwitchedByIgnition" SG_ 1616 RA_Frequency_unit 0;
BA_ "GenSigSendType" SG_ 1616 RA_PowerAmpOn 3;
BA_ "GenSigSwitchedByIgnition" SG_ 1616 RA_PowerAmpOn 0;
BA_ "GenSigSendType" SG_ 1616 RA_Radio_Error_Flag 3;
BA_ "GenSigSwitchedByIgnition" SG_ 1616 RA_Radio_Error_Flag 0;
BA_ "GenSigSendType" SG_ 1616 RA_Radio_mute 3;
BA_ "GenSigSwitchedByIgnition" SG_ 1616 RA_Radio_mute 0;
BA_ "GenSigSendType" SG_ 1616 RA_Radio_on 3;
BA_ "GenSigSwitchedByIgnition" SG_ 1616 RA_Radio_on 0;
BA_ "GenSigSendType" SG_ 1616 RA_Radio_Surround 3;
BA_ "GenSigSwitchedByIgnition" SG_ 1616 RA_Radio_Surround 0;
BA_ "GenSigSendType" SG_ 1616 RA_VNC_OFF 3;
BA_ "GenSigSwitchedByIgnition" SG_ 1616 RA_VNC_OFF 0;
BA_ "GenSigSendType" SG_ 695 RCTA_01_BZ 0;
BA_ "GenSigFuncType" SG_ 695 RCTA_01_BZ 1;
BA_ "GenSigSendType" SG_ 695 RCTA_01_CRC 0;
BA_ "GenSigFuncType" SG_ 695 RCTA_01_CRC 2;
BA_ "GenSigSendType" SG_ 695 RCTA_Anf_Warnruck 0;
BA_ "GenSigSendType" SG_ 695 RCTA_Anforderung_HMS 0;
BA_ "GenSigSendType" SG_ 695 RCTA_Bremsruck_Anforderung 0;
BA_ "GenSigSendType" SG_ 695 RCTA_Bremsruck_Freigabe 0;
BA_ "GenSigSendType" SG_ 695 RCTA_Info_links 0;
BA_ "GenSigSendType" SG_ 695 RCTA_Info_rechts 0;
BA_ "GenSigSendType" SG_ 695 RCTA_Kritikalitaetslevel_links 0;
BA_ "GenSigSendType" SG_ 695 RCTA_Kritikalitaetslevel_rechts 0;
BA_ "GenSigSendType" SG_ 695 RCTA_Modus 0;
BA_ "GenSigSendType" SG_ 695 RCTA_Notbremsung_Anforderung 0;
BA_ "Fehlerwert" SG_ 695 RCTA_Notbremsung_Anforderung 255;
BA_ "GenSigSendType" SG_ 695 RCTA_Notbremsung_Freigabe 0;
BA_ "GenSigSendType" SG_ 695 RCTA_PaCo_BrakeIntervention 0;
BA_ "GenSigSwitchedByIgnition" SG_ 695 RCTA_PaCo_BrakeIntervention 0;
BA_ "GenSigSendType" SG_ 695 RCTA_PaCo_BrakingPossible 0;
BA_ "GenSigSwitchedByIgnition" SG_ 695 RCTA_PaCo_BrakingPossible 0;
BA_ "GenSigSendType" SG_ 695 RCTA_PaCo_MainState 0;
BA_ "GenSigSwitchedByIgnition" SG_ 695 RCTA_PaCo_MainState 0;
BA_ "Fehlerwert" SG_ 695 RCTA_PaCo_MainState 7;
BA_ "GenSigSendType" SG_ 695 RCTA_PaCo_UnavailableReason 0;
BA_ "GenSigSwitchedByIgnition" SG_ 695 RCTA_PaCo_UnavailableReason 0;
BA_ "GenSigSendType" SG_ 695 RCTA_Status 0;
BA_ "Fehlerwert" SG_ 695 RCTA_Status 3;
BA_ "GenSigSendType" SG_ 695 RCTA_Status_FoD 0;
BA_ "GenSigSwitchedByIgnition" SG_ 695 RCTA_Status_FoD 0;
BA_ "GenSigSendType" SG_ 695 RCTA_Warnton 0;
BA_REL_ "GenSigTimeoutTime" BU_SG_REL_ Airbag SG_ 2463978666 MO_Drehzahl_EM 1000;
BA_REL_ "GenSigTimeoutTime" BU_SG_REL_ Airbag SG_ 2463978666 MO_Drehzahl_EM_sek 1000;
BA_REL_ "GenSigTimeoutTime" BU_SG_REL_ Airbag SG_ 1601 TSK_Codierung 5000;
BA_REL_ "GenSigTimeoutTime" BU_SG_REL_ Airbag SG_ 2527679686 MRR_HR_ASM_Ereignis 5000;
BA_REL_ "GenSigTimeoutTime" BU_SG_REL_ Airbag SG_ 2527679686 MRR_HR_ASM_Zeitstempel_02 5000;
BA_REL_ "GenSigTimeoutTime" BU_SG_REL_ Airbag SG_ 2527679686 MRR_HR_ASM_Data_1 5000;
BA_REL_ "GenSigTimeoutTime" BU_SG_REL_ Airbag SG_ 2527679686 MRR_HR_ASM_Data_2 5000;
BA_REL_ "GenSigTimeoutTime" BU_SG_REL_ Airbag SG_ 2527679686 MRR_HR_ASM_Data_3 5000;
BA_REL_ "GenSigTimeoutTime" BU_SG_REL_ Airbag SG_ 2527679686 MRR_HR_ASM_Data_4 5000;
BA_REL_ "GenSigTimeoutTime" BU_SG_REL_ Airbag SG_ 2527679686 MRR_HR_ASM_Data_5 5000;
BA_REL_ "GenSigTimeoutTime" BU_SG_REL_ Airbag SG_ 2527679686 MRR_HR_ASM_Data_6 5000;
BA_REL_ "GenSigTimeoutTime" BU_SG_REL_ Airbag SG_ 2600468499 NM_ABS_NM_State 2000;
BA_REL_ "GenSigTimeoutTime" BU_SG_REL_ Airbag SG_ 2600468594 NM_Daempfer_NM_State 2000;
BA_REL_ "GenSigTimeoutTime" BU_SG_REL_ Airbag SG_ 2600468539 NM_EBKV_NM_State 2000;
BA_REL_ "GenSigTimeoutTime" BU_SG_REL_ Airbag SG_ 2600468496 NM_Gateway_NM_State 2000;
BA_REL_ "GenSigTimeoutTime" BU_SG_REL_ Airbag SG_ 2600468498 NM_Lenkhilfe_NM_State 2000;
BA_REL_ "GenSigTimeoutTime" BU_SG_REL_ Airbag SG_ 2589283656 ORU_Status 5000;
BA_REL_ "GenSigTimeoutTime" BU_SG_REL_ Airbag SG_ 525 PaCo_PLAIPA_TargetState 5000;
BA_REL_ "GenSigTimeoutTime" BU_SG_REL_ Airbag SG_ 2527679741 PAO_Status_01_CRC 2400;
BA_REL_ "GenSigTimeoutTime" BU_SG_REL_ Airbag SG_ 2527679741 PAO_Status_01_BZ 2400;
BA_REL_ "GenSigTimeoutTime" BU_SG_REL_ Airbag SG_ 2527679741 PAO_ON_Status 2400;
BA_REL_ "GenSigTimeoutTime" BU_SG_REL_ Airbag SG_ 2527679741 PAO_OFF_Status 2400;
BA_REL_ "GenSigTimeoutTime" BU_SG_REL_ Airbag SG_ 2331595837 PCH_Object_Class 500;
BA_REL_ "GenSigTimeoutTime" BU_SG_REL_ Airbag SG_ 2331595837 PCH_Object_vAbsX 500;
BA_REL_ "GenSigTimeoutTime" BU_SG_REL_ Airbag SG_ 2331595837 PCH_Object_vAbsY 500;
BA_REL_ "GenSigTimeoutTime" BU_SG_REL_ Airbag SG_ 2331595837 PCH_Kritikalitaetsklasse 500;
BA_REL_ "GenSigTimeoutTime" BU_SG_REL_ Airbag SG_ 2331595837 PCH_MessZeitpunkt 500;
BA_REL_ "GenSigTimeoutTime" BU_SG_REL_ Airbag SG_ 2331595837 PCH_Status 500;
BA_REL_ "GenSigTimeoutTime" BU_SG_REL_ Airbag SG_ 2331595837 PCH_TTC 500;
BA_REL_ "GenSigTimeoutTime" BU_SG_REL_ Airbag SG_ 2331595837 PCH_Object_aAbsX 500;
BA_REL_ "GenSigTimeoutTime" BU_SG_REL_ Airbag SG_ 2331595837 PCH_Object_aAbsY 500;
BA_REL_ "GenSigTimeoutTime" BU_SG_REL_ Airbag SG_ 2331595837 PCH_Object_Width 500;
BA_REL_ "GenSigTimeoutTime" BU_SG_REL_ Airbag SG_ 2331595837 PCH_Object_PosX 500;
BA_REL_ "GenSigTimeoutTime" BU_SG_REL_ Airbag SG_ 2331595837 PCH_Object_PosY 500;
BA_REL_ "GenSigTimeoutTime" BU_SG_REL_ Airbag SG_ 802 PCR_Obj_vx_rel 500;
BA_REL_ "GenSigTimeoutTime" BU_SG_REL_ Airbag SG_ 802 PCR_Obj_vy_rel 500;
BA_REL_ "GenSigTimeoutTime" BU_SG_REL_ Airbag SG_ 802 PCR_Obj_TTC 500;
BA_REL_ "GenSigTimeoutTime" BU_SG_REL_ Airbag SG_ 802 PCR_Obj_Guete 500;
BA_REL_ "GenSigTimeoutTime" BU_SG_REL_ Airbag SG_ 802 PCR_Crashwahrscheinlichkeit 500;
BA_REL_ "GenSigTimeoutTime" BU_SG_REL_ Airbag SG_ 802 PCR_Sensorstatus_02 500;
BA_REL_ "GenSigTimeoutTime" BU_SG_REL_ Airbag SG_ 796 PCS_Li_MessZeitpunkt 500;
BA_REL_ "GenSigTimeoutTime" BU_SG_REL_ Airbag SG_ 796 PCS_Li_CW 500;
BA_REL_ "GenSigTimeoutTime" BU_SG_REL_ Airbag SG_ 796 PCS_Li_CS 500;
BA_REL_ "GenSigTimeoutTime" BU_SG_REL_ Airbag SG_ 796 PCS_Li_TTC 500;
BA_REL_ "GenSigTimeoutTime" BU_SG_REL_ Airbag SG_ 796 PCS_Li_BlockID 500;
BA_REL_ "GenSigTimeoutTime" BU_SG_REL_ Airbag SG_ 796 PCS_Li_Status 500;
BA_REL_ "GenSigTimeoutTime" BU_SG_REL_ Airbag SG_ 797 PCS_Re_MessZeitpunkt 500;
BA_REL_ "GenSigTimeoutTime" BU_SG_REL_ Airbag SG_ 797 PCS_Re_CW 500;
BA_REL_ "GenSigTimeoutTime" BU_SG_REL_ Airbag SG_ 797 PCS_Re_CS 500;
BA_REL_ "GenSigTimeoutTime" BU_SG_REL_ Airbag SG_ 797 PCS_Re_TTC 500;
BA_REL_ "GenSigTimeoutTime" BU_SG_REL_ Airbag SG_ 797 PCS_Re_BlockID 500;
BA_REL_ "GenSigTimeoutTime" BU_SG_REL_ Airbag SG_ 797 PCS_Re_Status 500;
BA_REL_ "GenSigTimeoutTime" BU_SG_REL_ Airbag SG_ 2527679685 PDC_ASM_Ereignis 5000;
BA_REL_ "GenSigTimeoutTime" BU_SG_REL_ Airbag SG_ 2527679685 PDC_ASM_Zeitstempel_02 5000;
BA_REL_ "GenSigTimeoutTime" BU_SG_REL_ Airbag SG_ 2527679685 PDC_ASM_Data_1 5000;
BA_REL_ "GenSigTimeoutTime" BU_SG_REL_ Airbag SG_ 2527679685 PDC_ASM_Data_2 5000;
BA_REL_ "GenSigTimeoutTime" BU_SG_REL_ Airbag SG_ 2527679685 PDC_ASM_Data_3 5000;
BA_REL_ "GenSigTimeoutTime" BU_SG_REL_ Airbag SG_ 2527679685 PDC_ASM_Data_4 5000;
BA_REL_ "GenSigTimeoutTime" BU_SG_REL_ Airbag SG_ 2527679685 PDC_ASM_Data_5 5000;
BA_REL_ "GenSigTimeoutTime" BU_SG_REL_ Airbag SG_ 2527679685 PDC_ASM_Data_6 5000;
BA_REL_ "GenSigTimeoutTime" BU_SG_REL_ Airbag SG_ 317 QFK_stAWV 500;
BA_REL_ "GenSigTimeoutTime" BU_SG_REL_ Allrad_Haldex SG_ 1601 MO_Faktor_Momente_02 5000;
BA_REL_ "GenSigTimeoutTime" BU_SG_REL_ Allrad_Haldex SG_ 1601 MO_Kraftstoffart 5000;
BA_REL_ "GenSigTimeoutTime" BU_SG_REL_ Allrad_Haldex SG_ 1601 MO_Leistung 5000;
BA_REL_ "GenSigTimeoutTime" BU_SG_REL_ DCC_Gen3 SG_ 1601 MO_Faktor_Momente_02 5000;
BA_REL_ "GenSigTimeoutTime" BU_SG_REL_ DCC_Gen3 SG_ 2600468499 NM_ABS_NM_State 2000;
BA_REL_ "GenSigTimeoutTime" BU_SG_REL_ DCC_Gen3 SG_ 2600468501 NM_Airbag_01_NM_State 2000;
BA_REL_ "GenSigTimeoutTime" BU_SG_REL_ DCC_Gen3 SG_ 2600468539 NM_EBKV_NM_State 2000;
BA_REL_ "GenSigTimeoutTime" BU_SG_REL_ DCC_Gen3 SG_ 2600468496 NM_Gateway_NM_State 2000;
BA_REL_ "GenSigTimeoutTime" BU_SG_REL_ DCC_Gen3 SG_ 2600468498 NM_Lenkhilfe_NM_State 2000;
BA_REL_ "GenSigTimeoutTime" BU_SG_REL_ ESC_MQBW SG_ 1601 Motor_Code_01_CRC 5000;
BA_REL_ "GenSigTimeoutTime" BU_SG_REL_ ESC_MQBW SG_ 1601 Motor_Code_01_BZ 5000;
BA_REL_ "GenSigTimeoutTime" BU_SG_REL_ ESC_MQBW SG_ 1601 MO_Faktor_Momente_02 5000;
BA_REL_ "GenSigTimeoutTime" BU_SG_REL_ ESC_MQBW SG_ 1601 MO_Getriebe_Code 5000;
BA_REL_ "GenSigTimeoutTime" BU_SG_REL_ ESC_MQBW SG_ 1601 MO_StartStopp_Codiert 5000;
BA_REL_ "GenSigTimeoutTime" BU_SG_REL_ ESC_MQBW SG_ 1601 MO_Anzahl_Zyl 5000;
BA_REL_ "GenSigTimeoutTime" BU_SG_REL_ ESC_MQBW SG_ 1601 MO_Kraftstoffart 5000;
BA_REL_ "GenSigTimeoutTime" BU_SG_REL_ ESC_MQBW SG_ 1601 MO_OBD_Typ 5000;
BA_REL_ "GenSigTimeoutTime" BU_SG_REL_ ESC_MQBW SG_ 2600468501 NM_Airbag_01_NM_State 2000;
BA_REL_ "GenSigTimeoutTime" BU_SG_REL_ ESC_MQBW SG_ 2600468594 NM_Daempfer_NM_State 2000;
BA_REL_ "GenSigTimeoutTime" BU_SG_REL_ ESC_MQBW SG_ 2600468539 NM_EBKV_NM_State 2000;
BA_REL_ "GenSigTimeoutTime" BU_SG_REL_ ESC_MQBW SG_ 2600468496 NM_Gateway_NM_State 2000;
BA_REL_ "GenSigTimeoutTime" BU_SG_REL_ ESC_MQBW SG_ 2600468498 NM_Lenkhilfe_NM_State 2000;
BA_REL_ "GenSigTimeoutTime" BU_SG_REL_ ESC_MQBW SG_ 518 Parken_01_CRC 500;
BA_REL_ "GenSigTimeoutTime" BU_SG_REL_ ESC_MQBW SG_ 518 Parken_01_BZ 500;
BA_REL_ "GenSigTimeoutTime" BU_SG_REL_ ESC_MQBW SG_ 518 Parken_Verz_Anf 500;
BA_REL_ "GenSigTimeoutTime" BU_SG_REL_ ESC_MQBW SG_ 518 Parken_Warnruck_Anf 500;
BA_REL_ "GenSigTimeoutTime" BU_SG_REL_ ESC_MQBW SG_ 518 Parken_Verz_Anf_ASIL 500;
BA_REL_ "GenSigTimeoutTime" BU_SG_REL_ ESC_MQBW SG_ 518 Parken_Anforderung_HMS 500;
BA_REL_ "GenSigTimeoutTime" BU_SG_REL_ ESC_MQBW SG_ 518 Parken_Notstopp_Anf 500;
BA_REL_ "GenSigTimeoutTime" BU_SG_REL_ ESC_MQBW SG_ 317 QFK_01_CRC 500;
BA_REL_ "GenSigTimeoutTime" BU_SG_REL_ ESC_MQBW SG_ 317 QFK_01_BZ 500;
BA_REL_ "GenSigTimeoutTime" BU_SG_REL_ ESC_MQBW SG_ 317 QFK_01_Sendestatus 500;
BA_REL_ "GenSigTimeoutTime" BU_SG_REL_ ESC_MQBW SG_ 317 QFK_stEingriffBr 500;
BA_REL_ "GenSigTimeoutTime" BU_SG_REL_ ESC_MQBW SG_ 317 QFK_DynBegr_aktiv 500;
BA_REL_ "GenSigTimeoutTime" BU_SG_REL_ ESC_MQBW SG_ 317 QFK_Anf_Giermomoffset_VZ 500;
BA_REL_ "GenSigTimeoutTime" BU_SG_REL_ ESC_MQBW SG_ 317 QFK_Status 500;
BA_REL_ "GenSigTimeoutTime" BU_SG_REL_ ESC_MQBW SG_ 317 QFK_stDSR 500;
BA_REL_ "GenSigTimeoutTime" BU_SG_REL_ ESC_MQBW SG_ 317 QFK_IstKraft_VZ 500;
BA_REL_ "GenSigTimeoutTime" BU_SG_REL_ ESC_MQBW SG_ 317 QFK_KruemmIst 500;
BA_REL_ "GenSigTimeoutTime" BU_SG_REL_ ESC_MQBW SG_ 317 QFK_KruemmIst_VZ 500;
BA_REL_ "GenSigTimeoutTime" BU_SG_REL_ ESC_MQBW SG_ 317 QFK_IstKraftNiveau 500;
BA_REL_ "GenSigTimeoutTime" BU_SG_REL_ ESC_MQBW SG_ 317 QFK_IstKraftNiveau_VZ 500;
BA_REL_ "GenSigTimeoutTime" BU_SG_REL_ ESC_MQBW SG_ 317 QFK_Anf_Giermomoffset 500;
BA_REL_ "GenSigTimeoutTime" BU_SG_REL_ ESC_MQBW SG_ 317 QFK_IstKraft 500;
BA_REL_ "GenSigTimeoutTime" BU_SG_REL_ ESC_MQBW SG_ 695 RCTA_Anforderung_HMS 500;
BA_REL_ "GenSigTimeoutTime" BU_SG_REL_ ESC_MQBW SG_ 695 RCTA_Notbremsung_Freigabe 500;
BA_REL_ "GenSigTimeoutTime" BU_SG_REL_ ESC_MQBW SG_ 695 RCTA_Notbremsung_Anforderung 500;
BA_REL_ "GenSigTimeoutTime" BU_SG_REL_ Gateway_Max SG_ 2600468499 NM_ESP_CBV_AWB 2000;
BA_REL_ "GenSigTimeoutTime" BU_SG_REL_ Gateway_Max SG_ 2600468499 NM_ESP_CBV_CRI 2000;
BA_REL_ "GenSigTimeoutTime" BU_SG_REL_ Gateway_Max SG_ 2600468499 NM_ABS_Car_Wakeup 2000;
BA_REL_ "GenSigTimeoutTime" BU_SG_REL_ Gateway_Max SG_ 2600468499 NM_ABS_CAB_V14 2000;
BA_REL_ "GenSigTimeoutTime" BU_SG_REL_ Gateway_Max SG_ 2600468501 NM_Airbag_01_CBV_AWB 2000;
BA_REL_ "GenSigTimeoutTime" BU_SG_REL_ Gateway_Max SG_ 2600468501 NM_Airbag_01_CBV_CRI 2000;
BA_REL_ "GenSigTimeoutTime" BU_SG_REL_ Gateway_Max SG_ 2600468501 NM_Airbag_01_Car_Wakeup 2000;
BA_REL_ "GenSigTimeoutTime" BU_SG_REL_ Gateway_Max SG_ 2600468501 NM_Airbag_01_CAB_V14 2000;
BA_REL_ "GenSigTimeoutTime" BU_SG_REL_ Gateway_Max SG_ 2600468594 NM_Daempfer_CBV_AWB 2000;
BA_REL_ "GenSigTimeoutTime" BU_SG_REL_ Gateway_Max SG_ 2600468594 NM_Daempfer_CBV_CRI 2000;
BA_REL_ "GenSigTimeoutTime" BU_SG_REL_ Gateway_Max SG_ 2600468594 NM_Daempfer_Car_Wakeup 2000;
BA_REL_ "GenSigTimeoutTime" BU_SG_REL_ Gateway_Max SG_ 2600468594 NM_Daempfer_CAB_V14 2000;
BA_REL_ "GenSigTimeoutTime" BU_SG_REL_ Gateway_Max SG_ 2600468539 NM_EBKV_CBV_AWB 2000;
BA_REL_ "GenSigTimeoutTime" BU_SG_REL_ Gateway_Max SG_ 2600468539 NM_EBKV_CBV_CRI 2000;
BA_REL_ "GenSigTimeoutTime" BU_SG_REL_ Gateway_Max SG_ 2600468539 NM_EBKV_Car_Wakeup 2000;
BA_REL_ "GenSigTimeoutTime" BU_SG_REL_ Gateway_Max SG_ 2600468539 NM_EBKV_CAB_V14 2000;
BA_REL_ "GenSigTimeoutTime" BU_SG_REL_ Gateway_Max SG_ 2600468498 NM_EPS_CBV_AWB 2000;
BA_REL_ "GenSigTimeoutTime" BU_SG_REL_ Gateway_Max SG_ 2600468498 NM_EPS_CBV_CRI 2000;
BA_REL_ "GenSigTimeoutTime" BU_SG_REL_ Gateway_Max SG_ 2600468498 NM_Lenkhilfe_Car_Wakeup 2000;
BA_REL_ "GenSigTimeoutTime" BU_SG_REL_ Gateway_Max SG_ 2600468498 NM_Lenkhilfe_CAB_V14 2000;
BA_REL_ "GenSigTimeoutTime" BU_SG_REL_ Gateway_Max SG_ 317 QFK_Status 500;
BA_REL_ "GenSigTimeoutTime" BU_SG_REL_ Lenkhilfe_REPS SG_ 1601 MO_Faktor_Momente_02 5000;
BA_REL_ "GenSigTimeoutTime" BU_SG_REL_ Lenkhilfe_REPS SG_ 2600468499 NM_ABS_NM_State 2000;
BA_REL_ "GenSigTimeoutTime" BU_SG_REL_ Lenkhilfe_REPS SG_ 2600468501 NM_Airbag_01_NM_State 2000;
BA_REL_ "GenSigTimeoutTime" BU_SG_REL_ Lenkhilfe_REPS SG_ 2600468594 NM_Daempfer_NM_State 2000;
BA_REL_ "GenSigTimeoutTime" BU_SG_REL_ Lenkhilfe_REPS SG_ 2600468539 NM_EBKV_NM_State 2000;
BA_REL_ "GenSigTimeoutTime" BU_SG_REL_ Lenkhilfe_REPS SG_ 2600468496 NM_Gateway_NM_State 2000;
BA_REL_ "GenSigTimeoutTime" BU_SG_REL_ Lenkhilfe_REPS SG_ 2589283656 ORU_Status 5000;
BA_REL_ "GenSigTimeoutTime" BU_SG_REL_ Lenkhilfe_REPS SG_ 770 PLA_QFK_AnfStat 5000;
BA_REL_ "GenSigTimeoutTime" BU_SG_REL_ Lenkhilfe_REPS SG_ 770 PLA_QFK_Spuerb 5000;
BA_REL_ "GenSigTimeoutTime" BU_SG_REL_ Lenkhilfe_REPS SG_ 770 PLA_QFK_KruemmSoll 5000;
BA_REL_ "GenSigTimeoutTime" BU_SG_REL_ Lenkhilfe_REPS SG_ 770 PLA_QFK_KruemmSoll_VZ 5000;
BA_REL_ "GenSigTimeoutTime" BU_SG_REL_ Lenkhilfe_REPS SG_ 770 PLA_QFK_Signal1 5000;
BA_REL_ "GenSigTimeoutTime" BU_SG_REL_ Lenkhilfe_REPS SG_ 770 PLA_QFK_Art1 5000;
BA_REL_ "GenSigTimeoutTime" BU_SG_REL_ Lenkhilfe_REPS SG_ 770 PLA_QFK_Art2 5000;
BA_REL_ "GenSigTimeoutTime" BU_SG_REL_ Lenkhilfe_REPS SG_ 770 PLA_QFK_Signal2 5000;
BA_REL_ "GenSigTimeoutTime" BU_SG_REL_ Lenkhilfe_REPS SG_ 770 PLA_05_Sendestatus 5000;
BA_REL_ "GenSigTimeoutTime" BU_SG_REL_ Lenkhilfe_REPS SG_ 770 PLA_QFK_KrSoll_VZ 5000;
BA_REL_ "GenSigTimeoutTime" BU_SG_REL_ Lenkhilfe_REPS SG_ 770 PLA_QFK_KrSoll 5000;
VAL_ 2463978666 MO_EM1_Min_Spannung_Lim 1022 "Init" ;
VAL_ 2463978666 MO_EM1_Max_Spannung_Lim 1022 "Init" ;
VAL_ 2463978666 MO_EM1_Min_Leistung_Gesamt 8190 "Init" ;
VAL_ 2463978666 MO_EM1_Max_Leistung_Gesamt 8190 "Init" ;
VAL_ 2463978666 MO_EM2_Min_Leistung_Gesamt 8190 "Init" ;
VAL_ 2463978666 MO_EM2_Max_Leistung_Gesamt 8190 "Init" ;
VAL_ 2463978666 MO_EM2_Min_Spannung_Lim 1022 "Init" ;
VAL_ 2463978666 MO_EM2_Max_Spannung_Lim 1022 "Init" ;
VAL_ 2463978666 MO_EM1_Generator_Leistung 254 "Init" 255 "Fehler" ;
VAL_ 2463978666 MO_EM2_Generator_Leistung 254 "Init" 255 "Fehler" ;
VAL_ 2463978666 MO_Verbrauch_EM_Ges_Ueberlauf 0 "kein_Ueberlauf" 1 "Ueberlauf_Verbrauchssignal" ;
VAL_ 2463978666 MO_Rekuperation_EM_Ges_Ueberlauf 0 "kein_Ueberlauf" 1 "Ueberlauf_Reku_Leistungssignal" ;
VAL_ 2463978666 MO_Drehzahl_EM 8190 "Init_nichtverbaut" 8191 "Fehler" ;
VAL_ 2463978666 MO_Uebersetzung_EM 0 "keine_sichere_Uebertragung" 1022 "Init_nichtverbaut" 1023 "Fehler" ;
VAL_ 2463978666 MO_Drehzahl_EM_sek 8190 "Init_nichtverbaut" 8191 "Fehler" ;
VAL_ 2463978666 MO_Uebersetzung_EM_sek 0 "keine_sichere_Uebertragung" 1022 "Init" 1023 "Fehler" ;
VAL_ 2463978666 MO_TNW_Min_Spannung_Lim 1022 "Init" ;
VAL_ 2463978666 MO_TNW_Max_Spannung_Lim 1022 "Init" ;
VAL_ 1601 MO_Faktor_Momente_02 0 "nicht_belegt" ;
VAL_ 1601 MO_Hybridfahrzeug 0 "kein_Hybridfahrzeug" 1 "Mild_Hybrid" 2 "Full_Hybrid" 3 "PlugIn_Hybrid" ;
VAL_ 1601 MO_Getriebe_Code 0 "Init" 2 "DL501" 3 "DL800" 4 "VL381" 5 "DL382_Front" 6 "DL382_Allrad" 7 "DL702" 8 "AL552_Allrad" 9 "AL552_Front" 10 "AL651" 11 "AL551__AL951__AL1000_8A" 12 "PDK_PAG" 13 "AL551_Hybrid" 15 "Handschalter_konventionell" 16 "AQ250_160" 17 "AQ450" 18 "DQ200" 19 "DQ250" 20 "DQ500" 21 "SQ100" 22 "SQ200" 23 "DQ400E" 24 "DQ381" 25 "AL550" 26 "AQ300" 31 "DL800E" 32 "Single_Gear__ohne_GSG_WH_am_MSG" 33 "EQ550_2P" ;
VAL_ 1601 MO_StartStopp_Codiert 0 "Start_Stopp_nicht_verbaut" 1 "Start_Stopp_verbaut" ;
VAL_ 1601 MO_Anzeige_StSt_gueltig 0 "MO_Text_Motorstart_gueltig" 1 "Signale_MO_Anzeige_StSt_gueltig" ;
VAL_ 1601 MO_Anzahl_Zyl 0 "kein_Zylinder" 1 "1_Zylinder" 2 "2_Zylinder" 3 "3_Zylinder" 4 "4_Zylinder" 5 "5_Zylinder" 6 "6_Zylinder" 7 "7_Zylinder" 8 "8_Zylinder" 9 "9_Zylinder" 10 "10_Zylinder" 11 "11_Zylinder" 12 "12_Zylinder" 13 "15_Zylinder" 14 "16_Zylinder" 15 "18_Zylinder" ;
VAL_ 1601 MO_Kraftstoffart 0 "Diesel" 1 "Benzin_inkl_E25_E85" 2 "CNG" 3 "LPG" 4 "Wasserstoff" 5 "E100_Ethanol" 15 "kein_Verbrennungskraftstoff" ;
VAL_ 1601 MO_Ansaugsystem 0 "Turbo" 1 "Sauger" ;
VAL_ 1601 MO_OBD_Typ 0 "NoOBD_RdW" 1 "EOBD" 2 "US_OBD" 3 "reserviert" ;
VAL_ 1601 MO_DPF_verbaut 0 "kein_DPF_verbaut" 1 "DPF_verbaut" ;
VAL_ 1601 TSK_Codierung 0 "kein_Fahrgeschwindigkeitsregler" 1 "GRA" 2 "GRA_Plus" 3 "Basis_ACC" 4 "ACC_Follow_to_Stop" 5 "ACC_Stop_and_Go" 7 "Codierung_in_Plausibilisierungsphase" ;
VAL_ 2527679686 MRR_HR_ASM_Ereignis 0 "No_Event" 255 "ASM_Trigger" ;
VAL_ 2527679686 MRR_HR_ASM_Zeitstempel_02 255 "Init" ;
VAL_ 2600468499 NM_ESP_CBV_AWB 0 "Passiver_WakeUp" 1 "Aktiver_WakeUp" ;
VAL_ 2600468499 NM_ESP_CBV_CRI 0 "Standard_Layout" 1 "TNB_Layout" ;
VAL_ 2600468499 NM_ABS_NM_State 0 "Init" 1 "NM_RM_aus_BSM" 2 "NM_RM_aus_PBSM" 4 "NM_NO_aus_RM" 8 "NM_NO_aus_RS" 16 "reserved" 32 "reserved" ;
VAL_ 2600468499 NM_ABS_Car_Wakeup 0 "Inaktiv" 1 "Car_Wakeup" ;
VAL_ 2600468499 NM_ABS_UDS_CC 0 "Inaktiv" 1 "CC_aktiv" ;
VAL_ 2600468499 NM_ABS_NM_aktiv_KL15 0 "Inaktiv" 1 "KL15_EIN" ;
VAL_ 2600468499 NM_ABS_NM_aktiv_Diagnose 0 "Init" 1 "Diagnose_aktiv" ;
VAL_ 2600468499 NM_ABS_NM_aktiv_Tmin 0 "Inaktiv" 1 "Mindestaktivzeit" ;
VAL_ 2600468499 NM_ABS_NM_aktiv_v_gr_0 1 "kein_Stillstand_aller_Raeder_erkannt" ;
VAL_ 2600468499 NM_ESP_NM_aktiv_Anzeige_EPB 1 "Anzeige_EPB_Lampe" ;
VAL_ 2600468499 NM_ESP_NM_aktiv_Kuehlernachlauf 0 "inaktiv" 1 "Anforderung_Kuehlernachlauf" ;
VAL_ 2600468499 NM_ABS_NM_aktiv_EPB_Nachspannen 0 "Inaktiv" 1 "EPB_Nachspannen" ;
VAL_ 2600468499 NM_ABS_NM_aktiv_Bewarnung_BKV 0 "Inaktiv" 1 "Anzeige_Nachlauf_BKV" ;
VAL_ 2600468499 NM_ABS_CAB_V14 0 "Init" 1 "CAB_01_Antrieb" 2 "CAB_02_Hybrid_Laden" 4 "CAB_03_Fahrwerk" 8 "CAB_04_Fahrerassistenz" 16 "CAB_05_Komfort" 32 "CAB_06_Anzeige" 64 "CAB_07_Connect" 128 "CAB_08_MIB" 256 "CAB_09_Standheizung" 1024 "CAB_11_VLAN_Fahrerassistenz" 2048 "CAB_12_VLAN_Komfort" 4096 "CAB_13_VLAN_Connect" 8192 "CAB_14_VLAN_Infotainment" 16384 "CAB_15_Laden" 32768 "CAB_16_Licht" ;
VAL_ 2600468501 NM_Airbag_01_CBV_AWB 0 "Passiver_WakeUp" 1 "Aktiver_WakeUp" ;
VAL_ 2600468501 NM_Airbag_01_CBV_CRI 0 "NM_ohne_Clusteranforderungen" 1 "NM_mit_Clusteranforderungen" ;
VAL_ 2600468501 NM_Airbag_01_NM_State 0 "Init" 1 "NM_RM_aus_BSM" 2 "NM_RM_aus_PBSM" 4 "NM_NO_aus_RM" 8 "NM_NO_aus_RS" 16 "reserved" 32 "reserved" ;
VAL_ 2600468501 NM_Airbag_01_Car_Wakeup 0 "Inaktiv" 1 "Car_Wakeup" ;
VAL_ 2600468501 NM_Airbag_01_UDS_CC 0 "Inaktiv" 1 "CC_aktiv" ;
VAL_ 2600468501 NM_Airbag_01_NM_aktiv_KL15 0 "Inaktiv" 1 "KL15_EIN" ;
VAL_ 2600468501 NM_Airbag_01_NM_aktiv_Diagnose 0 "Init" 1 "Diagnose_aktiv" ;
VAL_ 2600468501 NM_Airbag_01_NM_aktiv_Tmin 0 "Inaktiv" 1 "Mindestaktivzeit" ;
VAL_ 2600468501 NM_Airbag_01_CAB_V14 0 "Init" 1 "CAB_01_Antrieb" 2 "CAB_02_Hybrid_Laden" 4 "CAB_03_Fahrwerk" 8 "CAB_04_Fahrerassistenz" 16 "CAB_05_Komfort" 32 "CAB_06_Anzeige" 64 "CAB_07_Connect" 128 "CAB_08_MIB" 256 "CAB_09_Standheizung" 1024 "CAB_11_VLAN_Fahrerassistenz" 2048 "CAB_12_VLAN_Komfort" 4096 "CAB_13_VLAN_Connect" 8192 "CAB_14_VLAN_Infotainment" 16384 "CAB_15_Laden" 32768 "CAB_16_Licht" ;
VAL_ 2600468594 NM_Daempfer_CBV_AWB 0 "Passiver_WakeUp" 1 "Aktiver_WakeUp" ;
VAL_ 2600468594 NM_Daempfer_CBV_CRI 0 "Standard_Layout" 1 "TNB_Layout" ;
VAL_ 2600468594 NM_Daempfer_NM_State 0 "Init" 1 "NM_RM_aus_BSM" 2 "NM_RM_aus_PBSM" 4 "NM_NO_aus_RM" 8 "NM_NO_aus_RS" ;
VAL_ 2600468594 NM_Daempfer_Car_Wakeup 0 "Inaktiv" 1 "Car_Wakeup" ;
VAL_ 2600468594 NM_Daempfer_UDS_CC 0 "CC_inaktiv" 1 "CC_aktiv" ;
VAL_ 2600468594 NM_Daempfer_NM_aktiv_KL15 0 "Inaktiv" 1 "KL15_EIN" ;
VAL_ 2600468594 NM_Daempfer_NM_aktiv_Diagnose 0 "Inaktiv" 1 "Diagnose_aktiv" ;
VAL_ 2600468594 NM_Daempfer_NM_aktiv_Tmin 0 "Inaktiv" 1 "Mindestaktivzeit" ;
VAL_ 2600468594 NM_Daempfer_CAB_V14 0 "Init" 1 "CAB_01_Antrieb" 2 "CAB_02_Hybrid_Laden" 4 "CAB_03_Fahrwerk" 8 "CAB_04_Fahrerassistenz" 16 "CAB_05_Komfort" 32 "CAB_06_Anzeige" 64 "CAB_07_Connect" 128 "CAB_08_MIB" 256 "CAB_09_Standheizung" 1024 "CAB_11_VLAN_Fahrerassistenz" 2048 "CAB_12_VLAN_Komfort" 4096 "CAB_13_VLAN_Connect" 8192 "CAB_14_VLAN_Infotainment" 16384 "CAB_15_Laden" 32768 "CAB_16_Licht" ;
VAL_ 2600468539 NM_EBKV_CBV_AWB 0 "Passiver_WakeUp" 1 "Aktiver_WakeUp" ;
VAL_ 2600468539 NM_EBKV_CBV_CRI 0 "Standard_Layout" 1 "TNB_Layout" ;
VAL_ 2600468539 NM_EBKV_NM_State 1 "NM_RM_aus_BSM" 2 "NM_RM_aus_PBSM" 4 "NM_NO_aus_RM" 8 "NM_NO_aus_RS" 16 "NM_RM_aus_RS" 32 "NM_RM_aus_NO" ;
VAL_ 2600468539 NM_EBKV_Car_Wakeup 0 "Inaktiv" 1 "Car_Wakeup" ;
VAL_ 2600468539 NM_EBKV_UDS_CC 0 "Init" 1 "CC_aktiv" ;
VAL_ 2600468539 NM_EBKV_NM_aktiv_KL15 0 "Inaktiv" 1 "KL15_EIN" ;
VAL_ 2600468539 NM_EBKV_NM_aktiv_Diagnose 0 "Init" 1 "Diagnose_aktiv" ;
VAL_ 2600468539 NM_EBKV_NM_aktiv_Tmin 0 "Inaktiv" 1 "Mindestaktivzeit" ;
VAL_ 2600468539 NM_EBKV_NM_aktiv_v_gr_0 1 "kein_v_gleich_0_erkannt" ;
VAL_ 2600468539 NM_EBKV_NM_aktiv_Bewarnung 1 "Bewarnung_aktiv" ;
VAL_ 2600468539 NM_EBKV_CAB_V14 0 "Init" 1 "CAB_01_Antrieb" 2 "CAB_02_Hybrid_Laden" 4 "CAB_03_Fahrwerk" 8 "CAB_04_Fahrerassistenz" 16 "CAB_05_Komfort" 32 "CAB_06_Anzeige" 64 "CAB_07_Connect" 128 "CAB_08_MIB" 256 "CAB_09_Standheizung" 1024 "CAB_11_VLAN_Fahrerassistenz" 2048 "CAB_12_VLAN_Komfort" 4096 "CAB_13_VLAN_Connect" 8192 "CAB_14_VLAN_Infotainment" 16384 "CAB_15_Laden" 32768 "CAB_16_Licht" ;
VAL_ 2600468496 NM_Gateway_CBV_AWB 0 "Passiver_WakeUp" 1 "Aktiver_WakeUp" ;
VAL_ 2600468496 NM_Gateway_CBV_CRI 0 "NM_ohne_Clusteranforderungen" 1 "NM_mit_Clusteranforderungen" ;
VAL_ 2600468496 NM_Gateway_NM_State 0 "Init" 1 "NM_RM_aus_BSM" 2 "NM_RM_aus_PBSM" 4 "NM_NO_aus_RM" 8 "NM_NO_aus_RS" 16 "reserved" 32 "reserved" ;
VAL_ 2600468496 NM_Gateway_Car_Wakeup 0 "Inaktiv" 1 "Car_Wakeup" ;
VAL_ 2600468496 NM_Gateway_UDS_CC 0 "Inaktiv" 1 "CC_aktiv" ;
VAL_ 2600468496 NM_Gateway_NM_aktiv_KL15 0 "Inaktiv" 1 "KL15_EIN" ;
VAL_ 2600468496 NM_Gateway_NM_aktiv_Diagnose 0 "Init" 1 "Diagnose_aktiv" ;
VAL_ 2600468496 NM_Gateway_NM_aktiv_Tmin 0 "Inaktiv" 1 "Mindestaktivzeit" ;
VAL_ 2600468496 NM_Gateway_NM_aktiv_CWU 0 "kein_CWU_gesetzt" 1 "CWU_gesetzt" ;
VAL_ 2600468496 NM_Gateway_NM_aktiv_FC 0 "kein_FC_gesetzt" 1 "FC_gesetzt" ;
VAL_ 2600468496 NM_Gateway_NM_aktiv_EM 0 "inaktiv" 1 "Nachlauf_aufgrund_Energiemanagement" ;
VAL_ 2600468496 NM_Gateway_NM_aktiv_Buskopplung 0 "inaktiv" 1 "Nachlauf_aufgrund_Buskopplung" ;
VAL_ 2600468496 NM_Gateway_CAB_V14 0 "Init" 1 "CAB_01_Antrieb" 2 "CAB_02_Hybrid_Laden" 4 "CAB_03_Fahrwerk" 8 "CAB_04_Fahrerassistenz" 16 "CAB_05_Komfort" 32 "CAB_06_Anzeige" 64 "CAB_07_Connect" 128 "CAB_08_MIB" 256 "CAB_09_Standheizung" 1024 "CAB_11_VLAN_Fahrerassistenz" 2048 "CAB_12_VLAN_Komfort" 4096 "CAB_13_VLAN_Connect" 8192 "CAB_14_VLAN_Infotainment" 16384 "CAB_15_Laden" 32768 "CAB_16_Licht" ;
VAL_ 2600468498 NM_EPS_CBV_AWB 0 "Passiver_WakeUp" 1 "Aktiver_WakeUp" ;
VAL_ 2600468498 NM_EPS_CBV_CRI 0 "Standard_Layout" 1 "TNB_Layout" ;
VAL_ 2600468498 NM_Lenkhilfe_NM_State 0 "Init" 1 "NM_RM_aus_BSM" 2 "NM_RM_aus_PBSM" 4 "NM_NO_aus_RM" 8 "NM_NO_aus_RS" 16 "reserved" 32 "reserved" ;
VAL_ 2600468498 NM_Lenkhilfe_Car_Wakeup 0 "Inaktiv" 1 "Car_Wakeup" ;
VAL_ 2600468498 NM_Lenkhilfe_UDS_CC 0 "Inaktiv" 1 "CC_aktiv" ;
VAL_ 2600468498 NM_Lenkhilfe_NM_aktiv_KL15 0 "Inaktiv" 1 "KL15_EIN" ;
VAL_ 2600468498 NM_Lenkhilfe_NM_aktiv_Diagnose 0 "Init" 1 "Diagnose_aktiv" ;
VAL_ 2600468498 NM_Lenkhilfe_NM_aktiv_Tmin 0 "Inaktiv" 1 "Mindestaktivzeit" ;
VAL_ 2600468498 NM_Lenkhilfe_NM_aktiv_v_gr_7 0 "Inaktiv" 1 "v_groesser_7" ;
VAL_ 2600468498 NM_Lenkhilfe_NM_aktiv_DZ_gr_300 0 "Inaktiv" 1 "DZ_groesser_300" ;
VAL_ 2600468498 NM_Lenkhilfe_NM_aktiv_Handlenkmo 0 "Inaktiv" 1 "Handlenkmoment" ;
VAL_ 2600468498 NM_Lenkhilfe_NM_aktiv_Post_Run 0 "Inaktiv" 1 "Post_Run" ;
VAL_ 2600468498 NM_Lenkhilfe_NM_aktiv_Fahrbereit 0 "keine_Fahrbereitschaft_erkannt" 1 "Fahrbereitsschaft_erkannt" ;
VAL_ 2600468498 NM_Lenkhilfe_CAB_V14 0 "Init" 1 "CAB_01_Antrieb" 2 "CAB_02_Hybrid_Laden" 4 "CAB_03_Fahrwerk" 8 "CAB_04_Fahrerassistenz" 16 "CAB_05_Komfort" 32 "CAB_06_Anzeige" 64 "CAB_07_Connect" 128 "CAB_08_MIB" 256 "CAB_09_Standheizung" 1024 "CAB_11_VLAN_Fahrerassistenz" 2048 "CAB_12_VLAN_Komfort" 4096 "CAB_13_VLAN_Connect" 8192 "CAB_14_VLAN_Infotainment" 16384 "CAB_15_Laden" 32768 "CAB_16_Licht" ;
VAL_ 2589283656 ORU_Warnung 0 "keine_Anzeige" 1 "Update_unvollstaendig_Prio1" 2 "Update_fehlgeschlagen_Prio1" 3 "reserviert" ;
VAL_ 2589283656 ORU_Status 0 "IDLE" 1 "PENDING" 2 "PREPARATION" 3 "PREPARATION_HV" 4 "RUNNING" 5 "RUNNING_HV" 6 "PENDING_NOTREADY" 7 "FAILURE_POWERTRAIN_DISABLED" ;
VAL_ 525 PaCo_01_Sendestatus 0 "PaCo_01_im_langsamen_Zyklus" 1 "PaCo_01_im_schnellen_Zyklus" ;
VAL_ 525 PaCo_APS_TargetState 0 "Inactive" 1 "Active" 2 "Active_ReducedRange" 3 "Active_Muted" ;
VAL_ 525 PaCo_APSOPS_DetectionFront 0 "Detection_Inactive" 1 "Detection_Active" ;
VAL_ 525 PaCo_APSOPS_DetectionRear 0 "Detection_Inactive" 1 "Detection_Active" ;
VAL_ 525 PaCo_APSOPS_LED 0 "LED_Inactive" 1 "LED_Active" 2 "LED_Flashing" 3 "Error" ;
VAL_ 525 PaCo_OPS_TargetState 0 "OPS_Inactive" 1 "OPS_Active" 2 "OPS_Active_Muted" ;
VAL_ 525 PaCo_OPS_DrivingTube 0 "Inactive" 1 "Active" ;
VAL_ 525 PaCo_PLAIPA_InterventionStart 0 "Inactive" 1 "Active" ;
VAL_ 525 PaCo_PLAIPA_PLE 0 "Inactive" 1 "Active" ;
VAL_ 525 PaCo_PLAIPA_LED 0 "LED_Inactive" 1 "LED_Active" 2 "LED_Flashing" 3 "Error" ;
VAL_ 525 PaCo_PLAIPA_TargetState 0 "Inactive" 1 "Active_Visible" 2 "DeactBy_NoReason" 3 "DeactBy_Speed" 4 "DeactBy_PLAIPAButton" 5 "DeactBy_PGear" 6 "DeactBy_RGear" 7 "DeactBy_APSOPSoff" 8 "DeactBy_HeadunitVisualOff" 9 "DeactBy_End_Remote" 10 "Active_Remote" 11 "Active_Garage" ;
VAL_ 525 PaCo_PLAIPA_SwitchParkSlot 0 "NotToggle_ToNextParkingSlot" 1 "Toggle_ToNextParkingSlot" ;
VAL_ 525 PaCo_RBFMA_InterventionStrategy 0 "No_Intervention" 1 "Only_Braking" 2 "Only_Steering" 3 "Braking_And_Steering" ;
VAL_ 525 PaCo_VPS_TargetView 0 "NoView" 1 "RearView" 2 "FrontView" 3 "SV_Left" 4 "SV_Right" 5 "SV_Both" 6 "BirdView_2D" 7 "BirdView_3D" 8 "VirtualView" ;
VAL_ 525 PaCo_VPS_TargetMode 0 "NoMode" 1 "Parking_Manual" 2 "Parking_Automatic" 3 "Crossing" 4 "BumperFocus" 5 "TrailerAssist_Manual" 6 "SV_Focus_Front" 7 "SV_Focus_Rear" 8 "SV_Focus_All" 9 "Legal" 10 "TrailerAssist_AAA" 11 "TrailerAssist_ARA" 12 "Smartphone" 13 "VirtualView" 14 "BumperFocus_AWC" ;
VAL_ 525 PaCo_VPS_LED 0 "LED_Inactive" 1 "LED_Active" 2 "LED_Flashing" 3 "Error" ;
VAL_ 525 PaCo_VPS_TargetState 0 "Inactive" 1 "Active" 2 "data_recording" ;
VAL_ 525 PaCo_VPS_TargetBirdview 0 "NoBirdview" 1 "Birdview_2D" 2 "Birdview_3D" 3 "Birdview_Autoakt" 4 "OPS_only" 5 "TPA_Trajectory" ;
VAL_ 525 PaCo_VPS_DarkenVideo 0 "Inactive" 1 "Active" ;
VAL_ 525 PaCo_VPS_PLE 0 "Inactive" 1 "Active" ;
VAL_ 525 PaCo_ARA_TargetState 0 "Inactive" 1 "Active" ;
VAL_ 525 PaCo_RCTA_InterventionStrategy 0 "NoIntervention" 1 "Braking" ;
VAL_ 525 PaCo_MainState 0 "Init" 1 "InOperation_NoError" 7 "Fehler" ;
VAL_ 525 PaCo_RCTA_Warning 0 "RCTA_Inactive" 1 "RCTA_Active" 2 "RCTA_Active_Muted" 3 "RCTA_Off" ;
VAL_ 525 PaCo_APS_AudioLowering 0 "Inactive" 1 "Active" ;
VAL_ 525 PaCo_VPS_TargetRVCscreen 0 "noScreen" 1 "Fullscreen" 2 "Splitscreen_SidebySide" ;
VAL_ 525 PaCo_AAA_Intervention 0 "No_Intervention" 1 "Intervention" ;
VAL_ 525 PaCo_AAA_TargetState 0 "Inactive" 1 "Active" 2 "remoteActive" ;
VAL_ 525 PaCo_TPA_TargetState 0 "Inactive" 1 "Active_Visible" 2 "DeactBy_NoReason" 8 "DeactBy_HeadunitVisualOff" ;
VAL_ 525 PaCo_DiETa_LED 0 "LED_Inactive" 1 "LED_Active" 2 "LED_Flashing" 3 "Error" ;
VAL_ 525 PaCo_VPS_TargetCarOverlay 0 "noCarOverlay" 1 "normalCarOverlay" 2 "transparentCarOverlay" ;
VAL_ 525 PaCo_VPS_TargetBowl 0 "NoBowl" 1 "Preset_1" 2 "Preset_2" 3 "Preset_3" 4 "Preset_4" 5 "Preset_5" 6 "Preset_6" 7 "Preset_7" 8 "Preset_8" 9 "Preset_9" 10 "Modified" 11 "Preset_AWC" 12 "Preset_IPA" 13 "Preset_ParkingFront" 14 "Preset_ParkingRear" 15 "Preset_RPA" 16 "Preset_CarWash" ;
VAL_ 525 PaCo_VPS_TargetGraphicOverlay 0 "NoGraphic" 1 "IPA" 2 "ARA" 3 "AAA" 4 "TrailerAssist" 5 "AR" 6 "AWC" 7 "Parkbox" 8 "CarWash" 9 "RPA" 10 "TPA_Training" 11 "TPA_AutomatedDriving" 12 "TPA_Remote" 13 "legal" ;
VAL_ 525 PaCo_RAB_TargetState 0 "nicht_verfuegbar" 1 "im_Hintergrund" 2 "in_Anzeige" 3 "in_Regelung" ;
VAL_ 525 PaCo_AEBPR_InterventionStrategy 0 "Inactive" 1 "Active" ;
VAL_ 525 PaCo_AEBPR_ImplementationRBFMA 0 "RBFMA_not_implemented" 1 "RBFMA_implemented" ;
VAL_ 525 PaCo_RBFMA_ImplementationAEBPR 0 "AEBPR_not_implemented" 1 "AEBPR_implemented" ;
VAL_ 525 PaCo_ARA_InterventionStart 0 "Inactive" 1 "Active" ;
VAL_ 2527679741 PAO_ON_Status 0 "LED_aus" 1 "LED_an" 2 "LED_blinkt" 3 "LED_defekt" ;
VAL_ 2527679741 PAO_OFF_Status 0 "LED_aus" 1 "LED_an" 2 "LED_blinkt" 3 "LED_defekt" ;
VAL_ 518 Parken_BKD_Anf 14 "Neutralwert" 15 "Fehler" ;
VAL_ 518 Parken_Verz_Anf 126 "Neutralwert" 127 "reserved" ;
VAL_ 518 Parken_Prefill_Anf 0 "keine_Anforderung" 1 "Prefill_Anforderung" ;
VAL_ 518 Parken_Warnruck_Anf 0 "Keine_Anforderung" 1 "schwacher_Warnruck" 2 "mittlerer_Warnruck" 3 "starker_Warnruck" ;
VAL_ 518 Parken_Verz_Anf_ASIL 0 "ASIL_QM" 1 "ASIL_A" 2 "ASIL_B" 3 "ASIL_C" ;
VAL_ 518 Parken_Warnruckeln_Anf 0 "keine_Anforderung" 1 "schwaches_Warnruckeln" 2 "mittleres_Warnruckeln" 3 "starkes_Warnruckeln" ;
VAL_ 518 Parken_beibehalten 0 "Parken_nicht_beibehalten" 1 "Parken_beibehalten" 2 "Init" 3 "Fehler" ;
VAL_ 518 Parken_Anforderung_HMS 0 "keine_Anforderung" 1 "Halten" 2 "Parken" 3 "Halten_standby" 4 "Anfahren" 5 "Loesen_ueber_Rampe" 6 "Parken_mit_P" 7 "HMS_uebernehmen" ;
VAL_ 518 Parken_Fahrbereitschaft_Anf 0 "keine_Anforderung" 1 "Anforderung_Fahrbereitschaft" ;
VAL_ 518 Parken_Motorlauf_Anf 0 "Keine_Anforderung" 1 "Motor_aus" 2 "Motor_an" 3 "Weiterlauf_Fahreruebernahme" ;
VAL_ 518 IPA_TPA_ausgerichtetes_Parken 0 "nicht_aktiv" 1 "aktiv" ;
VAL_ 518 Parken_Notstopp_Anf 0 "Ueberwachung_aus" 1 "Ueberwachung_ein" 2 "Notstopp_ausloesen" ;
VAL_ 518 Parken_Anhalteweg_Anf 1022 "Neutralwert" 1023 "Fehler" ;
VAL_ 518 Parken_aktives_System 0 "kein_aktives_System" 1 "Manoevrierassistent_Ueberwachung" 2 "IPA" 3 "fernbedientes_Parken" 4 "Manoevrierassistent" 5 "Manoevrierassistent_quer" 6 "Anhaengerrangierassistent" 7 "fernbedienter_Anhaengerrangierassistent" ;
VAL_ 518 Parken_max_Beschleunigung 0 "Inaktiv" 122 "Init" 127 "Fehler" ;
VAL_ 518 Parken_QFK_KruemmSoll_VZ 0 "positiv" 1 "negativ" ;
VAL_ 518 Parken_QFK_AnfStat 1 "Init" 2 "Bereit" 4 "Eingriff" ;
VAL_ 518 Parken_Sollbeschleunigung 0 "Neutralwert" ;
VAL_ 518 Parken_Status_IPA_TSK 1 "IPA_TSK_Init" 2 "IPA_TSK_Fehler" 4 "IPA_TSK_aktivierbar" 5 "IPA_TSK_pausiert" 6 "IPA_TSK_aktiv" 8 "IPA_TSK_funktionsbereit" ;
VAL_ 518 Parken_erhoehtes_Moment 0 "keine_Anforderung" 1 "Anforderung_Rampe1" 2 "Anforderung_Rampe2" 3 "Anforderung_Rampe3" 4 "Anforderung_Rampe4" 5 "Anforderung_Rampe5" 6 "Anforderung_Rampe6" 7 "Anforderung_Rampe7" 8 "Anforderung_Rampe8" 9 "Anforderung_Rampe9" 10 "Anforderung_Rampe10" 11 "Anforderung_Rampe11" 12 "Anforderung_Rampe12" 13 "Anforderung_Rampe13" 14 "Anforderung_Rampe14" 15 "Anforderung_Rampe15" ;
VAL_ 518 Parken_max_Geschwindigkeit 0 "Inaktiv" 251 "Init" 255 "Fehler" ;
VAL_ 518 Parken_Soll_Anhalteweg_Anf 1022 "Neutralwert" 1023 "Fehler" ;
VAL_ 518 Parken_Fahrstufenwunsch 0 "Init" 1 "Fahrstufe_beibehalten" 2 "Position_R" 3 "Position_D" 4 "Position_N" ;
VAL_ 518 Parken_Schleichfahrt_Anf 0 "keine_Anforderung" 1 "Schleichfahrt_angefordert" ;
VAL_ 518 Parken_Bordstein_Winkel 0 "Neutralwert" ;
VAL_ 518 IPA_TPA_Remote 0 "nicht_aktiv" 1 "aktiv" 2 "Uebergabe" 3 "Uebernahme" ;
VAL_ 518 IPA_TPA_Remote_Anf 0 "keine_Anforderung" 1 "Remote_Anforderung" 2 "Remote_Zug_rueckgaengig" ;
VAL_ 518 IPA_TPA_Fehler 0 "Init_kein_Fehler" 1 "IPA_Systemfehler" 2 "RPA_Systemfehler" 3 "temporaerer_Fehler" 4 "sonstiger_Fehler" ;
VAL_ 518 IPA_TPA_Abbruch 0 "Init_kein_Abbruch" 1 "Hindernis" 2 "Manoever_nicht_fahrbar" 3 "Abbruch_mit_Wiederaufnahme" 4 "Abbruch_ohne_Wiederaufnahme" 5 "temporaerer_Fehler" 6 "sonstiger_Fehler" ;
VAL_ 518 IPA_TPA_Status 0 "deaktiv" 1 "Init" 4 "startbereit" 6 "Regelung_aktiv" 7 "Parkvorgang_abgeschlossen" 8 "funktionsbereit" 9 "Unterbrechung" 10 "Abbruch" 15 "Error" ;
VAL_ 2331595837 PCH_Object_Class 0 "unknown" 1 "reserved" 2 "reserved" 3 "pedestrian" 4 "reserved" 5 "bicycle" 6 "motorcycle" 7 "car" 8 "minimum_four_wheeler" 9 "truck" 10 "two_wheeler" 11 "reserved" 12 "minimum_two_wheeler" 13 "trailer" 15 "Init" ;
VAL_ 2331595837 PCH_Object_vAbsX 4095 "Init" ;
VAL_ 2331595837 PCH_Object_vAbsY 4095 "Init" ;
VAL_ 2331595837 PCH_Kritikalitaetsklasse 0 "keine_Kritikalitaet" 1 "Kritikalitaetsklasse_1" 2 "Kritikalitaetsklasse_2" 3 "Kritikalitaetsklasse_3" 4 "Kritikalitaetsklasse_4" ;
VAL_ 2331595837 PCH_MessZeitpunkt 8191 "Init" ;
VAL_ 2331595837 PCH_Status 0 "Init" 1 "Aktiv" 2 "Nicht_verfuegbar" 3 "Eingeschraenkt_Kalibrierung" 4 "Eingeschraenkt_Sensorsicht" 5 "Eingeschraenkt_Anhaengerbetrieb" 6 "Eingeschraenkt_Systemgrenze" 7 "Fehler" ;
VAL_ 2331595837 PCH_TTC 8190 "Init" 8191 "Fehler" ;
VAL_ 2331595837 PCH_Object_aAbsX 4095 "Init" ;
VAL_ 2331595837 PCH_Object_aAbsY 4095 "Init" ;
VAL_ 2331595837 PCH_Object_Width 255 "Init" ;
VAL_ 2331595837 PCH_Object_PosX 16383 "Init" ;
VAL_ 2331595837 PCH_Object_PosY 8191 "Init" ;
VAL_ 802 PCR_Sensorstatus 0 "Sensor_ok" 1 "Sensor_nok" ;
VAL_ 802 PCR_Obj_vx_rel 2047 "Fehler" ;
VAL_ 802 PCR_Obj_vy_rel 2047 "Fehler" ;
VAL_ 802 PCR_Obj_TTC 511 "Fehler" ;
VAL_ 802 PCR_Obj_Guete 127 "Fehler" ;
VAL_ 802 PCR_Crashwahrscheinlichkeit 127 "Fehler" ;
VAL_ 802 PCR_Sensorstatus_02 0 "Sensor_ok" 1 "zur_Zeit_eingeschraenkt" 2 "zur_Zeit_eingeschraenkt_keine_Sensorsicht" 3 "zur_Zeit_eingeschraenkt_Anhaengerbetrieb" 4 "Systemstoerung_SWA" ;
VAL_ 796 PCS_Li_MessZeitpunkt 8191 "Init" ;
VAL_ 796 PCS_Li_CW 126 "Init" 127 "Fehler" ;
VAL_ 796 PCS_Li_CW_Konfidenz 126 "Init" 127 "Fehler" ;
VAL_ 796 PCS_Li_CS 126 "Init" 127 "Fehler" ;
VAL_ 796 PCS_Li_CS_Konfidenz 126 "Init" 127 "Fehler" ;
VAL_ 796 PCS_Li_TTC 1022 "Init" 1023 "Fehler" ;
VAL_ 796 PCS_Li_TTC_StdAbw 126 "Init" 127 "Fehler" ;
VAL_ 796 PCS_Li_Status 0 "Init" 1 "Aktiv" 2 "Nicht_verfuegbar" 3 "Eingeschraenkt_Kalibrierung" 4 "Eingeschraenkt_Sensorsicht" 5 "Eingeschraenkt_Anhaengerbetrieb" 6 "Eingeschraenkt_Systemgrenze" 7 "Eingeschraenkt_Abschleppen" 15 "Fehler" ;
VAL_ 797 PCS_Re_MessZeitpunkt 8191 "Init" ;
VAL_ 797 PCS_Re_CW 126 "Init" 127 "Fehler" ;
VAL_ 797 PCS_Re_CW_Konfidenz 126 "Init" 127 "Fehler" ;
VAL_ 797 PCS_Re_CS 126 "Init" 127 "Fehler" ;
VAL_ 797 PCS_Re_CS_Konfidenz 126 "Init" 127 "Fehler" ;
VAL_ 797 PCS_Re_TTC 1022 "Init" 1023 "Fehler" ;
VAL_ 797 PCS_Re_TTC_StdAbw 126 "Init" 127 "Fehler" ;
VAL_ 797 PCS_Re_Status 0 "Init" 1 "Aktiv" 2 "Nicht_verfuegbar" 3 "Eingeschraenkt_Kalibrierung" 4 "Eingeschraenkt_Sensorsicht" 5 "Eingeschraenkt_Anhaengerbetrieb" 6 "Eingeschraenkt_Systemgrenze" 7 "Eingeschraenkt_Abschleppen" 15 "Fehler" ;
VAL_ 2527679685 PDC_ASM_Ereignis 0 "No_Event" 255 "ASM_Trigger" ;
VAL_ 2527679685 PDC_ASM_Zeitstempel_02 255 "Init" ;
VAL_ 770 PLA_QFK_AnfStat 1 "Init" 2 "Bereit" 4 "Eingriff" ;
VAL_ 770 PLA_QFK_KruemmSoll_VZ 0 "positiv" 1 "negativ" ;
VAL_ 770 PLA_05_Sendestatus 0 "langsamer_Zyklus" 1 "schneller_Zyklus" ;
VAL_ 770 PLA_QFK_KrSoll_VZ 0 "positiv" 1 "negativ" ;
VAL_ 319 PreCrash_Charisma_FahrPr 0 "keine_Funktion" 1 "Programm_1" 2 "Programm_2" 3 "Programm_3" 4 "Programm_4" 5 "Programm_5" 6 "Programm_6" 7 "Programm_7" 8 "Programm_8" 9 "Programm_9" 10 "Programm_10" 11 "Programm_11" 12 "Programm_12" 13 "Programm_13" 14 "Programm_14" 15 "Programm_15" ;
VAL_ 319 PreCrash_Charisma_Status 0 "Init" 1 "verfuegbar" 2 "nicht_verfuegbar" 3 "asynchron_durch_Fahrerwunsch" ;
VAL_ 319 PreCrash_Schiebedach_schliessen 0 "keine_Schliessung" 1 "Schliessung_angefordert" ;
VAL_ 319 PreCrash_Fenster_schliessen 0 "keine_Schliessung" 1 "Schliessung_angefordert" ;
VAL_ 319 PreCrash_Blinken 0 "keine_Blinkanforderung" 1 "Warnblinken" 2 "RECAS_Blinken" 3 "Notbremsblinken" ;
VAL_ 319 SC_PreSense_FCWP 0 "Warnung_gilt_fuer_Objekte" 1 "Warnung_gitl_fuer_Fussgaenger" ;
VAL_ 319 PreCrash_Tueren_Verriegeln 0 "keine_Anforderung" 1 "Tueren_Verriegeln" ;
VAL_ 319 PreCrash_FS_Laengsverstellung 0 "nicht_angefordert" 1 "angefordert" ;
VAL_ 319 PreCrash_Anforderung_AFR 0 "keine_Anforderung" 1 "linke_Seite" 2 "rechte_Seite" 3 "Vorderachse" 4 "Hinterachse" 5 "Vorwarnung" 7 "Init" ;
VAL_ 319 SC_PreCrash_LED 0 "keine_Anzeige" 1 "Stufe_1_glimmen" 2 "Stufe_2_leuchten" 3 "Stufe_3_blinken" ;
VAL_ 319 PreCrash_FS_Pneumatik_ansteuern 0 "keine_Anforderung" 1 "Pneumatik_ansteuern" ;
VAL_ 319 PreCrash_BFS_Pneumatik_ansteuern 0 "keine_Anforderung" 1 "Pneumatik_ansteuern" ;
VAL_ 319 PreCrash_Fo_Pneumatik_ansteuern 0 "keine_Anforderung" 1 "Pneumatik_ansteuern" ;
VAL_ 319 PreCrash_FS_Sitzlehne_verfahren 0 "keine_Anforderung" 1 "reserviert" 2 "reserviert" 3 "Sitzlehnenkopf_in_pos_xRichtung_verfahrenvor" 4 "Sitzlehnenkopf_in_neg_xRichtung_verfahrenzurueck" 6 "reserviert" 7 "Lehnenkopfverstellung_ansteuern" ;
VAL_ 319 PreCrash_BFS_Sitzlehne_verfahren 0 "keine_Anforderung" 1 "reserviert" 2 "reserviert" 3 "Sitzlehnenkopf_in_pos_xRichtung_verfahrenvor" 4 "Sitzlehnenkopf_in_neg_xRichtung_verfahrenzurueck" 6 "reserviert" 7 "Lehnenkopfverstellung_ansteuern" ;
VAL_ 319 PreCrash_Fo_Sitzlehne_verfahren 0 "keine_Anforderung" 1 "reserviert" 2 "reserviert" 3 "Sitzlehnenkopf_in_pos_xRichtung_verfahrenvor" 4 "Sitzlehnenkopf_in_neg_xRichtung_verfahrenzurueck" ;
VAL_ 319 PreCrash_FS_KSV_verfahren 0 "keine_Anforderung" 1 "in_pos_xRichtung_verfahren" 2 "in_neg_xRichung_verfahren" 3 "in_pos_zRichtung_verfahren" 4 "in_neg_zRichtung_verfahren" 5 "in_pos_xRichtung_und_neg_zRichtung_verfahren" 6 "in_pos_x_Richtung_und_pos_zRichtung_verfahren" 7 "in_neg_xRichtung_und_neg_zRichtung_verfahren" 8 "in_neg_xRichtung_und_pos_zRichtung_verfahren" 9 "Kopfstuetze_ansteuern" ;
VAL_ 319 PreCrash_BFS_KSV_verfahren 0 "keine_Anforderung" 1 "in_pos_xRichtung_verfahren" 2 "in_neg_xRichung_verfahren" 3 "in_pos_zRichtung_verfahren" 4 "in_neg_zRichtung_verfahren" 5 "in_pos_xRichtung_und_neg_zRichtung_verfahren" 6 "in_pos_x_Richtung_und_pos_zRichtung_verfahren" 7 "in_neg_xRichtung_und_neg_zRichtung_verfahren" 8 "in_neg_xRichtung_und_pos_zRichtung_verfahren" 9 "Kopfstuetze_ansteuern" ;
VAL_ 319 PreCrash_Fo_KSV_verfahren 0 "keine_Anforderung" 1 "in_pos_xRichtung_verfahren" 2 "in_neg_xRichung_verfahren" 3 "in_pos_zRichtung_verfahren" 4 "in_neg_zRichtung_verfahren" 5 "in_pos_xRichtung_und_neg_zRichtung_verfahren" 6 "in_pos_x_Richtung_und_pos_zRichtung_verfahren" 7 "in_neg_xRichtung_und_neg_zRichtung_verfahren" 8 "in_neg_xRichtung_und_pos_zRichtung_verfahren" ;
VAL_ 319 PreCrash_BFS_Laengsverstellung 0 "nicht_angefordert" 1 "angefordert" ;
VAL_ 319 SC_PreCrash_Warnung 0 "keine_Anzeige" 1 "latente_Vorwarnung" 2 "Vorwarnung" 3 "Akutwarnung" 4 "Eingriff" 5 "Fahreruebernahmeaufforderung" 6 "Abbiegewarnung" 7 "Basiseingriff" 8 "Heckeingriff" ;
VAL_ 319 SC_PreCrash_Texte 0 "keine_Anzeige" 1 "Systemstoerung" 2 "keine_Sensorsicht" 3 "Demomodus" 4 "System_aus" 5 "Anhaengerbetrieb" 6 "ESC_aus" 7 "zurzeit_eingeschraenkt" 8 "zurzeit_eingeschraenkt_ESP_Aus" 9 "Initialisierung" ;
VAL_ 317 QFK_01_Sendestatus 0 "langsamer_Zyklus" 1 "schneller_Zyklus" ;
VAL_ 317 QFK_stEingriffBr 0 "kein_Eingriff" 1 "Eingriff_aktiv" ;
VAL_ 317 QFK_DynBegr_aktiv 0 "nicht_aktiv" 1 "aktiv" ;
VAL_ 317 QFK_Anf_Giermomoffset_VZ 0 "positiv" 1 "negativ" ;
VAL_ 317 QFK_Status 1 "Init" 2 "Bereit" 3 "Gesperrt" 4 "Eingriff" 5 "Abbruch" 6 "FehlerME" 7 "FehlerOE" 12 "EingriffED" 13 "Eingriff_HandsOff" ;
VAL_ 317 QFK_stHCA 0 "Deaktiv" 1 "Init" 2 "Bereit" 3 "Gesperrt" 4 "Eingriff" 5 "Abbruch" 6 "FehlerME" 7 "FehlerOE" 12 "EingriffED" ;
VAL_ 317 QFK_stPLA 0 "Deaktiv" 1 "Init" 2 "Bereit" 3 "Gesperrt" 4 "Eingriff" 5 "Abbruch" 6 "FehlerME" 7 "FehlerOE" 12 "EingriffED" ;
VAL_ 317 QFK_stAWV 0 "Deaktiv" 1 "Init" 2 "Bereit" 3 "Gesperrt" 4 "Eingriff" 5 "Abbruch" 6 "FehlerME" 7 "FehlerOE" 12 "EingriffED" ;
VAL_ 317 QFK_stDSR 0 "Deaktiv" 1 "Init" 2 "Bereit" 3 "Gesperrt" 4 "Eingriff" 5 "Abbruch" 6 "FehlerME" 7 "FehlerOE" 12 "EingriffED" ;
VAL_ 317 QFK_ZPosIst_VZ 0 "positiv" 1 "negativ" ;
VAL_ 317 QFK_KrIst_VZ 0 "positiv" 1 "negativ" ;
VAL_ 317 QFK_IstKraft_VZ 0 "positiv" 1 "negativ" ;
VAL_ 317 QFK_KruemmIst_VZ 0 "positiv" 1 "negativ" ;
VAL_ 317 QFK_IstKraftNiveau_VZ 0 "positiv" 1 "negativ" ;
VAL_ 317 QFK_ZPosIst 65535 "Inaktiv" ;
VAL_ 317 QFK_stRHP 0 "Deaktiv" 1 "Init" 2 "Bereit" 3 "Gesperrt" 4 "Eingriff" 5 "Abbruch" 6 "FehlerME" 7 "FehlerOE" 12 "EingriffED" 13 "Eingriff_HandsOff" ;
VAL_ 317 QFK_KrIst 65534 "Init" 65535 "Fehler" ;
VAL_ 317 QFK_IstKraft 1022 "Init" 1023 "Fehler" ;
VAL_ 1023 Quersperre_Anz_Sperre_Einlegen 0 "Quersperre_nicht_einlegen" 1 "Quersperre_einlegen" ;
VAL_ 1023 Quersperre_Anz_Sperre_Auslegen 0 "Quersperre_nicht_auslegen" 1 "Quersperre_auslegen" ;
VAL_ 1023 Quersperre_Anz_Sperre_Geschl 0 "Quersperre_nicht_eingelegt" 1 "Sperre_eingelegt" ;
VAL_ 1023 Quersperre_Status 0 "Sperre_offen" 1 "Sperre_geschlossen" 2 "Fehler_Sperre_offen" 3 "Fehler_Sperre_geschlossen" ;
VAL_ 1023 Quersperre_Istzustand 0 "Init" 1 "geschlossen" 2 "offen" 7 "Fehler" ;
VAL_ 1616 RA_Radio_Error_Flag 0 "kein_KD_Fehler" 1 "KD_Fehler" ;
VAL_ 1616 RA_Frequency_unit 0 "1_kHz" 1 "100_kHz" ;
VAL_ 1616 RA_AM_Tuning 0 "frequency_locked" 1 "AM_tuning" ;
VAL_ 695 RCTA_PaCo_MainState 0 "Init" 1 "InOperation_NoError" 7 "Fehler" ;
VAL_ 695 RCTA_Status_FoD 0 "Init" 1 "keine_FoD_Freischaltung" 2 "FoD_Freischaltung" ;
VAL_ 695 RCTA_PaCo_BrakeIntervention 0 "Inactive" 1 "Active" ;
VAL_ 695 RCTA_PaCo_UnavailableReason 0 "No_Reason" 1 "Trailer_Hitched" ;
VAL_ 695 RCTA_Anf_Warnruck 0 "Init_kein_Warnruck" 1 "schwacher_Warnruck" 2 "mittlerer_Warnruck" 3 "starker_Warnruck" ;
VAL_ 695 RCTA_Modus 0 "kein_Fehler_verfuegbar" 1 "Eingriffsmute" 2 "eingeschraenkt_Verfuegbar_pata2_Warnruck_etc" 3 "Anhaengerbetrieb" 4 "Init_nicht_codiert" 5 "keine_Sensorsicht_Blindheit" 6 "zur_Zeit_nicht_verfuegbar_temp_Fehler" 7 "Systemstoerung_dauer_Fehler" ;
VAL_ 695 RCTA_Kritikalitaetslevel_rechts 0 "unkritisch" 1 "Kritikalitaetslevel_1" 2 "Kritikalitaetslevel_2" 3 "Kritikalitaetslevel_3" 4 "Kritikalitaetslevel_4" 5 "Kritikalitaetslevel_5" 6 "reserviert" 7 "nicht_bewertbar" ;
VAL_ 695 RCTA_Kritikalitaetslevel_links 0 "unkritisch" 1 "Kritikalitaetslevel_1" 2 "Kritikalitaetslevel_2" 3 "Kritikalitaetslevel_3" 4 "Kritikalitaetslevel_4" 5 "Kritikalitaetslevel_5" 6 "reserviert" 7 "nicht_bewertbar" ;
VAL_ 695 RCTA_Info_rechts 0 "RCTA_hat_rechts_nichts_erkannt" 1 "RCTA_hat_rechts_blind_erkannt" 2 "RCTA_hat_rechts_frei_erkannt" 3 "RCTA_hat_rechts_unkritisch_erkannt" 4 "RCTA_hat_rechts_relevant_aber_unkritisch_erkannt" 5 "RCTA_hat_rechts_kritisch_erkannt" 6 "RCTA_hat_rechts_sehr_kritisch_erkannt" 7 "RCTA_meldet_rechts_Kollision_steht_bevor" ;
VAL_ 695 RCTA_Anforderung_HMS 0 "keine Anforderung" 1 "halten" 2 "parken" 3 "Halten Standby" 4 "anfahren" 5 "loesen_ueber_Rampe" ;
VAL_ 695 RCTA_Bremsruck_Anforderung 0 "nicht_angefordert" 1 "angefordert" ;
VAL_ 695 RCTA_Bremsruck_Freigabe 0 "keine_Freigabe" 1 "Freigabe" ;
VAL_ 695 RCTA_Info_links 0 "RCTA_hat_links_nichts_erkannt" 1 "RCTA_hat_links_blind_erkannt" 2 "RCTA_hat_links_frei_erkannt" 3 "RCTA_hat_links_unkritisch_erkannt" 4 "RCTA_hat_links_relevant_aber_unkritisch_erkannt" 5 "RCTA_hat_links_kritisch_erkannt" 6 "RCTA_hat_links_sehr_kritisch_erkannt" 7 "RCTA_meldet_links_Kollision_steht_bevor" ;
VAL_ 695 RCTA_PaCo_BrakingPossible 0 "Not_Possible" 1 "Possible" ;
VAL_ 695 RCTA_Status 0 "Aus" 1 "Passiv" 2 "Aktiv" 3 "Fehler" ;
VAL_ 695 RCTA_Warnton 0 "Aus" 1 "Ein" ;
VAL_ 695 RCTA_Notbremsung_Freigabe 0 "keine_Freigabe" 1 "Freigabe" ;
VAL_ 695 RCTA_Notbremsung_Anforderung 0 "Init" 255 "Fehler" ;
